VERSION ""

NS_ :

BS_:

BU_: ACU ALC BCM ESCL HFM HPCU HVAC_CU LCU_ADB LCU_MBL MainLiB12V USM eRDC_L eRDC_R

BO_ 32 ACU_A102: 8 ACU
  SG_ AirbagCrashOrder_v3 : 5|6@0+ (1,0) [0|0] "" BCM,HFM,HVAC_CU,eRDC_L,eRDC_R
  SG_ Clock_ACU_A102 : 7|2@0+ (1,0) [0|3] "" BCM,eRDC_L,eRDC_R
  SG_ DirectionRear2ndCollision : 8|1@0+ (1,0) [0|0] "" BCM
  SG_ DirectionRollover2ndCollision : 9|1@0+ (1,0) [0|0] "" BCM
  SG_ DataSetCollisionValidity : 10|1@0+ (1,0) [0|0] "" BCM
  SG_ SeatBeltStatusDriver1stCollision : 12|2@0+ (1,0) [0|0] "" BCM
  SG_ SeatBeltStatusPass1stCollision : 14|2@0+ (1,0) [0|0] "" BCM
  SG_ DirectionLeft1stCollision : 15|1@0+ (1,0) [0|0] "" BCM
  SG_ PreRolloverDetection : 16|1@0+ (1,0) [0|0] "" BCM
  SG_ SeatBeltStatusDriver2ndCollision : 18|2@0+ (1,0) [0|0] "" BCM
  SG_ SeatBeltStatusPass2ndcollision : 20|2@0+ (1,0) [0|0] "" BCM
  SG_ DirectionLeft2ndCollision : 21|1@0+ (1,0) [0|0] "" BCM
  SG_ DirectionRight2ndCollision : 22|1@0+ (1,0) [0|0] "" BCM
  SG_ DirectionFront2ndCollision : 23|1@0+ (1,0) [0|0] "" BCM
  SG_ MaxDeltaVLongi1stCollision : 31|8@0+ (1,-100) [-100|100] "Kph" BCM
  SG_ MaxDeltaVLat1stCollision : 39|8@0+ (1,-100) [-100|100] "Kph" BCM
  SG_ MaxDeltaVLongi2ndCollision : 47|8@0+ (1,-100) [-100|100] "Kph" BCM
  SG_ MaxDeltaVLat2ndCollision : 55|8@0+ (1,-100) [-100|100] "Kph" BCM
  SG_ DirectionRollover1stCollision : 56|1@0+ (1,0) [0|0] "" BCM
  SG_ RolloverDetection : 57|1@0+ (1,0) [0|0] "" BCM
  SG_ CrashLevelType : 60|3@0+ (1,0) [0|0] "" BCM
  SG_ DirectionRight1stCollision : 61|1@0+ (1,0) [0|0] "" BCM
  SG_ DirectionFront1stCollision : 62|1@0+ (1,0) [0|0] "" BCM
  SG_ DirectionRear1stCollision : 63|1@0+ (1,0) [0|0] "" BCM

BO_ 114 EBA_A101: 7 BCM
  SG_ BrakePedalPosition : 23|12@0+ (0.03125,0) [0|100] "%" ACU

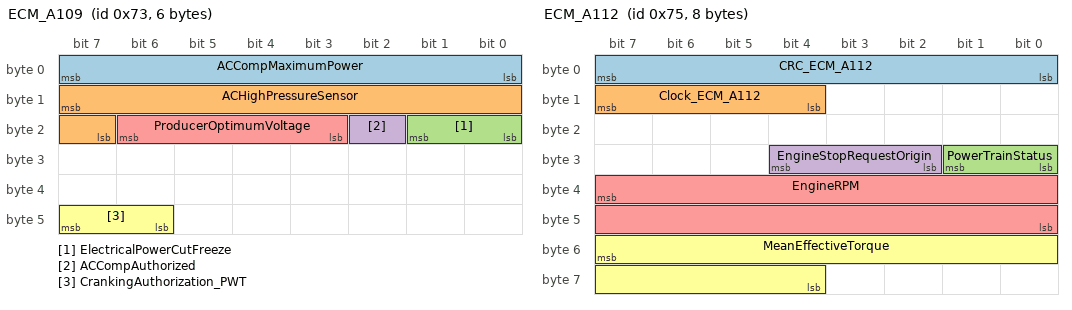
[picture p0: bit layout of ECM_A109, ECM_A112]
BO_ 115 ECM_A109: 6 BCM
  SG_ ACCompMaximumPower : 7|8@0+ (25,0) [0|6350] "W" HVAC_CU
  SG_ ACHighPressureSensor : 15|9@0+ (0.1,0) [0|51] "bar" HPCU,HVAC_CU
  SG_ ElectricalPowerCutFreeze : 17|2@0+ (1,0) [0|0] "" HVAC_CU
  SG_ ACCompAuthorized : 18|1@0+ (1,0) [0|0] "" HVAC_CU,USM
  SG_ ProducerOptimumVoltage : 22|4@0+ (0.5,12) [12|16] "V" USM
  SG_ CrankingAuthorization_PWT : 47|2@0+ (1,0) [0|0] "" USM

BO_ 116 ECM_A110: 8 BCM
  SG_ RawSensor : 17|10@0+ (0.125,0) [0|125] "%" ACU
  SG_ StopAutoPhase : 47|3@0+ (1,0) [0|0] "" HVAC_CU

BO_ 117 ECM_A112: 8 BCM
  SG_ CRC_ECM_A112 : 7|8@0+ (1,0) [0|255] "" USM
  SG_ Clock_ECM_A112 : 15|4@0+ (1,0) [0|15] "" USM
  SG_ PowerTrainStatus : 25|2@0+ (1,0) [0|0] "" HFM,HVAC_CU,USM
  SG_ EngineStopRequestOrigin : 28|3@0+ (1,0) [0|0] "" HFM,HVAC_CU
  SG_ EngineRPM : 39|16@0+ (0.125,0) [0|8191.75] "rpm" ACU,HVAC_CU,LCU_MBL
  SG_ MeanEffectiveTorque : 55|12@0+ (0.5,-400) [-400|1647] "Nm" HVAC_CU

BO_ 168 STRG_A1: 7 BCM
  SG_ CRC_STRG_A1 : 7|8@0+ (1,0) [0|255] "" USM
  SG_ Clock_STRG_A1 : 15|4@0+ (1,0) [0|15] "" USM
  SG_ SteeringWheelAngleRaw : 22|15@0+ (0.1,-1080) [-1080|1080] "°" ACU,LCU_ADB,LCU_MBL,USM
  SG_ SwaSensorInternalStatus : 39|3@0+ (1,0) [0|0] "" LCU_ADB,LCU_MBL,USM

BO_ 171 VDC_A6: 8 BCM
  SG_ CRC_VDC_A6 : 7|8@0+ (1,0) [0|255] "" USM
  SG_ YawRateCorrected : 10|11@0+ (0.1,-100) [-100|100] "°/s" ACU
  SG_ Clock_VDC_A6 : 15|4@0+ (1,0) [0|15] "" USM
  SG_ SteerRackPinionAngleCorrect : 39|15@0+ (0.1,-1080) [-1080|1080] "°" LCU_ADB,LCU_MBL,USM
  SG_ YawRateRaw : 55|11@0+ (0.1,-100) [-100|100] "°/s" LCU_ADB

BO_ 255 VDC_A10: 6 BCM
  SG_ AEB_BrakingPerformanceStatus : 9|2@0+ (1,0) [0|0] "" ACU
  SG_ BrakePedalPressedByDriver : 42|2@0+ (1,0) [0|0] "" ACU

BO_ 303 ATCU_A108: 7 BCM
  SG_ CRC_ATCU_A108 : 7|8@0+ (1,0) [0|255] "" USM
  SG_ Clock_ATCU_A108 : 15|4@0+ (1,0) [0|15] "" USM
  SG_ InputShaftRevolution : 16|16@0+ (1,0) [0|65534] "rpm" ACU
  SG_ GearLeverPosition_v2 : 20|4@0+ (1,0) [0|0] "" ACU,HVAC_CU,USM,eRDC_L,eRDC_R
  SG_ AT_StartingAuthorization : 23|3@0+ (1,0) [0|0] "" USM

BO_ 380 STRG_A2: 7 BCM
  SG_ CRC_STRG_A2 : 7|8@0+ (1,0) [0|255] "" USM
  SG_ Clock_STRG_A2 : 15|4@0+ (1,0) [0|15] "" USM
  SG_ SteeringWheelAngleRaw_EPS : 22|15@0+ (0.1,-1080) [-1080|1080] "°" ACU,LCU_ADB,USM
  SG_ SwaSensorInternalStatus_EPS : 39|3@0+ (1,0) [0|0] "" LCU_ADB,USM

BO_ 504 EPKB_R1: 3 BCM
  SG_ EPB_ActivationCounterMemorized : 7|20@0+ (1,0) [0|1000000] "-" USM

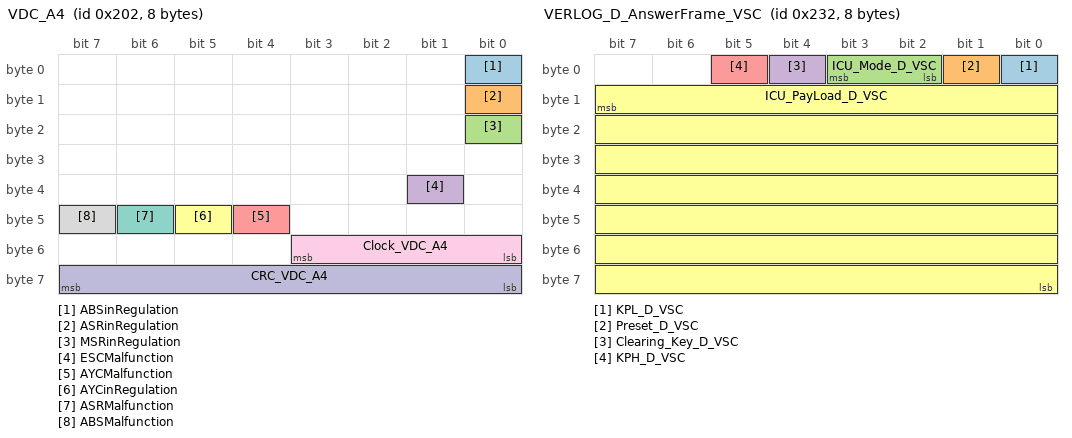
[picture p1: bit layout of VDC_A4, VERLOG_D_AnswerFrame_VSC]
BO_ 514 VDC_A4: 8 BCM
  SG_ ABSinRegulation : 0|1@0+ (1,0) [0|0] "" ACU
  SG_ ASRinRegulation : 8|1@0+ (1,0) [0|0] "" ACU
  SG_ MSRinRegulation : 16|1@0+ (1,0) [0|0] "" ACU
  SG_ ESCMalfunction : 33|1@0+ (1,0) [0|0] "" ACU
  SG_ AYCMalfunction : 44|1@0+ (1,0) [0|0] "" ACU
  SG_ AYCinRegulation : 45|1@0+ (1,0) [0|0] "" ACU
  SG_ ASRMalfunction : 46|1@0+ (1,0) [0|0] "" ACU
  SG_ ABSMalfunction : 47|1@0+ (1,0) [0|0] "" ACU
  SG_ Clock_VDC_A4 : 51|4@0+ (1,0) [0|15] "" ACU
  SG_ CRC_VDC_A4 : 63|8@0+ (1,0) [0|255] "" ACU

BO_ 538 HEVC_A125: 4 BCM
  SG_ ePedalStatus : 17|1@0+ (1,0) [0|0] "" ACU

BO_ 546 USM_A102: 4 USM
  SG_ ProducerVoltageRequest : 7|8@0+ (0.025,11.7) [11.7|16] "V" BCM
  SG_ BatteryCurrentSensorValue : 15|10@0+ (1,-320) [-320|320] "A" BCM
  SG_ ElecPowerConsumedByAux_v2 : 21|6@0+ (80,0) [0|4960] "W" BCM
  SG_ ACCompValveDefault : 29|1@0+ (1,0) [0|0] "" BCM,HVAC_CU
  SG_ ACCompClutchStatus : 31|1@0+ (1,0) [0|0] "" BCM,HVAC_CU

BO_ 562 VERLOG_D_AnswerFrame_VSC: 8 HFM
  SG_ KPL_D_VSC : 0|1@0+ (1,0) [0|0] "" BCM
  SG_ Preset_D_VSC : 1|1@0+ (1,0) [0|0] "" BCM
  SG_ ICU_Mode_D_VSC : 3|2@0+ (1,0) [0|0] "" BCM
  SG_ Clearing_Key_D_VSC : 4|1@0+ (1,0) [0|0] "" BCM
  SG_ KPH_D_VSC : 5|1@0+ (1,0) [0|0] "" BCM
  SG_ ICU_PayLoad_D_VSC : 15|56@0+ (1,0) [0|0] "" BCM

BO_ 566 VERLOG_D_ChallengeFrame: 8 BCM
  SG_ TPU_Mode_D : 1|2@0+ (1,0) [0|0] "" HFM
  SG_ VerlogStatus_D : 2|1@0+ (1,0) [0|0] "" HFM
  SG_ SREM_D : 3|1@0+ (1,0) [0|0] "" HFM
  SG_ Version_D : 5|2@0+ (1,0) [0|0] "" HFM
  SG_ TPU_Payload_D : 15|56@0+ (1,0) [0|0] "" HFM

BO_ 604 EPKB_A1: 4 BCM
  SG_ ParkingBrakeMalfunctionStatus : 23|1@0+ (1,0) [0|0] "" ACU

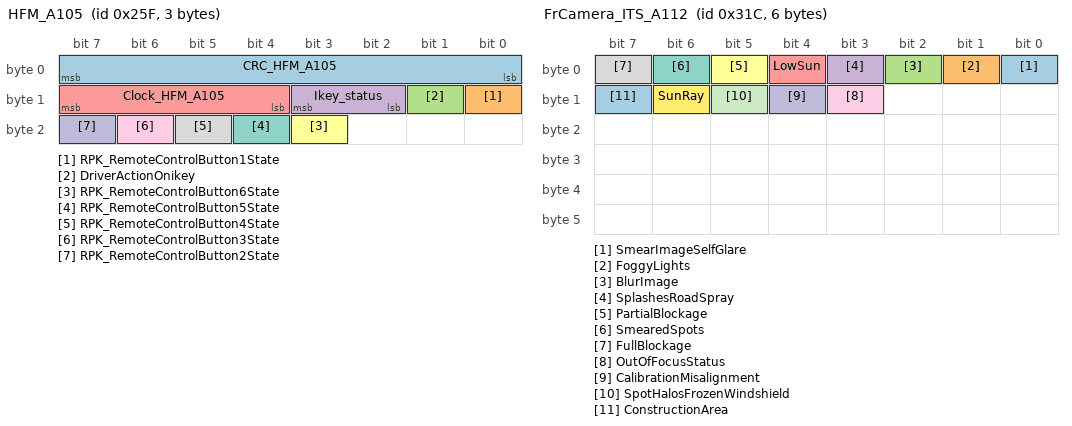
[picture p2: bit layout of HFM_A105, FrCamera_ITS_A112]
BO_ 607 HFM_A105: 3 HFM
  SG_ CRC_HFM_A105 : 7|8@0+ (1,0) [0|255] "" BCM
  SG_ RPK_RemoteControlButton1State : 8|1@0+ (1,0) [0|0] "" BCM
  SG_ DriverActionOnikey : 9|1@0+ (1,0) [0|0] "" BCM
  SG_ Ikey_status : 11|2@0+ (1,0) [0|0] "" BCM
  SG_ Clock_HFM_A105 : 15|4@0+ (1,0) [0|15] "" BCM
  SG_ RPK_RemoteControlButton6State : 19|1@0+ (1,0) [0|0] "" BCM
  SG_ RPK_RemoteControlButton5State : 20|1@0+ (1,0) [0|0] "" BCM
  SG_ RPK_RemoteControlButton4State : 21|1@0+ (1,0) [0|0] "" BCM
  SG_ RPK_RemoteControlButton3State : 22|1@0+ (1,0) [0|0] "" BCM
  SG_ RPK_RemoteControlButton2State : 23|1@0+ (1,0) [0|0] "" BCM

BO_ 650 VDC_A9: 8 BCM
  SG_ VehicleSpeed : 39|16@0+ (0.01,0) [0|655.34] "km/h" ACU,ESCL,HFM,HPCU,HVAC_CU,LCU_ADB,LCU_MBL,USM,eRDC_L,eRDC_R
  SG_ VehicleSpeedClock : 51|4@0+ (1,0) [0|15] "" ACU,ESCL,HFM,USM,eRDC_L,eRDC_R
  SG_ VehicleSpeedCRC : 63|8@0+ (1,0) [0|255] "" ACU,ESCL,HFM,USM,eRDC_L,eRDC_R

BO_ 791 HVAC_A1: 8 HVAC_CU
  SG_ BlowerFanMotorStatus_AC : 0|1@0+ (1,0) [0|0] "" BCM
  SG_ ACCompValveRequest : 7|7@0+ (0.01,0) [0|1] "A" BCM,USM
  SG_ FrontDefrostRequest : 8|1@0+ (1,0) [0|0] "" BCM
  SG_ EngineFanSpeedRequestPWM_AC : 15|7@0+ (1,0) [0|100] "%" BCM
  SG_ ACCompRequest : 16|1@0+ (1,0) [0|0] "" BCM
  SG_ MinimumVoltagebyAC : 19|3@0+ (0.5,12) [12|15] "V" USM
  SG_ PTCNumberThermalRequest : 23|4@0+ (1,0) [0|0] "" BCM
  SG_ PumpActivationRequest : 25|2@0+ (1,0) [0|0] "" USM
  SG_ AC_StopAutoForbidden : 29|2@0+ (1,0) [0|0] "" BCM
  SG_ AC_ClutchOpenForbidden : 31|2@0+ (1,0) [0|0] "" BCM
  SG_ ClimAT_EcoCustomAllowed : 32|1@0+ (1,0) [0|0] "" BCM
  SG_ RearDefrostRequest : 36|1@0+ (1,0) [0|0] "" BCM
  SG_ CoolerHilimitRequestForCVT : 37|1@0+ (1,0) [0|0] "" BCM
  SG_ VoltageRatebyAC : 39|2@0+ (1,0) [0|0] "" USM
  SG_ AC_eCompInterlockHVconnector : 41|2@0+ (1,0) [0|0] "" BCM
  SG_ ISS_EcoActivationState : 43|2@0+ (1,0) [0|0] "" BCM
  SG_ AirCondEcoActivationState : 45|2@0+ (1,0) [0|0] "" BCM
  SG_ AC_ePTCInterlockHVconnector : 47|2@0+ (1,0) [0|0] "" BCM
  SG_ ClimECOModeStatusDisplay : 52|2@0+ (1,0) [0|0] "" BCM
  SG_ HVAC_ZEVmodeICEngineStartRequest : 53|1@0+ (1,0) [0|0] "" BCM
  SG_ ACCompPowerUsed_HVAC_v2 : 63|8@0+ (25,0) [0|6350] "W" BCM

BO_ 796 FrCamera_ITS_A112: 6 BCM
  SG_ SmearImageSelfGlare : 0|1@0+ (1,0) [0|0] "" LCU_ADB
  SG_ FoggyLights : 1|1@0+ (1,0) [0|0] "" LCU_ADB
  SG_ BlurImage : 2|1@0+ (1,0) [0|0] "" LCU_ADB
  SG_ SplashesRoadSpray : 3|1@0+ (1,0) [0|0] "" LCU_ADB
  SG_ LowSun : 4|1@0+ (1,0) [0|0] "" LCU_ADB
  SG_ PartialBlockage : 5|1@0+ (1,0) [0|0] "" LCU_ADB
  SG_ SmearedSpots : 6|1@0+ (1,0) [0|0] "" LCU_ADB
  SG_ FullBlockage : 7|1@0+ (1,0) [0|0] "" LCU_ADB
  SG_ OutOfFocusStatus : 11|1@0+ (1,0) [0|0] "" LCU_ADB
  SG_ CalibrationMisalignment : 12|1@0+ (1,0) [0|0] "" LCU_ADB
  SG_ SpotHalosFrozenWindshield : 13|1@0+ (1,0) [0|0] "" LCU_ADB
  SG_ SunRay : 14|1@0+ (1,0) [0|0] "" LCU_ADB
  SG_ ConstructionArea : 15|1@0+ (1,0) [0|0] "" LCU_ADB

BO_ 806 USM_R3: 2 USM
  SG_ FrontHeightBody : 7|8@0+ (1.5,-190.5) [-190.5|190.5] "mm" BCM
  SG_ RearHeightBody : 15|8@0+ (1.5,-190.5) [-190.5|190.5] "mm" BCM

BO_ 811 BCM_R18: 6 BCM
  SG_ MinimumVoltageByBCM : 26|3@0+ (0.5,12) [12|15] "V" USM
  SG_ BCM_ACCompRequest : 29|1@0+ (1,0) [0|0] "" HVAC_CU
  SG_ VoltageRateByBCM : 31|2@0+ (1,0) [0|0] "" USM
  SG_ BCM_PumpActivationRequest : 35|2@0+ (1,0) [0|0] "" USM

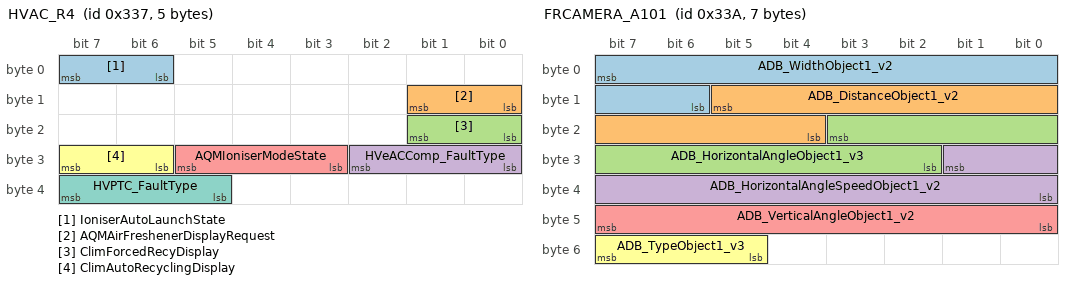
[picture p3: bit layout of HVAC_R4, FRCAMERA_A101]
BO_ 823 HVAC_R4: 5 HVAC_CU
  SG_ IoniserAutoLaunchState : 7|2@0+ (1,0) [0|0] "" BCM
  SG_ AQMAirFreshenerDisplayRequest : 9|2@0+ (1,0) [0|0] "" BCM
  SG_ ClimForcedRecyDisplay : 17|2@0+ (1,0) [0|0] "" BCM
  SG_ HVeACComp_FaultType : 26|3@0+ (1,0) [0|0] "" BCM
  SG_ AQMIoniserModeState : 29|3@0+ (1,0) [0|0] "" BCM
  SG_ ClimAutoRecyclingDisplay : 31|2@0+ (1,0) [0|0] "" BCM
  SG_ HVPTC_FaultType : 39|3@0+ (1,0) [0|0] "" BCM

BO_ 826 FRCAMERA_A101: 7 BCM
  SG_ ADB_WidthObject1_v2 : 7|10@0+ (0.1,0) [0|52] "°" LCU_ADB
  SG_ ADB_DistanceObject1_v2 : 13|10@0+ (1,0) [0|1022] "m" LCU_ADB
  SG_ ADB_HorizontalAngleObject1_v3 : 19|10@0+ (0.1,-50) [-50|50] "°" LCU_ADB
  SG_ ADB_HorizontalAngleSpeedObject1_v2 : 25|10@0+ (0.1,-30) [-30|30] "°/s" LCU_ADB
  SG_ ADB_VerticalAngleObject1_v2 : 47|8@0+ (0.1,-10) [-10|10] "°" LCU_ADB
  SG_ ADB_TypeObject1_v3 : 55|3@0+ (1,0) [0|0] "" LCU_ADB

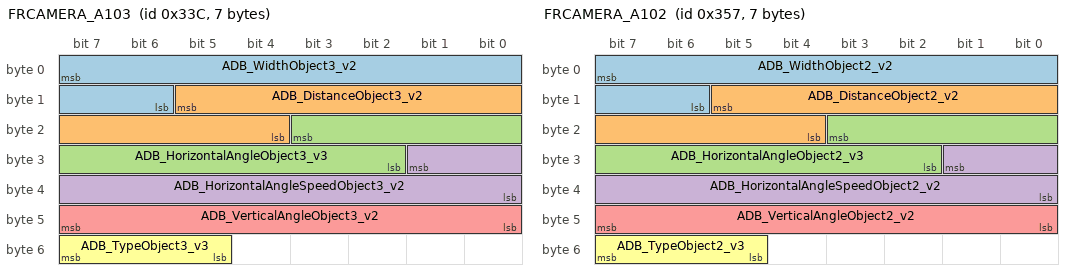
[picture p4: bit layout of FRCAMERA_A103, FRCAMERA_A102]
BO_ 828 FRCAMERA_A103: 7 BCM
  SG_ ADB_WidthObject3_v2 : 7|10@0+ (0.1,0) [0|52] "°" LCU_ADB
  SG_ ADB_DistanceObject3_v2 : 13|10@0+ (1,0) [0|1022] "m" LCU_ADB
  SG_ ADB_HorizontalAngleObject3_v3 : 19|10@0+ (0.1,-50) [-50|50] "°" LCU_ADB
  SG_ ADB_HorizontalAngleSpeedObject3_v2 : 25|10@0+ (0.1,-30) [-30|30] "°/s" LCU_ADB
  SG_ ADB_VerticalAngleObject3_v2 : 47|8@0+ (0.1,-10) [-10|10] "°" LCU_ADB
  SG_ ADB_TypeObject3_v3 : 55|3@0+ (1,0) [0|0] "" LCU_ADB

BO_ 855 FRCAMERA_A102: 7 BCM
  SG_ ADB_WidthObject2_v2 : 7|10@0+ (0.1,0) [0|52] "°" LCU_ADB
  SG_ ADB_DistanceObject2_v2 : 13|10@0+ (1,0) [0|1022] "m" LCU_ADB
  SG_ ADB_HorizontalAngleObject2_v3 : 19|10@0+ (0.1,-50) [-50|50] "°" LCU_ADB
  SG_ ADB_HorizontalAngleSpeedObject2_v2 : 25|10@0+ (0.1,-30) [-30|30] "°/s" LCU_ADB
  SG_ ADB_VerticalAngleObject2_v2 : 47|8@0+ (0.1,-10) [-10|10] "°" LCU_ADB
  SG_ ADB_TypeObject2_v3 : 55|3@0+ (1,0) [0|0] "" LCU_ADB

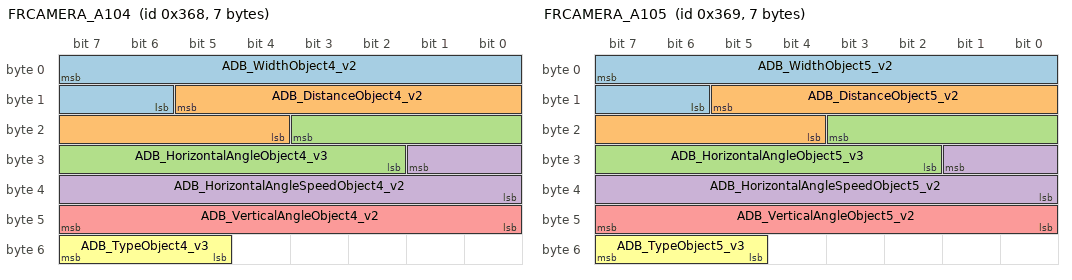
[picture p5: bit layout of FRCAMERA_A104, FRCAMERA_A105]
BO_ 872 FRCAMERA_A104: 7 BCM
  SG_ ADB_WidthObject4_v2 : 7|10@0+ (0.1,0) [0|52] "°" LCU_ADB
  SG_ ADB_DistanceObject4_v2 : 13|10@0+ (1,0) [0|1022] "m" LCU_ADB
  SG_ ADB_HorizontalAngleObject4_v3 : 19|10@0+ (0.1,-50) [-50|50] "°" LCU_ADB
  SG_ ADB_HorizontalAngleSpeedObject4_v2 : 25|10@0+ (0.1,-30) [-30|30] "°/s" LCU_ADB
  SG_ ADB_VerticalAngleObject4_v2 : 47|8@0+ (0.1,-10) [-10|10] "°" LCU_ADB
  SG_ ADB_TypeObject4_v3 : 55|3@0+ (1,0) [0|0] "" LCU_ADB

BO_ 873 FRCAMERA_A105: 7 BCM
  SG_ ADB_WidthObject5_v2 : 7|10@0+ (0.1,0) [0|52] "°" LCU_ADB
  SG_ ADB_DistanceObject5_v2 : 13|10@0+ (1,0) [0|1022] "m" LCU_ADB
  SG_ ADB_HorizontalAngleObject5_v3 : 19|10@0+ (0.1,-50) [-50|50] "°" LCU_ADB
  SG_ ADB_HorizontalAngleSpeedObject5_v2 : 25|10@0+ (0.1,-30) [-30|30] "°/s" LCU_ADB
  SG_ ADB_VerticalAngleObject5_v2 : 47|8@0+ (0.1,-10) [-10|10] "°" LCU_ADB
  SG_ ADB_TypeObject5_v3 : 55|3@0+ (1,0) [0|0] "" LCU_ADB

BO_ 878 ECM_INIT_INFO_RN1: 7 BCM
  SG_ StarterActivationCounter : 7|16@0+ (10,0) [0|600000] "" USM
  SG_ HPPumpActivationCounter : 23|16@0+ (10,0) [0|600000] "" USM
  SG_ BSGActivationCounter : 39|21@0+ (1,0) [0|1500000] "nb of restart" USM

BO_ 893 EPS_A103: 3 BCM
  SG_ MinimumVoltagebySteer : 5|3@0+ (0.5,12) [12|15] "V" USM

BO_ 908 HFM_N101: 4 HFM
  SG_ VirutalKeyRKE_Request : 7|28@0+ (1,0) [0|0] "" BCM

BO_ 911 HVAC_A111: 1 HVAC_CU
  SG_ FrontRightDefrostRequest : 6|1@0+ (1,0) [0|0] "" BCM
  SG_ FrontLeftDefrostRequest : 7|1@0+ (1,0) [0|0] "" BCM

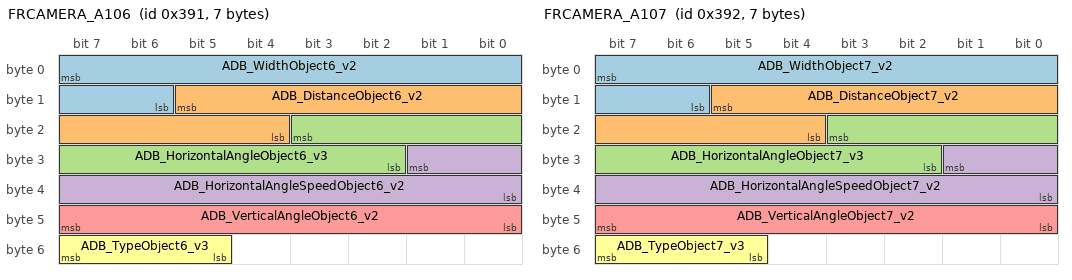
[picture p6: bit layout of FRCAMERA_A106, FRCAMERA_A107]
BO_ 913 FRCAMERA_A106: 7 BCM
  SG_ ADB_WidthObject6_v2 : 7|10@0+ (0.1,0) [0|52] "°" LCU_ADB
  SG_ ADB_DistanceObject6_v2 : 13|10@0+ (1,0) [0|1022] "m" LCU_ADB
  SG_ ADB_HorizontalAngleObject6_v3 : 19|10@0+ (0.1,-50) [-50|50] "°" LCU_ADB
  SG_ ADB_HorizontalAngleSpeedObject6_v2 : 25|10@0+ (0.1,-30) [-30|30] "°/s" LCU_ADB
  SG_ ADB_VerticalAngleObject6_v2 : 47|8@0+ (0.1,-10) [-10|10] "°" LCU_ADB
  SG_ ADB_TypeObject6_v3 : 55|3@0+ (1,0) [0|0] "" LCU_ADB

BO_ 914 FRCAMERA_A107: 7 BCM
  SG_ ADB_WidthObject7_v2 : 7|10@0+ (0.1,0) [0|52] "°" LCU_ADB
  SG_ ADB_DistanceObject7_v2 : 13|10@0+ (1,0) [0|1022] "m" LCU_ADB
  SG_ ADB_HorizontalAngleObject7_v3 : 19|10@0+ (0.1,-50) [-50|50] "°" LCU_ADB
  SG_ ADB_HorizontalAngleSpeedObject7_v2 : 25|10@0+ (0.1,-30) [-30|30] "°/s" LCU_ADB
  SG_ ADB_VerticalAngleObject7_v2 : 47|8@0+ (0.1,-10) [-10|10] "°" LCU_ADB
  SG_ ADB_TypeObject7_v3 : 55|3@0+ (1,0) [0|0] "" LCU_ADB

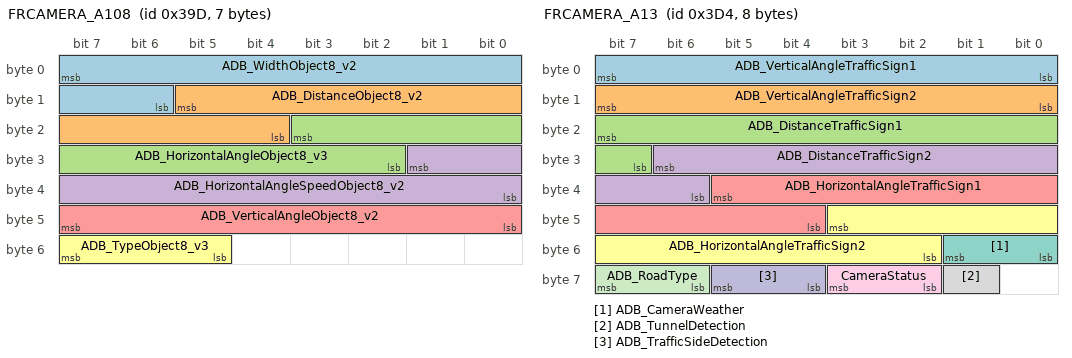
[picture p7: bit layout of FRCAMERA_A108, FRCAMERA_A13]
BO_ 925 FRCAMERA_A108: 7 BCM
  SG_ ADB_WidthObject8_v2 : 7|10@0+ (0.1,0) [0|52] "°" LCU_ADB
  SG_ ADB_DistanceObject8_v2 : 13|10@0+ (1,0) [0|1022] "m" LCU_ADB
  SG_ ADB_HorizontalAngleObject8_v3 : 19|10@0+ (0.1,-50) [-50|50] "°" LCU_ADB
  SG_ ADB_HorizontalAngleSpeedObject8_v2 : 25|10@0+ (0.1,-30) [-30|30] "°/s" LCU_ADB
  SG_ ADB_VerticalAngleObject8_v2 : 47|8@0+ (0.1,-10) [-10|10] "°" LCU_ADB
  SG_ ADB_TypeObject8_v3 : 55|3@0+ (1,0) [0|0] "" LCU_ADB

BO_ 930 ADAS_A123: 6 BCM
  SG_ ADAS_DefoggingModeRequest : 15|1@0+ (1,0) [0|0] "" HVAC_CU
  SG_ DetectedLatMovingObject : 16|1@0+ (1,0) [0|0] "" LCU_ADB
  SG_ OSE_R_RetentionReq2 : 43|3@0+ (1,0) [0|0] "" eRDC_R
  SG_ OSE_L_RetentionReq2 : 46|3@0+ (1,0) [0|0] "" eRDC_L

BO_ 934 AVM_A120: 3 BCM
  SG_ APA_StatusDisplay2 : 11|2@0+ (1,0) [0|0] "" ACU
  SG_ RPK_status : 21|2@0+ (1,0) [0|0] "" HFM
  SG_ iKeyPositionRequest : 23|1@0+ (1,0) [0|0] "" HFM

BO_ 939 EBA_A2: 4 BCM
  SG_ MinimumVoltageByCRBS : 7|3@0+ (0.5,12) [12|15] "V" USM
  SG_ EBA_MajorFailure : 18|1@0+ (1,0) [0|0] "" ACU

BO_ 941 BMS12V_A102: 2 BCM
  SG_ CRC_BMS12V_A102 : 7|8@0+ (1,0) [0|255] "" USM
  SG_ BMS12V_SafetyAlert : 11|2@0+ (1,0) [0|0] "" USM
  SG_ Clock_BMS12V_A102 : 15|4@0+ (1,0) [0|15] "" USM

BO_ 944 BCM_A117: 3 BCM
  SG_ RPES_Status : 23|3@0+ (1,0) [0|0] "" HFM

BO_ 962 SONAR_A118: 4 BCM
  SG_ APA_StatusDisplay : 11|2@0+ (1,0) [0|0] "" ACU

BO_ 970 BLM_A101: 1 BCM
  SG_ VirtualKeyActivationStatus : 5|1@0+ (1,0) [0|0] "" HFM

BO_ 977 CDM_A127: 3 BCM
  SG_ LiB_RLY_OFF_Inhibition : 23|1@0+ (1,0) [0|0] "" USM

BO_ 980 FRCAMERA_A13: 8 BCM
  SG_ ADB_VerticalAngleTrafficSign1 : 7|8@0+ (0.1,-10) [-10|10] "°" LCU_ADB
  SG_ ADB_VerticalAngleTrafficSign2 : 15|8@0+ (0.1,-10) [-10|10] "°" LCU_ADB
  SG_ ADB_DistanceTrafficSign1 : 23|9@0+ (0.5,0) [0|255] "m" LCU_ADB
  SG_ ADB_DistanceTrafficSign2 : 30|9@0+ (0.5,0) [0|255] "m" LCU_ADB
  SG_ ADB_HorizontalAngleTrafficSign1 : 37|10@0+ (0.1,-30) [-30|30] "°" LCU_ADB
  SG_ ADB_HorizontalAngleTrafficSign2 : 43|10@0+ (0.1,-30) [-30|30] "°" LCU_ADB
  SG_ ADB_CameraWeather : 49|2@0+ (1,0) [0|0] "" LCU_ADB
  SG_ ADB_TunnelDetection : 57|1@0+ (1,0) [0|0] "" LCU_ADB
  SG_ CameraStatus : 59|2@0+ (1,0) [0|0] "" LCU_ADB,USM
  SG_ ADB_TrafficSideDetection : 61|2@0+ (1,0) [0|0] "" LCU_ADB,USM
  SG_ ADB_RoadType : 63|2@0+ (1,0) [0|0] "" LCU_ADB,USM

BO_ 999 BCM_A105: 4 BCM
  SG_ Right_KeyAuthentResult : 12|1@0+ (1,0) [0|0] "" eRDC_R
  SG_ Left_KeyAuthentResult : 13|1@0+ (1,0) [0|0] "" eRDC_L

BO_ 1000 HFM_A101: 7 HFM
  SG_ RemoteHorn_HFM : 1|2@0+ (1,0) [0|0] "" BCM
  SG_ RemoteLight_HFM : 2|1@0+ (1,0) [0|0] "" BCM
  SG_ RKE_ID_DetectStatus : 7|3@0+ (1,0) [0|0] "" BCM
  SG_ IkeyfobInsideVehicleFound : 10|3@0+ (1,0) [0|0] "" BCM
  SG_ HFMBatTempoRequest : 11|1@0+ (1,0) [0|0] "" BCM
  SG_ APPRUN_ActivationState : 12|1@0+ (1,0) [0|0] "" BCM
  SG_ WAL_ActivationState : 13|1@0+ (1,0) [0|0] "" BCM
  SG_ IKeyRemoteUnProtectStatus : 16|1@0+ (1,0) [0|0] "" BCM
  SG_ TrunkCancelSwitchState : 17|1@0+ (1,0) [0|0] "" BCM
  SG_ IKeyAccessActivationState : 18|1@0+ (1,0) [0|0] "" BCM
  SG_ iKeyFobAuthentStatus : 21|3@0+ (1,0) [0|0] "" BCM
  SG_ HFM_Refuse_to_Sleep : 23|2@0+ (1,0) [0|0] "" BCM
  SG_ VPA_R_PSD_Request : 25|2@0+ (1,0) [0|0] "" BCM
  SG_ BackDoorHandleSwitchState : 26|1@0+ (1,0) [0|0] "" BCM
  SG_ RearRightHandleSwitchState : 27|1@0+ (1,0) [0|0] "" BCM
  SG_ RearLeftHandleSwitchState : 28|1@0+ (1,0) [0|0] "" BCM
  SG_ FrontRightHandleSwitchState : 29|1@0+ (1,0) [0|0] "" BCM
  SG_ FrontLeftHandleSwitchState : 30|1@0+ (1,0) [0|0] "" BCM
  SG_ RESpresSoak_ProgCancel : 31|1@0+ (1,0) [0|0] "" BCM
  SG_ RearZonePollingResult : 33|2@0+ (1,0) [0|0] "" BCM
  SG_ VPA_L_PSD_Request : 35|2@0+ (1,0) [0|0] "" BCM
  SG_ UserIdent_Ikey : 39|4@0+ (1,0) [0|0] "" BCM
  SG_ IkeyfobInsideVehicleFound_VK : 42|3@0+ (1,0) [0|0] "" BCM
  SG_ VKAuthRequest : 45|1@0+ (1,0) [0|0] "" BCM
  SG_ VehicleInsideKeyIdentResult : 47|2@0+ (1,0) [0|0] "" BCM
  SG_ OutsideZoneKeyIdentResult : 53|2@0+ (1,0) [0|0] "" BCM
  SG_ OutsideZonePollingResult : 55|2@0+ (1,0) [0|0] "" BCM

BO_ 1010 ParkOut_ATCU_Frame: 1 BCM
  SG_ ATCU_ParkOutPairingStatus : 5|1@0+ (1,0) [0|0] "" HFM
  SG_ ATCU_ParkOutAntiScanningStatus : 6|1@0+ (1,0) [0|0] "" HFM
  SG_ ATCU_ParkOutAuthorizationStatus : 7|1@0+ (1,0) [0|0] "" HFM

BO_ 1011 VKM_N107: 6 BCM
  SG_ InsideIkeyfobSearchRequest : 47|1@0+ (1,0) [0|0] "" HFM

BO_ 1012 TCU_A101: 7 BCM
  SG_ ECALL_State_EDR : 9|2@0+ (1,0) [0|0] "" ACU

BO_ 1020 BMS48V_A103: 3 BCM
  SG_ CRC_BMS48V_A103 : 7|8@0+ (1,0) [0|255] "" USM
  SG_ Clock_BMS48V_A103 : 15|4@0+ (1,0) [0|15] "" USM
  SG_ MinimumSafetyEnergyLevel_48V : 23|2@0+ (1,0) [0|0] "" USM

BO_ 1021 HNS_A101: 3 BCM
  SG_ HNS_Failure_status : 11|2@0+ (1,0) [0|0] "" USM
  SG_ HNS_StopAutoForbidden : 21|1@0+ (1,0) [0|0] "" USM
  SG_ HNS_Switching_Status : 23|2@0+ (1,0) [0|0] "" USM

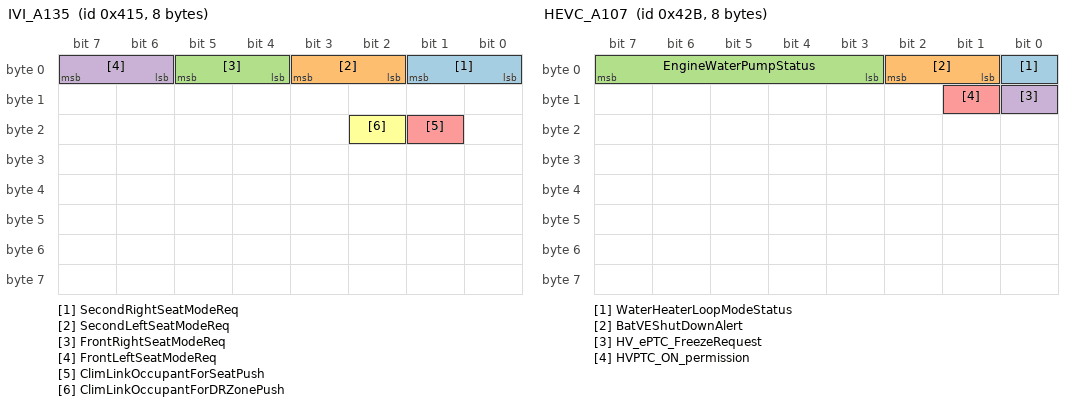
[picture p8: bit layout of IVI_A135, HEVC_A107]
BO_ 1045 IVI_A135: 8 BCM
  SG_ SecondRightSeatModeReq : 1|2@0+ (1,0) [0|0] "" HVAC_CU
  SG_ SecondLeftSeatModeReq : 3|2@0+ (1,0) [0|0] "" HVAC_CU
  SG_ FrontRightSeatModeReq : 5|2@0+ (1,0) [0|0] "" HVAC_CU
  SG_ FrontLeftSeatModeReq : 7|2@0+ (1,0) [0|0] "" HVAC_CU
  SG_ ClimLinkOccupantForSeatPush : 17|1@0+ (1,0) [0|1] "-" HVAC_CU
  SG_ ClimLinkOccupantForDRZonePush : 18|1@0+ (1,0) [0|1] "-" HVAC_CU

BO_ 1049 AAM_R101: 2 BCM
  SG_ VoltageRateByAAM : 4|2@0+ (1,0) [0|0] "" USM
  SG_ MinimumVoltageByAAM : 7|3@0+ (0.5,12) [12|15] "V" USM

BO_ 1054 USM_A105: 2 USM
  SG_ EEM_Dynamic_PowerLimitation : 5|3@0+ (1,0) [0|0] "" BCM,HVAC_CU
  SG_ HVlightChargeAuthorization : 6|1@0+ (1,0) [0|0] "" BCM
  SG_ FirstStartBSGSelection : 7|1@0+ (1,0) [0|0] "" BCM
  SG_ Battery_StorageTerminalTemp : 15|8@0+ (1,-40) [-40|100] "?" BCM

BO_ 1055 HEVC_R129: 8 BCM
  SG_ TIAlertStatusForHVAC : 7|1@0+ (1,0) [0|0] "" HVAC_CU
  SG_ VehicleSoakTime : 18|10@0+ (1,0) [0|1022] "min" HVAC_CU

BO_ 1058 FRCAMERA_A111: 5 BCM
  SG_ ADB_AmbientLight : 17|2@0+ (1,0) [0|0] "" LCU_ADB

BO_ 1064 HEVC_A104: 7 BCM
  SG_ HVbatteryTemperature : 7|7@0+ (1,-40) [-40|80] "°C" HVAC_CU
  SG_ RE_ElecMachineSpeed_EDR : 47|12@0+ (10,-20000) [-20000|20000] "rpm" ACU
  SG_ EEM_LoB_PowerLimitationRequest : 48|1@0+ (1,0) [0|0] "" USM
  SG_ HVcoolingLoopValveStatus : 51|2@0+ (1,0) [0|0] "" HVAC_CU

BO_ 1065 HEVC_A105: 8 BCM
  SG_ HVBatteryCoolingLoopTemperature : 7|8@0+ (1,-50) [-50|130] "°C" HVAC_CU
  SG_ BatteryCoolingForbidden : 56|1@0+ (1,0) [0|0] "" HVAC_CU

BO_ 1066 HEVC_A106: 8 BCM
  SG_ InputPower_License : 15|8@0+ (50,0) [0|10000] "W" HVAC_CU
  SG_ ElecMachineSpeed_EDR : 35|12@0+ (10,-20000) [-20000|20000] "rpm" ACU
  SG_ StatusOfHighVoltagePowerSupply : 37|1@0+ (1,0) [0|0] "" HVAC_CU

BO_ 1067 HEVC_A107: 8 BCM
  SG_ WaterHeaterLoopModeStatus : 0|1@0+ (1,0) [0|0] "" HVAC_CU
  SG_ BatVEShutDownAlert : 2|2@0+ (1,0) [0|0] "" HVAC_CU
  SG_ EngineWaterPumpStatus : 7|5@0+ (5,0) [0|100] "%" HVAC_CU
  SG_ HV_ePTC_FreezeRequest : 8|1@0+ (1,0) [0|0] "" HVAC_CU
  SG_ HVPTC_ON_permission : 9|1@0+ (1,0) [0|0] "" HVAC_CU

BO_ 1068 HEVC_A108: 8 BCM
  SG_ HVchargerStatus : 12|2@0+ (1,0) [0|0] "" HVAC_CU,USM
  SG_ VehicleTractionMode : 15|3@0+ (1,0) [0|0] "" HVAC_CU

BO_ 1070 HEVC_R101: 7 BCM
  SG_ UserSOC : 7|8@0+ (0.392157,0) [0|100] "%" HVAC_CU

BO_ 1076 HFM_A104: 8 HFM
  SG_ CRC_HFM_A104 : 7|8@0+ (1,0) [0|255] "" BCM
  SG_ BadgeBatteryLow : 8|1@0+ (1,0) [0|0] "" BCM
  SG_ UserIdent_RKE : 11|3@0+ (1,0) [0|0] "" BCM
  SG_ Clock_HFM_A104 : 15|4@0+ (1,0) [0|15] "" BCM
  SG_ HandFreeCode : 23|16@0+ (1,0) [0|65535] "" BCM
  SG_ UserIdent_HandFree : 34|3@0+ (1,0) [0|0] "" BCM
  SG_ HFM_RKE_Request : 39|5@0+ (1,0) [0|0] "" BCM
  SG_ ESCL_Status : 45|6@0+ (1,0) [0|0] "" BCM
  SG_ SteeringLockFailure : 47|2@0+ (1,0) [0|0] "" BCM
  SG_ PushtoStartButtonStatus : 48|1@0+ (1,0) [0|0] "" BCM
  SG_ SwitchOffSESDisturbers : 50|1@0+ (1,0) [0|0] "" BCM
  SG_ PushtoStartButton : 51|1@0+ (1,0) [0|0] "" BCM
  SG_ StopInductiveChargingRequest : 52|1@0+ (1,0) [0|0] "" BCM
  SG_ HFM_HandFree_Request_v2 : 59|4@0+ (1,0) [0|0] "" BCM
  SG_ CustomerDepartureDetected : 60|1@0+ (1,0) [0|0] "" BCM
  SG_ CustomerApproachDetected : 61|1@0+ (1,0) [0|0] "" BCM
  SG_ RESPreSoak_ImmediateReq_HFM : 63|2@0+ (1,0) [0|0] "" BCM

BO_ 1081 VDC_A114: 7 BCM
  SG_ DistanceTotalizer : 15|28@0+ (0.01,0) [0|2600000] "km" ACU,HFM,HPCU,HVAC_CU,LCU_ADB,LCU_MBL,USM,eRDC_L,eRDC_R

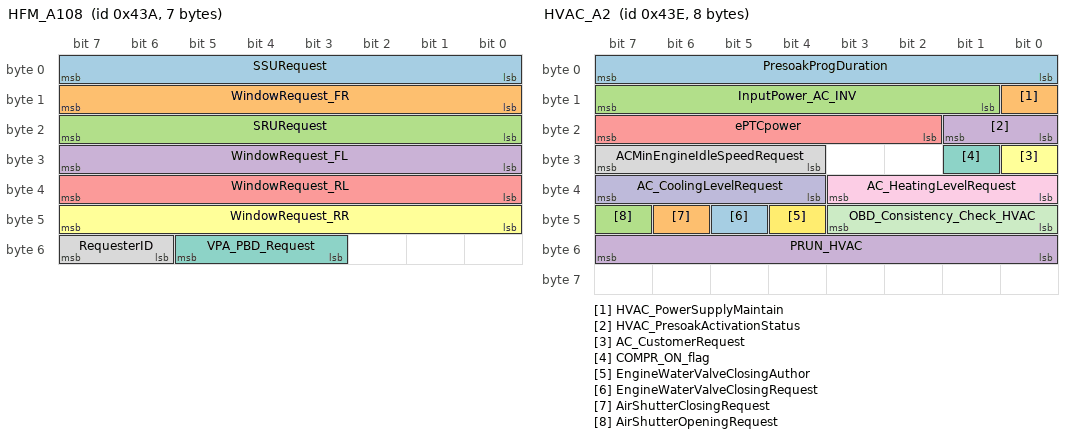
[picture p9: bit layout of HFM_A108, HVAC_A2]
BO_ 1082 HFM_A108: 7 HFM
  SG_ SSURequest : 7|8@0+ (1,0) [0|255] "Coding" BCM
  SG_ WindowRequest_FR : 15|8@0+ (1,0) [0|255] "Coding" BCM
  SG_ SRURequest : 23|8@0+ (1,0) [0|255] "Coding" BCM
  SG_ WindowRequest_FL : 31|8@0+ (1,0) [0|255] "Coding" BCM
  SG_ WindowRequest_RL : 39|8@0+ (1,0) [0|255] "Coding" BCM
  SG_ WindowRequest_RR : 47|8@0+ (1,0) [0|255] "Coding" BCM
  SG_ VPA_PBD_Request : 53|3@0+ (1,0) [0|0] "" BCM
  SG_ RequesterID : 55|2@0+ (1,0) [0|0] "" BCM

BO_ 1086 HVAC_A2: 8 HVAC_CU
  SG_ PresoakProgDuration : 7|8@0+ (1,0) [0|254] "min" BCM
  SG_ HVAC_PowerSupplyMaintain : 8|1@0+ (1,0) [0|0] "" BCM
  SG_ InputPower_AC_INV : 15|7@0+ (50,0) [0|5100] "W" BCM
  SG_ HVAC_PresoakActivationStatus : 17|2@0+ (1,0) [0|0] "" BCM
  SG_ ePTCpower : 23|6@0+ (250,0) [0|10000] "W" BCM
  SG_ AC_CustomerRequest : 24|1@0+ (1,0) [0|0] "" BCM
  SG_ COMPR_ON_flag : 25|1@0+ (1,0) [0|0] "" BCM
  SG_ ACMinEngineIdleSpeedRequest : 31|4@0+ (50,500) [500|1200] "rpm" BCM
  SG_ AC_HeatingLevelRequest : 35|4@0+ (1,0) [0|10] "wu" BCM
  SG_ AC_CoolingLevelRequest : 39|4@0+ (1,0) [0|10] "wu" BCM
  SG_ OBD_Consistency_Check_HVAC : 43|4@0+ (1,0) [0|15] "" BCM
  SG_ EngineWaterValveClosingAuthor : 44|1@0+ (1,0) [0|0] "" BCM
  SG_ EngineWaterValveClosingRequest : 45|1@0+ (1,0) [0|0] "" BCM
  SG_ AirShutterClosingRequest : 46|1@0+ (1,0) [0|0] "" BCM
  SG_ AirShutterOpeningRequest : 47|1@0+ (1,0) [0|0] "" BCM
  SG_ PRUN_HVAC : 55|8@0+ (1,0) [0|255] "" BCM

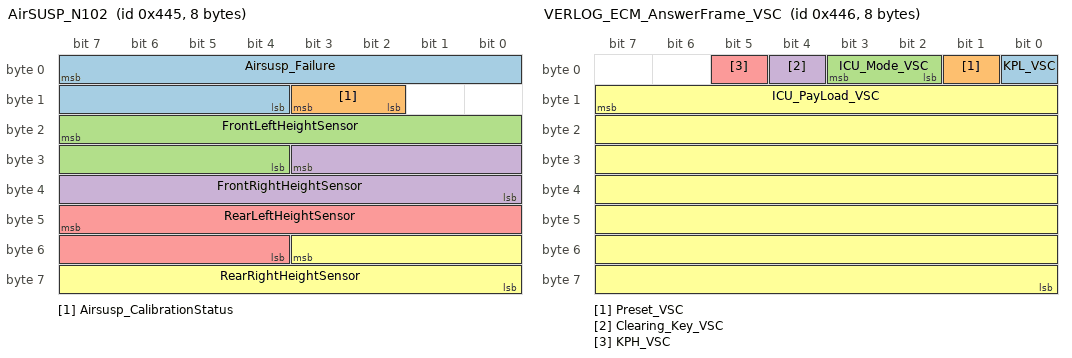
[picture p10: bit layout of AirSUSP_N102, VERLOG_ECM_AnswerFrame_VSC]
BO_ 1093 AirSUSP_N102: 8 BCM
  SG_ Airsusp_Failure : 7|12@0+ (1,0) [0|0] "" USM
  SG_ Airsusp_CalibrationStatus : 11|2@0+ (1,0) [0|0] "" USM
  SG_ FrontLeftHeightSensor : 23|12@0+ (0.025,0) [0|100] "%" USM
  SG_ FrontRightHeightSensor : 27|12@0+ (0.025,0) [0|100] "%" USM
  SG_ RearLeftHeightSensor : 47|12@0+ (0.025,0) [0|100] "%" USM
  SG_ RearRightHeightSensor : 51|12@0+ (0.025,0) [0|100] "%" USM

BO_ 1094 VERLOG_ECM_AnswerFrame_VSC: 8 HFM
  SG_ KPL_VSC : 0|1@0+ (1,0) [0|0] "" BCM
  SG_ Preset_VSC : 1|1@0+ (1,0) [0|0] "" BCM
  SG_ ICU_Mode_VSC : 3|2@0+ (1,0) [0|0] "" BCM
  SG_ Clearing_Key_VSC : 4|1@0+ (1,0) [0|0] "" BCM
  SG_ KPH_VSC : 5|1@0+ (1,0) [0|0] "" BCM
  SG_ ICU_PayLoad_VSC : 15|56@0+ (1,0) [0|0] "" BCM

BO_ 1096 VERLOG_ECM_ChallengeFrame: 8 BCM
  SG_ TPU_Mode : 1|2@0+ (1,0) [0|0] "" HFM
  SG_ VerlogStatus : 2|1@0+ (1,0) [0|0] "" HFM
  SG_ SREM : 3|1@0+ (1,0) [0|0] "" HFM
  SG_ Version : 5|2@0+ (1,0) [0|0] "" HFM
  SG_ TPU_Payload : 15|56@0+ (1,0) [0|0] "" HFM

BO_ 1099 ATCU_A109: 8 BCM
  SG_ ATCVTFail : 48|1@0+ (1,0) [0|0] "" LCU_ADB,LCU_MBL

BO_ 1101 BCM_A107: 5 BCM
  SG_ WheelStateRL_twin : 36|3@0+ (1,0) [0|0] "" ACU
  SG_ WheelStateRR_twin : 39|3@0+ (1,0) [0|0] "" ACU

BO_ 1103 BCM_A109: 8 BCM
  SG_ CockpitLocked_State : 40|1@0+ (1,0) [0|0] "" HFM
  SG_ Right_iKeyFobAuthent_Request : 51|1@0+ (1,0) [0|0] "" HFM
  SG_ Left_iKeyFobAuthent_Request : 52|1@0+ (1,0) [0|0] "" HFM
  SG_ LoadingAreaLocked_State : 55|1@0+ (1,0) [0|0] "" HFM

BO_ 1104 METER_A103: 8 BCM
  SG_ ExternalTempDisplayUnit : 8|1@0+ (1,0) [0|0] "" HVAC_CU
  SG_ FuelLevelDisplayed : 47|7@0+ (1,0) [0|80] "L" HFM,USM

BO_ 1105 METER_A104: 8 BCM
  SG_ DayNightForBacklights : 23|2@0+ (1,0) [0|0] "" HFM,HVAC_CU
  SG_ NightRheostatedLightMaxPercent : 31|8@0+ (0.4,0) [0|100] "%" HFM,HVAC_CU,eRDC_L,eRDC_R
  SG_ ExternalTemperature : 37|9@0+ (0.25,-50) [-50|70] "°C" ACU,HPCU,HVAC_CU,USM
  SG_ ParkingBrakeStatus : 39|2@0+ (1,0) [0|0] "" ACU,eRDC_L,eRDC_R
  SG_ LowBrakeFluidLevelStatus : 44|2@0+ (1,0) [0|0] "" ACU

BO_ 1106 METER_A108: 5 BCM
  SG_ DayNightStatusForB_Switches : 17|1@0+ (1,0) [0|0] "" HVAC_CU,eRDC_L,eRDC_R

BO_ 1107 USM_A101: 8 USM
  SG_ CRC_USM_A101 : 7|8@0+ (1,0) [0|255] "" BCM,HFM
  SG_ NeutralContact : 9|2@0+ (1,0) [0|0] "" BCM
  SG_ RearGearEngaged : 11|2@0+ (1,0) [0|0] "" BCM,LCU_ADB,LCU_MBL
  SG_ Clock_USM_A101 : 15|4@0+ (1,0) [0|15] "" BCM,HFM
  SG_ EngineHoodState : 17|2@0+ (1,0) [0|0] "" BCM,HVAC_CU
  SG_ BattWarnReq_Level_Hi_USM_v2 : 19|2@0+ (1,0) [0|0] "" BCM
  SG_ IgnitionSupplyConfirmation : 20|1@0+ (1,0) [0|0] "" ACU,BCM,HFM,LCU_ADB,eRDC_L,eRDC_R
  SG_ BattSetPointGeneratorStatus_V2 : 23|3@0+ (1,0) [0|0] "" BCM
  SG_ BatteryVoltage : 31|8@0+ (0.06,6) [6|18] "V" ACU,BCM,HFM,HPCU,HVAC_CU,LCU_ADB,LCU_MBL,eRDC_L,eRDC_R
  SG_ StarterStatus : 33|2@0+ (1,0) [0|0] "" BCM
  SG_ EEM_StaticPowerLimitationRequest : 36|3@0+ (1,0) [0|0] "" BCM,HVAC_CU
  SG_ UnderStarterRelayCondition : 38|2@0+ (1,0) [0|0] "" BCM
  SG_ FrontWiperStopPosition : 39|1@0+ (1,0) [0|0] "" BCM
  SG_ USM_ReferenceVoltage_raw : 40|9@0+ (0.025,6) [6|16] "V" BCM
  SG_ LowBeamActivationStatus : 42|2@0+ (1,0) [0|0] "" BCM
  SG_ USM_RefuseToSleep : 44|2@0+ (1,0) [0|0] "" BCM
  SG_ EEM_HighSpeedStopForbidden : 46|2@0+ (1,0) [0|0] "" BCM
  SG_ EEM_ConditionsForAD_byUSM : 63|2@0+ (1,0) [0|0] "" BCM

BO_ 1108 USM_A103: 8 USM
  SG_ HandDrivingActivationState : 0|1@0+ (1,0) [0|0] "" BCM
  SG_ ACCompValveCurrent : 7|7@0+ (0.01,0) [0|1] "A" BCM
  SG_ SOCBattery14V : 13|6@0+ (0.5,69) [69|100] "%" BCM
  SG_ LowBatteryVoltageDisplay : 15|2@0+ (1,0) [0|0] "" BCM
  SG_ AFS_ActivationState : 16|1@0+ (1,0) [0|0] "" BCM
  SG_ EngineFanSpeedStatus_PWM : 23|7@0+ (1,0) [0|100] "%" BCM,HVAC_CU
  SG_ EEM_SailingIdleForbidden : 25|2@0+ (1,0) [0|0] "" BCM
  SG_ LowBeamFailureDisplay_v3 : 27|2@0+ (1,0) [0|0] "" BCM
  SG_ IdleSpeedInhibitionRequest : 29|2@0+ (1,0) [0|0] "" BCM
  SG_ FrontWiperStatus : 31|2@0+ (1,0) [0|0] "" BCM,HVAC_CU
  SG_ BattWarnReq_Level_Lo_USM : 32|1@0+ (1,0) [0|0] "" BCM
  SG_ EEM_RegulationLoopActivationReq : 34|2@0+ (1,0) [0|0] "" BCM
  SG_ STCUT_STRLY_Condition : 36|2@0+ (1,0) [0|0] "" BCM
  SG_ STRLY_FailureAlert : 37|1@0+ (1,0) [0|0] "" BCM
  SG_ STCUT_RLY_Status : 39|2@0+ (1,0) [0|0] "" BCM
  SG_ SecStorage12V_ConnectionDiag : 41|2@0+ (1,0) [0|0] "" BCM
  SG_ GenMode_v2 : 44|3@0+ (1,0) [0|0] "" BCM
  SG_ Powernet_MinimumVoltageReq : 45|1@0+ (1,0) [0|0] "" BCM
  SG_ EEM_StopAutoForbidden : 47|2@0+ (1,0) [0|0] "" BCM
  SG_ ManualLevellingPositionDisplay : 48|1@0+ (1,0) [0|0] "" BCM
  SG_ EEM_RegulationLoopActivReq_v2 : 51|3@0+ (1,0) [0|0] "" BCM
  SG_ FrontWiperDiagStatus : 52|1@0+ (1,0) [0|0] "" BCM
  SG_ Storage12V_SwitchRequest : 53|1@0+ (1,0) [0|0] "" BCM
  SG_ Storages12V_TAforbidden : 55|2@0+ (1,0) [0|0] "" BCM
  SG_ AD_ExtSignalizationFailure : 63|1@0+ (1,0) [0|0] "" BCM

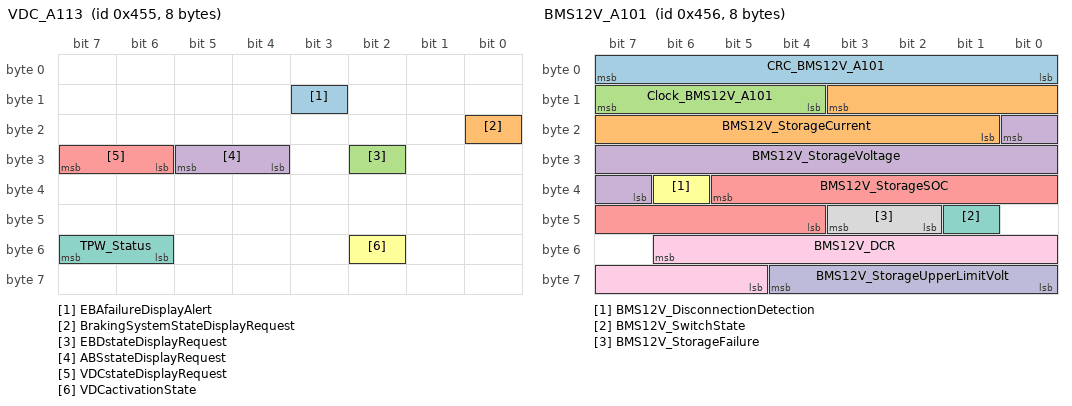
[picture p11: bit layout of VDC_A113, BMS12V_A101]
BO_ 1109 VDC_A113: 8 BCM
  SG_ EBAfailureDisplayAlert : 11|1@0+ (1,0) [0|0] "" ACU
  SG_ BrakingSystemStateDisplayRequest : 16|1@0+ (1,0) [0|0] "" ACU
  SG_ EBDstateDisplayRequest : 26|1@0+ (1,0) [0|0] "" ACU
  SG_ ABSstateDisplayRequest : 29|2@0+ (1,0) [0|0] "" ACU
  SG_ VDCstateDisplayRequest : 31|2@0+ (1,0) [0|0] "" ACU
  SG_ VDCactivationState : 50|1@0+ (1,0) [0|0] "" ACU
  SG_ TPW_Status : 55|2@0+ (1,0) [0|0] "" ACU

BO_ 1110 BMS12V_A101: 8 BCM
  SG_ CRC_BMS12V_A101 : 7|8@0+ (1,0) [0|255] "" USM
  SG_ BMS12V_StorageCurrent : 11|11@0+ (0.25,-150) [-150|300] "A" USM
  SG_ Clock_BMS12V_A101 : 15|4@0+ (1,0) [0|15] "" USM
  SG_ BMS12V_StorageVoltage : 16|10@0+ (0.01,9) [9|16] "V" USM
  SG_ BMS12V_StorageSOC : 37|10@0+ (0.1,0) [0|100] "%" USM
  SG_ BMS12V_DisconnectionDetection : 38|1@0+ (1,0) [0|0] "" USM
  SG_ BMS12V_SwitchState : 41|1@0+ (1,0) [0|0] "" USM
  SG_ BMS12V_StorageFailure : 43|2@0+ (1,0) [0|0] "" USM
  SG_ BMS12V_DCR : 54|10@0+ (0.04,0) [0|40] "mOhm" USM
  SG_ BMS12V_StorageUpperLimitVolt : 60|5@0+ (0.1,13.5) [13.5|16] "V" USM

BO_ 1116 CDM_A116: 8 BCM
  SG_ SecondaryStorage_SOCmin_forAD : 39|7@0+ (1,0) [0|100] "%" USM

BO_ 1119 ECM_A108: 4 BCM
  SG_ EngineCoolantTemp : 23|8@0+ (1,-40) [-40|214] "°C" HVAC_CU,USM

BO_ 1121 AirSUSP_N101: 8 BCM
  SG_ AirSUSP_SystemStatus : 55|3@0+ (1,0) [0|0] "" USM

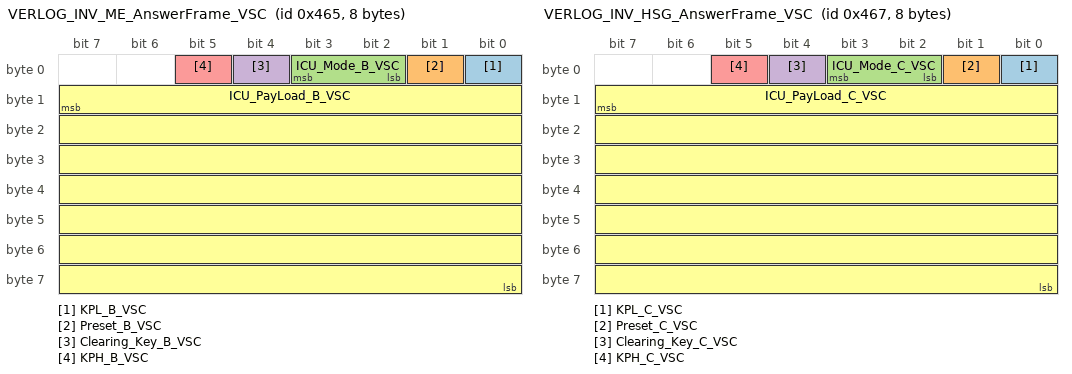
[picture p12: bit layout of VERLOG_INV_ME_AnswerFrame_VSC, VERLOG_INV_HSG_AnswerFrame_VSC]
BO_ 1125 VERLOG_INV_ME_AnswerFrame_VSC: 8 HFM
  SG_ KPL_B_VSC : 0|1@0+ (1,0) [0|0] "" BCM
  SG_ Preset_B_VSC : 1|1@0+ (1,0) [0|0] "" BCM
  SG_ ICU_Mode_B_VSC : 3|2@0+ (1,0) [0|0] "" BCM
  SG_ Clearing_Key_B_VSC : 4|1@0+ (1,0) [0|0] "" BCM
  SG_ KPH_B_VSC : 5|1@0+ (1,0) [0|0] "" BCM
  SG_ ICU_PayLoad_B_VSC : 15|56@0+ (1,0) [0|0] "" BCM

BO_ 1126 VERLOG_INV_ME_ChallengeFrame: 8 BCM
  SG_ TPU_Mode_B : 1|2@0+ (1,0) [0|0] "" HFM
  SG_ VerlogStatus_B : 2|1@0+ (1,0) [0|0] "" HFM
  SG_ SREM_B : 3|1@0+ (1,0) [0|0] "" HFM
  SG_ Version_B : 5|2@0+ (1,0) [0|0] "" HFM
  SG_ TPU_Payload_B : 15|56@0+ (1,0) [0|0] "" HFM

BO_ 1127 VERLOG_INV_HSG_AnswerFrame_VSC: 8 HFM
  SG_ KPL_C_VSC : 0|1@0+ (1,0) [0|0] "" BCM
  SG_ Preset_C_VSC : 1|1@0+ (1,0) [0|0] "" BCM
  SG_ ICU_Mode_C_VSC : 3|2@0+ (1,0) [0|0] "" BCM
  SG_ Clearing_Key_C_VSC : 4|1@0+ (1,0) [0|0] "" BCM
  SG_ KPH_C_VSC : 5|1@0+ (1,0) [0|0] "" BCM
  SG_ ICU_PayLoad_C_VSC : 15|56@0+ (1,0) [0|0] "" BCM

BO_ 1128 VERLOG_INV_HSG_ChallengeFrame: 8 BCM
  SG_ TPU_Mode_C : 1|2@0+ (1,0) [0|0] "" HFM
  SG_ VerlogStatus_C : 2|1@0+ (1,0) [0|0] "" HFM
  SG_ SREM_C : 3|1@0+ (1,0) [0|0] "" HFM
  SG_ Version_C : 5|2@0+ (1,0) [0|0] "" HFM
  SG_ TPU_Payload_C : 15|56@0+ (1,0) [0|0] "" HFM

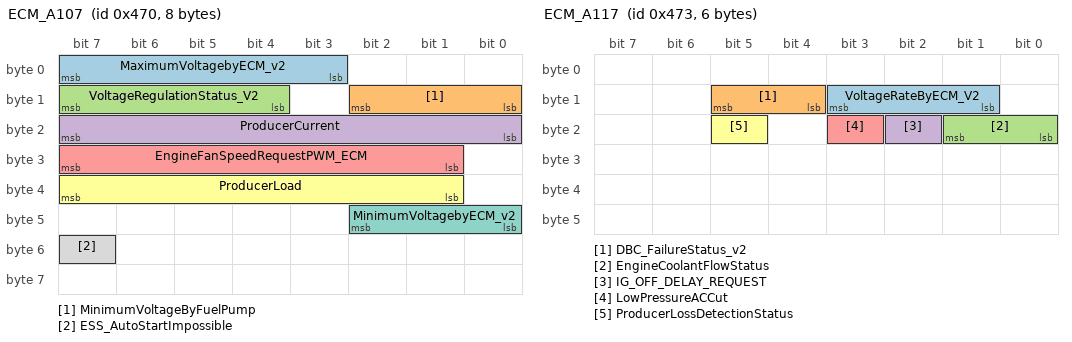
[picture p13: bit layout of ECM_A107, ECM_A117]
BO_ 1136 ECM_A107: 8 BCM
  SG_ MaximumVoltagebyECM_v2 : 7|5@0+ (0.1,13) [13|16] "V" USM
  SG_ MinimumVoltageByFuelPump : 10|3@0+ (0.5,12) [12|15] "V" USM
  SG_ VoltageRegulationStatus_V2 : 15|4@0+ (1,0) [0|0] "" USM
  SG_ ProducerCurrent : 23|8@0+ (1,0) [0|255] "A" HVAC_CU,USM
  SG_ EngineFanSpeedRequestPWM_ECM : 31|7@0+ (1,0) [0|100] "%" USM
  SG_ ProducerLoad : 39|7@0+ (1,0) [0|100] "%" HVAC_CU,USM
  SG_ MinimumVoltagebyECM_v2 : 42|3@0+ (0.5,12) [12|15] "V" USM
  SG_ ESS_AutoStartImpossible : 55|1@0+ (1,0) [0|0] "" USM

BO_ 1137 ECM_A114: 8 BCM
  SG_ Maintenance_Mode_Status : 25|2@0+ (1,0) [0|0] "" USM
  SG_ CruiseControlStatus : 31|3@0+ (1,0) [0|0] "" ACU
  SG_ EngineAirTemp : 47|7@0+ (1,-40) [-40|86] "°C" HVAC_CU

BO_ 1138 ECM_A116: 8 BCM
  SG_ VehicleSpeedDisplayedinkmh : 7|12@0+ (0.1,0) [0|409.4] "km/h" ACU
  SG_ SCR_UreaTankRemainingVol : 44|10@0+ (0.05,0) [0|51.1] "L" USM

BO_ 1139 ECM_A117: 6 BCM
  SG_ VoltageRateByECM_V2 : 11|3@0+ (1,0) [0|0] "" USM
  SG_ DBC_FailureStatus_v2 : 13|2@0+ (1,0) [0|0] "" USM
  SG_ EngineCoolantFlowStatus : 17|2@0+ (1,0) [0|0] "" HVAC_CU,USM
  SG_ IG_OFF_DELAY_REQUEST : 18|1@0+ (1,0) [0|0] "" USM
  SG_ LowPressureACCut : 19|1@0+ (1,0) [0|0] "" HVAC_CU
  SG_ ProducerLossDetectionStatus : 21|1@0+ (1,0) [0|0] "" USM

BO_ 1140 ADAS_A116: 8 BCM
  SG_ LKA_AlertStatus : 9|2@0+ (1,0) [0|0] "" ACU

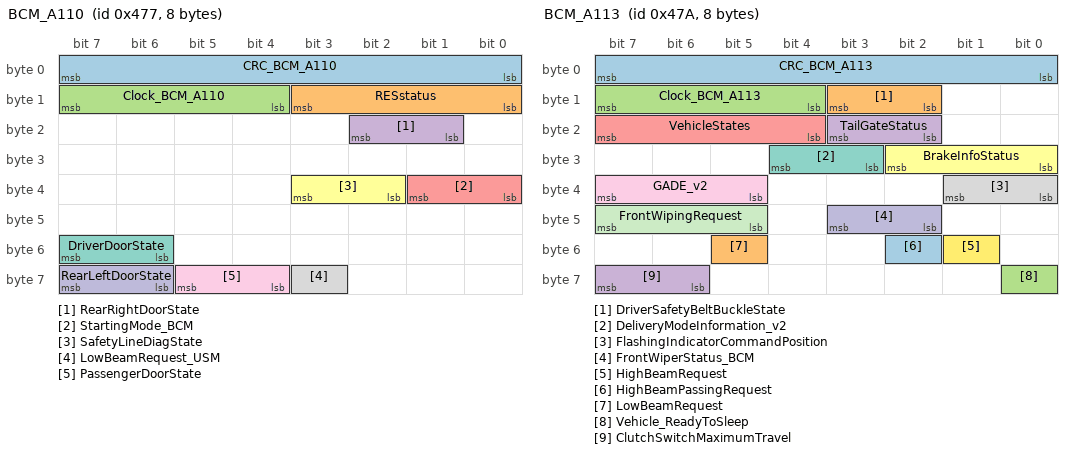
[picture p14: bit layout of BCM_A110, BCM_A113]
BO_ 1143 BCM_A110: 8 BCM
  SG_ CRC_BCM_A110 : 7|8@0+ (1,0) [0|255] "" HFM,USM
  SG_ RESstatus : 11|4@0+ (1,0) [0|0] "" HFM,HVAC_CU,USM
  SG_ Clock_BCM_A110 : 15|4@0+ (1,0) [0|15] "" HFM,USM
  SG_ RearRightDoorState : 18|2@0+ (1,0) [0|0] "" HFM,eRDC_R
  SG_ StartingMode_BCM : 33|2@0+ (1,0) [0|0] "" USM
  SG_ SafetyLineDiagState : 35|2@0+ (1,0) [0|0] "" HFM
  SG_ DriverDoorState : 55|2@0+ (1,0) [0|0] "" HFM,HVAC_CU,eRDC_L,eRDC_R
  SG_ LowBeamRequest_USM : 59|1@0+ (1,0) [0|0] "" USM
  SG_ PassengerDoorState : 61|2@0+ (1,0) [0|0] "" ACU,HFM,eRDC_L,eRDC_R
  SG_ RearLeftDoorState : 63|2@0+ (1,0) [0|0] "" HFM,eRDC_L

BO_ 1144 BCM_A111: 8 BCM
  SG_ ETAKickDetected : 8|1@0+ (1,0) [0|0] "" HFM
  SG_ TailGateButtonPushed : 10|2@0+ (1,0) [0|0] "" HFM
  SG_ WakeUpType : 13|3@0+ (1,0) [0|0] "" HFM,USM
  SG_ BCM_WakeUpSleepCommand : 15|2@0+ (1,0) [0|0] "" HFM,USM,eRDC_L,eRDC_R
  SG_ RearDefrostEngaged : 16|1@0+ (1,0) [0|0] "" HVAC_CU
  SG_ PositionLightsRequest : 17|1@0+ (1,0) [0|0] "" LCU_ADB,USM
  SG_ FrontFogLightsRequest : 18|1@0+ (1,0) [0|0] "" USM
  SG_ OriginOfVehOutsideLockedChangev2 : 27|4@0+ (1,0) [0|0] "" HFM
  SG_ PTCNumberThermalStatus : 31|4@0+ (1,0) [0|0] "" HVAC_CU
  SG_ DriverDoorLockedStatus : 32|1@0+ (1,0) [0|0] "" HFM
  SG_ DayTimeRunningLightRequest : 33|1@0+ (1,0) [0|0] "" LCU_ADB,USM
  SG_ HornRequest : 36|3@0+ (1,0) [0|0] "" USM
  SG_ HandFreeLockInhibition : 40|1@0+ (1,0) [0|0] "" HFM
  SG_ WarningLightsStatus : 41|1@0+ (1,0) [0|0] "" USM
  SG_ VehicleOutsideLockedState : 42|1@0+ (1,0) [0|0] "" HFM
  SG_ DriverSidePosition : 43|1@0+ (1,0) [0|0] "" eRDC_L,eRDC_R
  SG_ DriverOutsideBuzzerRequest : 47|4@0+ (1,0) [0|0] "" HFM
  SG_ FrontDefrostEngaged : 49|1@0+ (1,0) [0|0] "" HVAC_CU
  SG_ RearFogLightsRequest : 56|1@0+ (1,0) [0|0] "" USM
  SG_ BrakeLampStatus : 57|1@0+ (1,0) [0|0] "" USM
  SG_ HeadLampsWasherRequest : 60|1@0+ (1,0) [0|0] "" USM
  SG_ ESCLunlock_iKeyFobAuthent : 63|3@0+ (1,0) [0|0] "" HFM

BO_ 1145 BCM_A112: 8 BCM
  SG_ SingleDoorOpeningActivationState : 0|1@0+ (1,0) [0|0] "" HFM
  SG_ BCM_PresoakRequest : 2|2@0+ (1,0) [0|0] "" HVAC_CU
  SG_ LeftSolarLevelInfo : 7|5@0+ (50,0) [0|1500] "W" HVAC_CU
  SG_ PTCThermalRegulatorFreeze : 8|1@0+ (1,0) [0|0] "" HVAC_CU
  SG_ RightSolarLevelInfo : 15|5@0+ (50,0) [0|1500] "W" HVAC_CU
  SG_ InsideIkeyfobCountRequest : 16|1@0+ (1,0) [0|0] "" HFM
  SG_ ExternalWGS_Request : 19|2@0+ (1,0) [0|0] "" LCU_ADB,USM
  SG_ RearLightSignatureRequest : 29|2@0+ (1,0) [0|0] "" USM
  SG_ ADB_AuthorizationRequest : 32|1@0+ (1,0) [0|0] "" LCU_ADB
  SG_ TPMS_HornRequest : 40|1@0+ (1,0) [0|0] "" USM
  SG_ ProbableCustomerFeedBackNeed : 41|1@0+ (1,0) [0|0] "" HFM,HVAC_CU
  SG_ DayNightSynthesis : 49|2@0+ (1,0) [0|0] "" LCU_ADB
  SG_ BackDoorLockedStatus : 50|1@0+ (1,0) [0|0] "" HFM
  SG_ AutoLightingFunctionStatus : 51|1@0+ (1,0) [0|0] "" LCU_ADB,USM
  SG_ IGN_SaverWarningAfterIGNOFF : 56|1@0+ (1,0) [0|0] "" USM
  SG_ RearRightDoorLockedStatus : 57|1@0+ (1,0) [0|0] "" HFM
  SG_ RearLeftDoorLockedStatus : 58|1@0+ (1,0) [0|0] "" HFM
  SG_ PassengerDoorLockedStatus : 59|1@0+ (1,0) [0|0] "" HFM

BO_ 1146 BCM_A113: 8 BCM
  SG_ CRC_BCM_A113 : 7|8@0+ (1,0) [0|255] "" HFM,USM
  SG_ DriverSafetyBeltBuckleState : 11|2@0+ (1,0) [0|0] "" ACU,HVAC_CU,USM
  SG_ Clock_BCM_A113 : 15|4@0+ (1,0) [0|15] "" HFM,USM
  SG_ TailGateStatus : 19|2@0+ (1,0) [0|0] "" HFM,USM
  SG_ VehicleStates : 23|4@0+ (1,0) [0|0] "" HFM,HPCU,HVAC_CU,LCU_ADB,USM,eRDC_L,eRDC_R
  SG_ BrakeInfoStatus : 26|3@0+ (1,0) [0|0] "" ACU,eRDC_L,eRDC_R
  SG_ DeliveryModeInformation_v2 : 28|2@0+ (1,0) [0|0] "" ACU,HFM,HVAC_CU,LCU_ADB,USM
  SG_ FlashingIndicatorCommandPosition : 33|2@0+ (1,0) [0|0] "" USM
  SG_ GADE_v2 : 39|3@0+ (1,0) [0|0] "" ACU,HFM,HPCU,HVAC_CU,LCU_ADB,LCU_MBL,USM,eRDC_L,eRDC_R
  SG_ FrontWiperStatus_BCM : 43|2@0+ (1,0) [0|0] "" HVAC_CU
  SG_ FrontWipingRequest : 47|3@0+ (1,0) [0|0] "" USM
  SG_ HighBeamRequest : 49|1@0+ (1,0) [0|0] "" LCU_ADB,LCU_MBL,USM
  SG_ HighBeamPassingRequest : 50|1@0+ (1,0) [0|0] "" LCU_ADB,USM
  SG_ LowBeamRequest : 53|1@0+ (1,0) [0|0] "" LCU_ADB,LCU_MBL
  SG_ Vehicle_ReadyToSleep : 56|1@0+ (1,0) [0|0] "" USM
  SG_ ClutchSwitchMaximumTravel : 63|2@0+ (1,0) [0|0] "" USM

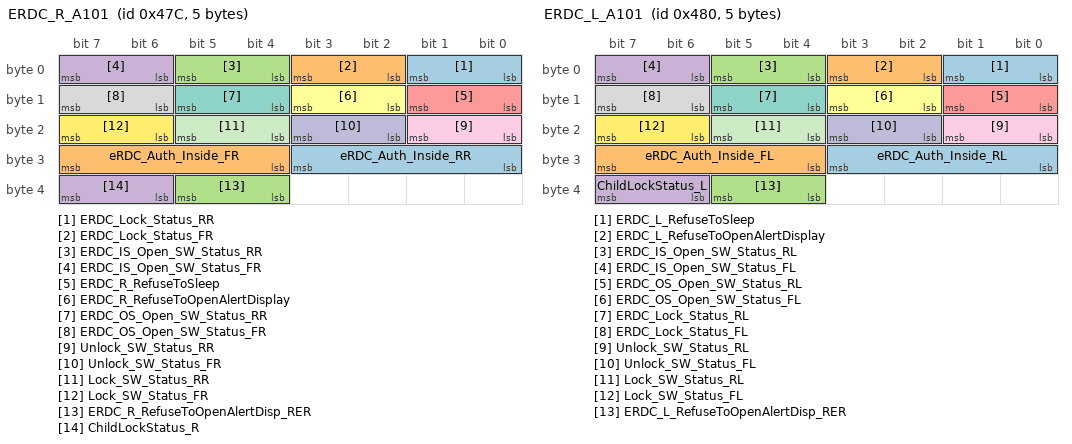
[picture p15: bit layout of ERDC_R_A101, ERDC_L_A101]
BO_ 1148 ERDC_R_A101: 5 eRDC_R
  SG_ ERDC_Lock_Status_RR : 1|2@0+ (1,0) [0|0] "" BCM
  SG_ ERDC_Lock_Status_FR : 3|2@0+ (1,0) [0|0] "" BCM
  SG_ ERDC_IS_Open_SW_Status_RR : 5|2@0+ (1,0) [0|0] "" BCM
  SG_ ERDC_IS_Open_SW_Status_FR : 7|2@0+ (1,0) [0|0] "" BCM
  SG_ ERDC_R_RefuseToSleep : 9|2@0+ (1,0) [0|0] "" BCM
  SG_ ERDC_R_RefuseToOpenAlertDisplay : 11|2@0+ (1,0) [0|0] "" BCM
  SG_ ERDC_OS_Open_SW_Status_RR : 13|2@0+ (1,0) [0|0] "" BCM
  SG_ ERDC_OS_Open_SW_Status_FR : 15|2@0+ (1,0) [0|0] "" BCM
  SG_ Unlock_SW_Status_RR : 17|2@0+ (1,0) [0|0] "" BCM
  SG_ Unlock_SW_Status_FR : 19|2@0+ (1,0) [0|0] "" BCM
  SG_ Lock_SW_Status_RR : 21|2@0+ (1,0) [0|0] "" BCM
  SG_ Lock_SW_Status_FR : 23|2@0+ (1,0) [0|0] "" BCM
  SG_ eRDC_Auth_Inside_RR : 27|4@0+ (1,0) [0|0] "" BCM
  SG_ eRDC_Auth_Inside_FR : 31|4@0+ (1,0) [0|0] "" BCM
  SG_ ERDC_R_RefuseToOpenAlertDisp_RER : 37|2@0+ (1,0) [0|0] "" BCM
  SG_ ChildLockStatus_R : 39|2@0+ (1,0) [0|0] "" BCM

BO_ 1152 ERDC_L_A101: 5 eRDC_L
  SG_ ERDC_L_RefuseToSleep : 1|2@0+ (1,0) [0|0] "" BCM
  SG_ ERDC_L_RefuseToOpenAlertDisplay : 3|2@0+ (1,0) [0|0] "" BCM
  SG_ ERDC_IS_Open_SW_Status_RL : 5|2@0+ (1,0) [0|0] "" BCM
  SG_ ERDC_IS_Open_SW_Status_FL : 7|2@0+ (1,0) [0|0] "" BCM
  SG_ ERDC_OS_Open_SW_Status_RL : 9|2@0+ (1,0) [0|0] "" BCM
  SG_ ERDC_OS_Open_SW_Status_FL : 11|2@0+ (1,0) [0|0] "" BCM
  SG_ ERDC_Lock_Status_RL : 13|2@0+ (1,0) [0|0] "" BCM
  SG_ ERDC_Lock_Status_FL : 15|2@0+ (1,0) [0|0] "" BCM
  SG_ Unlock_SW_Status_RL : 17|2@0+ (1,0) [0|0] "" BCM
  SG_ Unlock_SW_Status_FL : 19|2@0+ (1,0) [0|0] "" BCM
  SG_ Lock_SW_Status_RL : 21|2@0+ (1,0) [0|0] "" BCM
  SG_ Lock_SW_Status_FL : 23|2@0+ (1,0) [0|0] "" BCM
  SG_ eRDC_Auth_Inside_RL : 27|4@0+ (1,0) [0|0] "" BCM
  SG_ eRDC_Auth_Inside_FL : 31|4@0+ (1,0) [0|0] "" BCM
  SG_ ERDC_L_RefuseToOpenAlertDisp_RER : 37|2@0+ (1,0) [0|0] "" BCM
  SG_ ChildLockStatus_L : 39|2@0+ (1,0) [0|0] "" BCM

BO_ 1161 MBL_A1: 1 LCU_MBL
  SG_ MBL_FailureDetection : 6|1@0+ (1,0) [0|0] "" USM
  SG_ MBLfailureDisplay : 7|1@0+ (1,0) [0|0] "" BCM

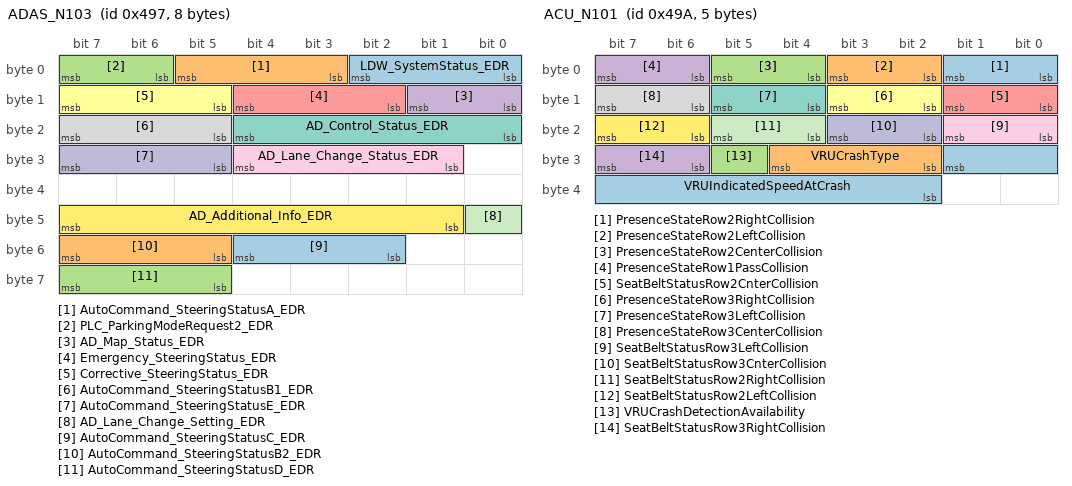
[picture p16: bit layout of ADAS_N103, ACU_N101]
BO_ 1175 ADAS_N103: 8 BCM
  SG_ LDW_SystemStatus_EDR : 2|3@0+ (1,0) [0|0] "" ACU
  SG_ AutoCommand_SteeringStatusA_EDR : 5|3@0+ (1,0) [0|0] "" ACU
  SG_ PLC_ParkingModeRequest2_EDR : 7|2@0+ (1,0) [0|0] "" ACU
  SG_ AD_Map_Status_EDR : 9|2@0+ (1,0) [0|0] "" ACU
  SG_ Emergency_SteeringStatus_EDR : 12|3@0+ (1,0) [0|0] "" ACU
  SG_ Corrective_SteeringStatus_EDR : 15|3@0+ (1,0) [0|0] "" ACU
  SG_ AD_Control_Status_EDR : 20|5@0+ (1,0) [0|0] "" ACU
  SG_ AutoCommand_SteeringStatusB1_EDR : 23|3@0+ (1,0) [0|0] "" ACU
  SG_ AD_Lane_Change_Status_EDR : 28|4@0+ (1,0) [0|0] "" ACU
  SG_ AutoCommand_SteeringStatusE_EDR : 31|3@0+ (1,0) [0|0] "" ACU
  SG_ AD_Lane_Change_Setting_EDR : 40|1@0+ (1,0) [0|0] "" ACU
  SG_ AD_Additional_Info_EDR : 47|7@0+ (1,0) [0|0] "" ACU
  SG_ AutoCommand_SteeringStatusC_EDR : 52|3@0+ (1,0) [0|0] "" ACU
  SG_ AutoCommand_SteeringStatusB2_EDR : 55|3@0+ (1,0) [0|0] "" ACU
  SG_ AutoCommand_SteeringStatusD_EDR : 63|3@0+ (1,0) [0|0] "" ACU

BO_ 1176 ADAS_N104: 8 BCM
  SG_ AEB_SystemStatus_EDR : 7|3@0+ (1,0) [0|0] "" ACU

BO_ 1178 ACU_N101: 5 ACU
  SG_ PresenceStateRow2RightCollision : 1|2@0+ (1,0) [0|0] "" BCM
  SG_ PresenceStateRow2LeftCollision : 3|2@0+ (1,0) [0|0] "" BCM
  SG_ PresenceStateRow2CenterCollision : 5|2@0+ (1,0) [0|0] "" BCM
  SG_ PresenceStateRow1PassCollision : 7|2@0+ (1,0) [0|0] "" BCM
  SG_ SeatBeltStatusRow2CnterCollision : 9|2@0+ (1,0) [0|0] "" BCM
  SG_ PresenceStateRow3RightCollision : 11|2@0+ (1,0) [0|0] "" BCM
  SG_ PresenceStateRow3LeftCollision : 13|2@0+ (1,0) [0|0] "" BCM
  SG_ PresenceStateRow3CenterCollision : 15|2@0+ (1,0) [0|0] "" BCM
  SG_ SeatBeltStatusRow3LeftCollision : 17|2@0+ (1,0) [0|0] "" BCM
  SG_ SeatBeltStatusRow3CnterCollision : 19|2@0+ (1,0) [0|0] "" BCM
  SG_ SeatBeltStatusRow2RightCollision : 21|2@0+ (1,0) [0|0] "" BCM
  SG_ SeatBeltStatusRow2LeftCollision : 23|2@0+ (1,0) [0|0] "" BCM
  SG_ VRUIndicatedSpeedAtCrash : 25|8@0+ (1,0) [0|200] "km/h" BCM
  SG_ VRUCrashType : 28|3@0+ (1,0) [0|0] "" BCM
  SG_ VRUCrashDetectionAvailability : 29|1@0+ (1,0) [0|0] "" BCM
  SG_ SeatBeltStatusRow3RightCollision : 31|2@0+ (1,0) [0|0] "" BCM

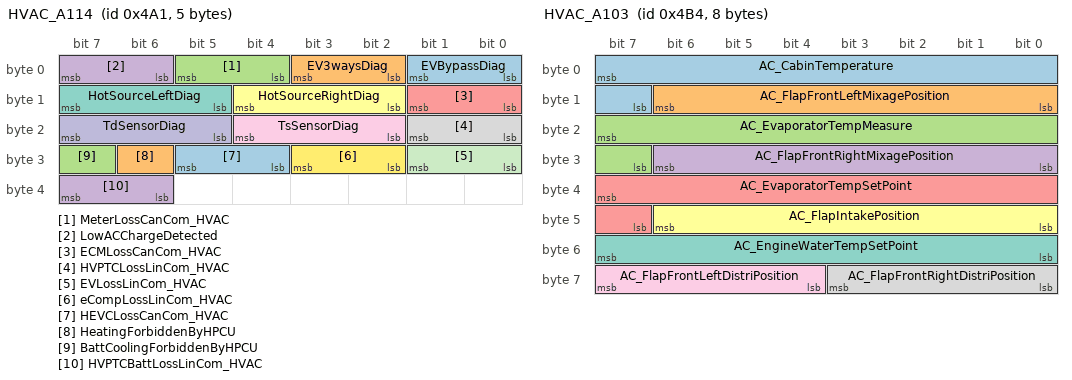
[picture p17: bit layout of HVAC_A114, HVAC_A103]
BO_ 1185 HVAC_A114: 5 HVAC_CU
  SG_ EVBypassDiag : 1|2@0+ (1,0) [0|0] "" BCM
  SG_ EV3waysDiag : 3|2@0+ (1,0) [0|0] "" BCM
  SG_ MeterLossCanCom_HVAC : 5|2@0+ (1,0) [0|0] "" BCM
  SG_ LowACChargeDetected : 7|2@0+ (1,0) [0|0] "" BCM
  SG_ ECMLossCanCom_HVAC : 9|2@0+ (1,0) [0|0] "" BCM
  SG_ HotSourceRightDiag : 12|3@0+ (1,0) [0|0] "" BCM
  SG_ HotSourceLeftDiag : 15|3@0+ (1,0) [0|0] "" BCM
  SG_ HVPTCLossLinCom_HVAC : 17|2@0+ (1,0) [0|0] "" BCM
  SG_ TsSensorDiag : 20|3@0+ (1,0) [0|0] "" BCM
  SG_ TdSensorDiag : 23|3@0+ (1,0) [0|0] "" BCM
  SG_ EVLossLinCom_HVAC : 25|2@0+ (1,0) [0|0] "" BCM
  SG_ eCompLossLinCom_HVAC : 27|2@0+ (1,0) [0|0] "" BCM
  SG_ HEVCLossCanCom_HVAC : 29|2@0+ (1,0) [0|0] "" BCM
  SG_ HeatingForbiddenByHPCU : 30|1@0+ (1,0) [0|0] "" BCM
  SG_ BattCoolingForbiddenByHPCU : 31|1@0+ (1,0) [0|0] "" BCM
  SG_ HVPTCBattLossLinCom_HVAC : 39|2@0+ (1,0) [0|0] "" BCM

BO_ 1189 BCM_N101: 8 BCM
  SG_ UserIdentification_IKeyLink_v2 : 39|4@0+ (1,0) [0|0] "" HVAC_CU
  SG_ Left_iKeyFobAuthent_Req_V2 : 62|1@0+ (1,0) [0|0] "" HFM
  SG_ Right_iKeyFobAuthent_Req_V2 : 63|1@0+ (1,0) [0|0] "" HFM

BO_ 1191 VADA_R1: 1 BCM
  SG_ VADA_SystemMode : 7|2@0+ (1,0) [0|0] "" USM

BO_ 1202 AVM_A102: 6 BCM
  SG_ APA_CancelReason : 28|2@0+ (1,0) [0|0] "" ACU
  SG_ RPK_LedStatusRequest : 45|3@0+ (1,0) [0|0] "" HFM

BO_ 1204 HVAC_A103: 8 HVAC_CU
  SG_ AC_CabinTemperature : 7|9@0+ (0.25,-50) [-50|70] "°C" BCM,HPCU
  SG_ AC_FlapFrontLeftMixagePosition : 14|7@0+ (1,0) [0|100] "%" BCM,HPCU
  SG_ AC_EvaporatorTempMeasure : 23|9@0+ (0.25,-50) [-50|70] "°C" BCM,HPCU
  SG_ AC_FlapFrontRightMixagePosition : 30|7@0+ (1,0) [0|100] "%" BCM,HPCU
  SG_ AC_EvaporatorTempSetPoint : 39|9@0+ (0.25,-50) [-50|70] "°C" BCM,HPCU
  SG_ AC_FlapIntakePosition : 46|7@0+ (1,0) [0|100] "%" BCM,HPCU
  SG_ AC_EngineWaterTempSetPoint : 55|8@0+ (1,-40) [-40|214] "°C" BCM
  SG_ AC_FlapFrontRightDistriPosition : 59|4@0+ (1,0) [0|0] "" BCM,HPCU
  SG_ AC_FlapFrontLeftDistriPosition : 63|4@0+ (1,0) [0|0] "" BCM,HPCU

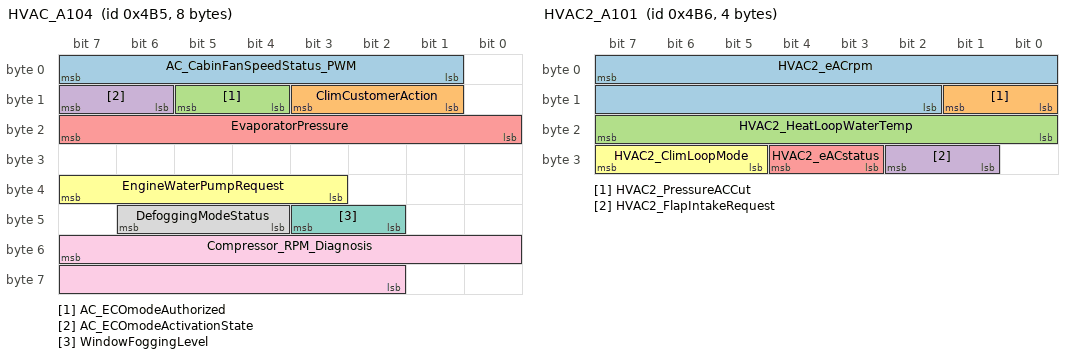
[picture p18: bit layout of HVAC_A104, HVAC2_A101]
BO_ 1205 HVAC_A104: 8 HVAC_CU
  SG_ AC_CabinFanSpeedStatus_PWM : 7|7@0+ (1,0) [0|100] "%" BCM,HPCU
  SG_ ClimCustomerAction : 11|3@0+ (1,0) [0|6] "" BCM
  SG_ AC_ECOmodeAuthorized : 13|2@0+ (1,0) [0|0] "" BCM
  SG_ AC_ECOmodeActivationState : 15|2@0+ (1,0) [0|0] "" BCM
  SG_ EvaporatorPressure : 23|8@0+ (0.05,0) [0|10] "bar" BCM
  SG_ EngineWaterPumpRequest : 39|5@0+ (1.25,0) [0|25] "l/min" BCM
  SG_ WindowFoggingLevel : 43|2@0+ (1,0) [0|0] "" BCM
  SG_ DefoggingModeStatus : 46|3@0+ (1,0) [0|0] "" BCM
  SG_ Compressor_RPM_Diagnosis : 55|14@0+ (1,0) [0|12000] "rpm" BCM

BO_ 1206 HVAC2_A101: 4 BCM
  SG_ HVAC2_eACrpm : 7|14@0+ (1,0) [0|9000] "rpm" HVAC_CU
  SG_ HVAC2_PressureACCut : 9|2@0+ (1,0) [0|0] "" HVAC_CU
  SG_ HVAC2_HeatLoopWaterTemp : 23|8@0+ (1,-40) [-40|214] "°C" HVAC_CU
  SG_ HVAC2_FlapIntakeRequest : 26|2@0+ (1,0) [0|0] "" HVAC_CU
  SG_ HVAC2_eACstatus : 28|2@0+ (1,0) [0|0] "" HVAC_CU
  SG_ HVAC2_ClimLoopMode : 31|3@0+ (1,0) [0|0] "" HVAC_CU

BO_ 1225 PBD_A101: 4 BCM
  SG_ VehicleInsideKeyIdentRequest : 13|4@0+ (1,0) [0|0] "" HFM
  SG_ RearZonePollingRequest : 15|2@0+ (1,0) [0|0] "" HFM
  SG_ OutsideZoneKeyIdentRequest : 26|1@0+ (1,0) [0|0] "" HFM
  SG_ OutsideZonePollingRequest : 28|2@0+ (1,0) [0|0] "" HFM

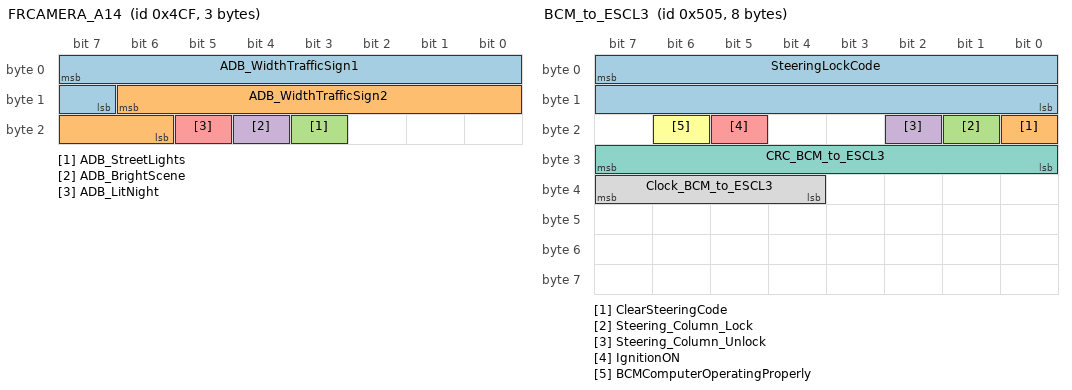
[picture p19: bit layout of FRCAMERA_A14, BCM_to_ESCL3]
BO_ 1231 FRCAMERA_A14: 3 BCM
  SG_ ADB_WidthTrafficSign1 : 7|9@0+ (0.1,0) [0|50] "°" LCU_ADB
  SG_ ADB_WidthTrafficSign2 : 14|9@0+ (0.1,0) [0|50] "°" LCU_ADB
  SG_ ADB_StreetLights : 19|1@0+ (1,0) [0|0] "" LCU_ADB
  SG_ ADB_BrightScene : 20|1@0+ (1,0) [0|0] "" LCU_ADB
  SG_ ADB_LitNight : 21|1@0+ (1,0) [0|0] "" LCU_ADB

BO_ 1232 HEVC_N103: 7 BCM
  SG_ HVbatWaterCircuitStatus : 7|4@0+ (1,0) [0|0] "" HPCU,HVAC_CU

BO_ 1233 BCM_A103: 8 BCM
  SG_ MotorShow_Request : 6|1@0+ (1,0) [0|0] "" LCU_ADB,USM
  SG_ RearLightingSignatureRequest : 11|4@0+ (1,0) [0|0] "" USM
  SG_ FrontLightingSignatureRequest : 15|4@0+ (1,0) [0|0] "" USM
  SG_ Open_Authent_result_RR : 18|2@0+ (1,0) [0|0] "" eRDC_R
  SG_ Showroom_Request : 19|1@0+ (1,0) [0|0] "" LCU_ADB,USM
  SG_ RearWasherPumpActivationReq : 24|1@0+ (1,0) [0|0] "" USM
  SG_ FrontWasherPumpActivationReq : 25|1@0+ (1,0) [0|0] "" HVAC_CU,USM
  SG_ WindshieldTemperature : 31|6@0+ (1,-30) [-30|33] "°C" HVAC_CU
  SG_ LIDARWasherPumpRequest : 32|1@0+ (1,0) [0|0] "" USM
  SG_ CabinRelativeHumidity : 39|7@0+ (1,0) [0|100] "%" HVAC_CU
  SG_ HazardLampStatus : 45|1@0+ (1,0) [0|0] "" ACU,USM
  SG_ AllWeather_Request : 47|2@0+ (1,0) [0|0] "" USM
  SG_ FirstStartDeviceSelection : 53|2@0+ (1,0) [0|0] "" USM
  SG_ FlashingIndicatorActivationState : 55|2@0+ (1,0) [0|0] "" ACU,USM
  SG_ Open_Authent_result_RL : 57|2@0+ (1,0) [0|0] "" eRDC_L
  SG_ Open_Authent_result_FR : 59|2@0+ (1,0) [0|0] "" eRDC_R
  SG_ Open_Authent_result_FL : 61|2@0+ (1,0) [0|0] "" eRDC_L

BO_ 1241 HFM_A9: 1 HFM
  SG_ CustomerIdentType : 7|1@0+ (1,0) [0|0] "" BCM

BO_ 1246 HPCU_A102: 8 HPCU
  SG_ HPCU_CVN : 7|64@0+ (1,0) [0|1.84467440737095E19] "-" BCM

BO_ 1250 HVAC_A113: 8 HVAC_CU
  SG_ e_EXP_Valve_Stuck_Diagnosis : 1|2@0+ (1,0) [0|0] "" BCM
  SG_ e_EXP_Valve_Diagnosis_Status : 3|2@0+ (1,0) [0|0] "" BCM
  SG_ ON_OFF_Valve_Stuck_Diagnosis : 5|2@0+ (1,0) [0|0] "" BCM
  SG_ Compressor_Diagnosis_Status : 7|2@0+ (1,0) [0|0] "" BCM
  SG_ Compr_Interface_Error_Status : 9|2@0+ (1,0) [0|0] "" BCM
  SG_ Compr_Sensor_Error_status : 11|2@0+ (1,0) [0|0] "" BCM
  SG_ Compr_Internal_Error_Status : 13|2@0+ (1,0) [0|0] "" BCM
  SG_ ClimBox_Diagnosis_Status : 15|2@0+ (1,0) [0|0] "" BCM
  SG_ WaterTempHVCHDiag : 16|3@0+ (1,0) [0|0] "" BCM
  SG_ Teva_Air_Sens_Diag : 19|3@0+ (1,0) [0|0] "" BCM
  SG_ Teva_Air_Sens_Diag_Status : 21|2@0+ (1,0) [0|0] "" BCM
  SG_ Compr_Inverter_Over_Heat_status : 23|2@0+ (1,0) [0|0] "" BCM
  SG_ Compr_Sensor_Error_diagnosis : 25|2@0+ (1,0) [0|0] "" BCM
  SG_ Compr_Internal_Error_diagnosis : 28|3@0+ (1,0) [0|0] "" BCM
  SG_ Loss_of_BMS_Information : 29|1@0+ (1,0) [0|0] "" BCM
  SG_ Climbox_CAN_failure_with_HEVC : 32|1@0+ (1,0) [0|0] "" BCM
  SG_ Compr_Inverter_over_Heating_diag : 33|1@0+ (1,0) [0|0] "" BCM
  SG_ Compr_Inverter_High_Temp_diag : 34|1@0+ (1,0) [0|0] "" BCM
  SG_ Compr_Over_Load_Warning_diag : 36|2@0+ (1,0) [0|0] "" BCM
  SG_ Compr_Motor_Control_Fault_diag : 38|2@0+ (1,0) [0|0] "" BCM
  SG_ Compr_Interface_Error_diagnosis : 39|1@0+ (1,0) [0|0] "" BCM
  SG_ Compr_LIN_Communication_Status : 41|2@0+ (1,0) [0|0] "" BCM
  SG_ Compr_Inverter_High_Temp_Status : 43|2@0+ (1,0) [0|0] "" BCM
  SG_ Compr_Over_Load_Warning_Status : 45|2@0+ (1,0) [0|0] "" BCM
  SG_ Compr_Motor_Control_Fault_status : 47|2@0+ (1,0) [0|0] "" BCM
  SG_ Incar_Sens_Diag_Status : 50|2@0+ (1,0) [0|0] "" BCM
  SG_ Incar_Sens_Diag : 53|3@0+ (1,0) [0|0] "" BCM
  SG_ Compr_LIN_Error_diagnosis : 54|1@0+ (1,0) [0|0] "" BCM
  SG_ Climbox_LIN_Failure_with_Compr : 55|1@0+ (1,0) [0|0] "" BCM
  SG_ IncarTemperatureValue : 63|8@0+ (1,-60) [-60|105] "degC" BCM

BO_ 1255 IVI_N110: 8 BCM
  SG_ BatteryCool_eACLimitStatus_IVI : 60|2@0+ (1,0) [0|0] "" HVAC_CU

BO_ 1257 USM_R101: 1 USM
  SG_ ACCompValveDiag : 5|2@0+ (1,0) [0|0] "" BCM
  SG_ ACCompClutchDiag : 7|2@0+ (1,0) [0|0] "" BCM

BO_ 1258 HPCU_A101: 8 HPCU
  SG_ Bat_Outlet_Temp_Sens_Diag : 2|3@0+ (1,0) [0|0] "" BCM
  SG_ Bat_Inlet_Temp_Sens_Diag : 5|3@0+ (1,0) [0|0] "" BCM
  SG_ HPCU_Diagnosis_Status : 7|2@0+ (1,0) [0|0] "" BCM
  SG_ PRUN_HPCU : 15|8@0+ (1,0) [0|255] "" BCM
  SG_ Bat_Outlet_Temp_Sens_Diag_Status : 17|2@0+ (1,0) [0|0] "" BCM
  SG_ Bat_Inlet_Temp_Sens_Diag_Status : 19|2@0+ (1,0) [0|0] "" BCM
  SG_ OBD_Consistency_Check_HPCU : 23|4@0+ (1,0) [0|15] "" BCM
  SG_ EXVBattStatus : 24|1@0+ (1,0) [0|0] "" BCM
  SG_ BattCoolingValveState : 25|1@0+ (1,0) [0|0] "" BCM
  SG_ ChillerOutletTemperatureState : 28|3@0+ (1,0) [0|0] "" BCM
  SG_ HPCU_CANfailure_With_HVAC : 29|1@0+ (1,0) [0|0] "" BCM
  SG_ ON_OFF_Valve_Stuck_Diag_Status : 31|2@0+ (1,0) [0|0] "" BCM
  SG_ ChillerOutletTemperatureValue : 39|8@0+ (1,-40) [-40|105] "°C" BCM
  SG_ EVAPO_Ref_Temp_Sens_Diag : 42|3@0+ (1,0) [0|0] "" BCM
  SG_ EVAPO_Ref_Temp_Sens_Diag_Status : 44|2@0+ (1,0) [0|0] "" BCM
  SG_ ChillerInletTemperatureState : 47|3@0+ (1,0) [0|0] "" BCM
  SG_ COND_eEXP_Valve_Stuck_Diagnosis : 49|2@0+ (1,0) [0|0] "" BCM
  SG_ COND_eEXP_Valve_Diag_Status : 51|2@0+ (1,0) [0|0] "" BCM
  SG_ EVAPO_eEXP_Valve_Stuck_Diagnosis : 53|2@0+ (1,0) [0|0] "" BCM
  SG_ EVAPO_eEXP_Valve_Diag_Status : 55|2@0+ (1,0) [0|0] "" BCM
  SG_ EvapoRefTemperatureValue : 63|8@0+ (1,-40) [-40|105] "degC" BCM

BO_ 1265 HVAC_R101: 1 HVAC_CU
  SG_ HeatLoopWaterValveRequest_EVA : 0|1@0+ (1,0) [0|0] "" BCM
  SG_ HeatLoopWaterPumpRequest_EVA : 7|7@0+ (1,0) [0|100] "%" BCM

BO_ 1274 VDC_A137: 4 BCM
  SG_ LongitudinalAccelCorrected_EDR : 4|12@0+ (0.001,-2) [-2|2] "G" ACU
  SG_ TransversalAccelCorrected_EDR : 23|12@0+ (0.001,-2) [-2|2] "G" ACU

BO_ 1276 ADAS_A6: 8 BCM
  SG_ ACC_Status_Slow : 45|4@0+ (1,0) [0|0] "" ACU

BO_ 1279 IVI_A132: 8 BCM
  SG_ ThirdRowLeftSeatAutoRequest : 44|2@0+ (1,0) [0|0] "" HVAC_CU
  SG_ ThirdRowRightSeatAutoRequest : 46|2@0+ (1,0) [0|0] "" HVAC_CU
  SG_ ClimIRSensorOn_Push : 47|1@0+ (1,0) [0|1] "-" HVAC_CU

BO_ 1285 BCM_to_ESCL3: 8 HFM
  SG_ SteeringLockCode : 7|16@0+ (1,0) [0|0] "" ESCL
  SG_ ClearSteeringCode : 16|1@0+ (1,0) [0|0] "" ESCL
  SG_ Steering_Column_Lock : 17|1@0+ (1,0) [0|0] "" ESCL
  SG_ Steering_Column_Unlock : 18|1@0+ (1,0) [0|0] "" ESCL
  SG_ IgnitionON : 21|1@0+ (1,0) [0|0] "" ESCL
  SG_ BCMComputerOperatingProperly : 22|1@0+ (1,0) [0|0] "" ESCL
  SG_ CRC_BCM_to_ESCL3 : 31|8@0+ (1,0) [0|255] "" ESCL
  SG_ Clock_BCM_to_ESCL3 : 39|4@0+ (1,0) [0|15] "" ESCL

BO_ 1296 TCU_A103: 8 BCM
  SG_ TCU_DVR_Photo_Request : 1|1@0+ (1,0) [0|0] "" USM
  SG_ ImmediatePreSoakTemp : 38|7@0+ (0.5,16) [16|32] "°C" HVAC_CU

BO_ 1301 RemoteFunctionService_HFM_to_BLM_Frame: 8 HFM
  SG_ RemoteFunctionService_HFM_to_BLM : 7|64@0+ (1,0) [0|0] "" BCM

BO_ 1302 RemoteFunctionService_BLM_to_HFM_Frame: 8 BCM
  SG_ RemoteFunctionService_BLM_to_HFM : 7|64@0+ (1,0) [0|0] "" HFM

BO_ 1303 FRCAMERA_A2: 8 BCM
  SG_ CamFrontDefrostRequest : 40|1@0+ (1,0) [0|0] "" HVAC_CU

VAL_ 32 AirbagCrashOrder_v3 0 "Crash not detected" 15 "Medium crash" 31 "Violent crash" 47 "Rear crash";
VAL_ 32 DirectionRear2ndCollision 0 "No detect" 1 "Detect";
VAL_ 32 DirectionRollover2ndCollision 0 "No detect" 1 "Detect";
VAL_ 32 DataSetCollisionValidity 0 "First collision" 1 "Second collision";
VAL_ 32 SeatBeltStatusDriver1stCollision 0 "SB Not monitored" 1 "SB unfastened" 2 "SB fastened" 3 "Unavailable";
VAL_ 32 SeatBeltStatusPass1stCollision 0 "SB Not monitored" 1 "SB unfastened" 2 "SB fastened" 3 "Unavailable";
VAL_ 32 DirectionLeft1stCollision 0 "No detect" 1 "Detect";
VAL_ 32 PreRolloverDetection 0 "PreRollover not detected" 1 "PreRollover detected";
VAL_ 32 SeatBeltStatusDriver2ndCollision 0 "SB Not monitored" 1 "SB unfastened" 2 "SB fastened" 3 "Unavailable";
VAL_ 32 SeatBeltStatusPass2ndcollision 0 "SB Not monitored" 1 "SB unfastened" 2 "SB fastened" 3 "Unavailable";
VAL_ 32 DirectionLeft2ndCollision 0 "No detect" 1 "Detect";
VAL_ 32 DirectionRight2ndCollision 0 "No detect" 1 "Detect";
VAL_ 32 DirectionFront2ndCollision 0 "No detect" 1 "Detect";
VAL_ 32 DirectionRollover1stCollision 0 "No detect" 1 "Detect";
VAL_ 32 RolloverDetection 0 "Rollover not detected" 1 "Rollover detected";
VAL_ 32 CrashLevelType 0 "No crash or confirmed light crash" 1 "Reserved for safety" 2 "Reserved for safety" 3 "Reserved for safety" 4 "Reserved for safety" 5 "Reserved for safety" 6 "Reserved for safety" 7 "Possible heavy crash or confirmed heavy crash";
VAL_ 32 DirectionRight1stCollision 0 "No detect" 1 "Detect";
VAL_ 32 DirectionFront1stCollision 0 "No detect" 1 "Detect";
VAL_ 32 DirectionRear1stCollision 0 "No detect" 1 "Detect";
VAL_ 115 ElectricalPowerCutFreeze 0 "no request" 1 "PTC freeze request" 2 "PTC cut request" 3 "Reserved";
VAL_ 115 ACCompAuthorized 0 "ac compressor not authorized" 1 "ac compressor authorized";
VAL_ 115 CrankingAuthorization_PWT 0 "cranking not allowed" 1 "cranking allowed" 2 "cranking stopped required" 3 "no request";
VAL_ 116 StopAutoPhase 0 "NotInAutoPhase" 1 "StartAuto" 2 "StopAuto" 3 "Not Used" 4 "StopAutoOngoing" 5 "StartByInjectionOnly" 6 "ReflexStart" 7 "Unavailable";
VAL_ 117 PowerTrainStatus 0 "Powertrain Stopped" 1 "Reserved" 2 "Powertrain Running" 3 "Powertrain Starting";
VAL_ 117 EngineStopRequestOrigin 0 "No engine stop request (initial stop or independant engine running)" 1 "Engine stopped by other causes" 2 "Engine stopped by normal system request" 3 "Engine stopped by normal driver request" 4 "Engine stopped by emergency request" 5 "Not used" 6 "Not used" 7 "Not used";
VAL_ 168 SwaSensorInternalStatus 0 "not calibrated, not indexed" 1 "not calibrated, indexed" 2 "fault" 3 "reserved" 4 "calibrated, not initialised" 5 "calibrated, initialised" 6 "reserved" 7 "reserved";
VAL_ 255 AEB_BrakingPerformanceStatus 0 "Braking fully operational" 1 "Impossible to execute request" 2 "Not used" 3 "Unavailable";
VAL_ 255 BrakePedalPressedByDriver 0 "Not used" 1 "Brake Pedal Not Pressed" 2 "Brake Pedal Pressed" 3 "Unavailable";
VAL_ 303 GearLeverPosition_v2 0 "Parking - P" 1 "Reverse - R" 2 "Neutral - N" 3 "Drive - D" 4 "Manual mode - M" 5 "L" 6 "Ds" 7 "Confirmed lever position (no switch signal)" 8 "B (Brake)" 9 "Not used" 10 "Not used" 11 "Not used" 12 "Not used" 13 "Not used" 14 "Not used" 15 "Not available (init or lever switched failure)";
VAL_ 303 AT_StartingAuthorization 0 "Unavailable Value" 1 "Cranking not allowed" 2 "Reserved for Safety" 3 "Reserved for Safety" 4 "Cranking allowed" 5 "Reserved for Safety" 6 "Reserved for Safety" 7 "Cranking stop required";
VAL_ 380 SwaSensorInternalStatus_EPS 0 "not calibrated, not indexed" 1 "not calibrated, indexed" 2 "fault" 3 "reserved" 4 "calibrated, not initialised" 5 "calibrated, initialised" 6 "reserved" 7 "reserved";
VAL_ 514 ABSinRegulation 0 "no ABS regulation" 1 "ABS in regulation";
VAL_ 514 ASRinRegulation 0 "no ASR regulation" 1 "ASR in regulation";
VAL_ 514 MSRinRegulation 0 "no MSR regulation" 1 "MSR in regulation";
VAL_ 514 ESCMalfunction 0 "No VDC (ESC) malfunction" 1 "VDC (ESC) malfunction";
VAL_ 514 AYCMalfunction 0 "no AYC malfunction" 1 "AYC malfunction";
VAL_ 514 AYCinRegulation 0 "no AYC regulation" 1 "AYC in regulation";
VAL_ 514 ASRMalfunction 0 "No ASR malfunction" 1 "ASR malfunction";
VAL_ 514 ABSMalfunction 0 "no ABS malfunction" 1 "ABS malfunction";
VAL_ 538 ePedalStatus 0 "e-Pedal OFF" 1 "e-Pedal ON";
VAL_ 546 ACCompValveDefault 0 "No AC Compressor valve default" 1 "AC Compressor valve default";
VAL_ 546 ACCompClutchStatus 0 "Compressor clutch off" 1 "Compressor clutch on";
VAL_ 562 KPL_D_VSC 0 "KPL false" 1 "KPL true";
VAL_ 562 Preset_D_VSC 0 "Upstream conditions not authenticated" 1 "Upstream conditions authenticated";
VAL_ 562 ICU_Mode_D_VSC 0 "Idle" 1 "Response 2" 2 "Challenge" 3 "SKey";
VAL_ 562 Clearing_Key_D_VSC 0 "CSK false" 1 "CSK request";
VAL_ 562 KPH_D_VSC 0 "KPH false" 1 "KPH true";
VAL_ 562 ICU_PayLoad_D_VSC 0 "Table Value430655";
VAL_ 566 TPU_Mode_D 0 "Idle" 1 "Response 1" 2 "SKey Request" 3 "Start Message";
VAL_ 566 VerlogStatus_D 0 "VerlogStatus UnProtected" 1 "VerlogStatus Protected";
VAL_ 566 SREM_D 0 "Normal request" 1 "Dev Request";
VAL_ 566 Version_D 0 "Version 5" 1 "Version 6" 2 "Version 7" 3 "Not Used";
VAL_ 566 TPU_Payload_D 0 "Table Value430666";
VAL_ 604 ParkingBrakeMalfunctionStatus 0 "No parking brake malfunction" 1 "Parking brake malfunction";
VAL_ 607 RPK_RemoteControlButton1State 0 "Released" 1 "Pressed";
VAL_ 607 DriverActionOnikey 0 "NoButtonPressed" 1 "ButtonPressed";
VAL_ 607 Ikey_status 0 "Not available" 1 "Inside the car" 2 "Outside the car" 3 "Out Of Range";
VAL_ 607 RPK_RemoteControlButton6State 0 "Released" 1 "Pressed";
VAL_ 607 RPK_RemoteControlButton5State 0 "Released" 1 "Pressed";
VAL_ 607 RPK_RemoteControlButton4State 0 "Released" 1 "Pressed";
VAL_ 607 RPK_RemoteControlButton3State 0 "Released" 1 "Pressed";
VAL_ 607 RPK_RemoteControlButton2State 0 "Released" 1 "Pressed";
VAL_ 650 VehicleSpeedClock 0 "This counter is incremented when CAN buffers are updated";
VAL_ 791 BlowerFanMotorStatus_AC 0 "Blower fan motor off" 1 "Blower fan motor on";
VAL_ 791 ACCompValveRequest 127 "No AC_Comp valve Request";
VAL_ 791 FrontDefrostRequest 0 "Front defrost not requested" 1 "Front defrost requested";
VAL_ 791 ACCompRequest 0 "No air conditionning requested" 1 "Air Conditioning Requested";
VAL_ 791 PTCNumberThermalRequest 0 "0 PTC requested" 1 "1 PTC requested" 2 "2 PTC requested" 3 "3 PTC requested" 4 "4 PTC requested" 5 "5 PTC requested" 6 "6 PTC requested" 7 "7 PTC requested" 8 "8 PTC requested" 9 "9 PTC requested" 10 "10 PTC requested" 11 "Not used" 12 "Not used" 13 "Not used" 14 "Not used" 15 "No request for PTC number thermal request";
VAL_ 791 PumpActivationRequest 0 "Unvailable Value" 1 "NO Pump Activation Requested" 2 "Pump Activation Requested" 3 "Not Used";
VAL_ 791 AC_StopAutoForbidden 0 "Not used" 1 "Auto Stop forbidden" 2 "Auto stop authorized" 3 "Not used";
VAL_ 791 AC_ClutchOpenForbidden 0 "Unavailable" 1 "Clutch openning forbidden" 2 "Clutch openning authorized" 3 "Not used";
VAL_ 791 ClimAT_EcoCustomAllowed 0 "Clim AT EcoCustomize Inhibit" 1 "Clim AT EcoCustomize Allowed";
VAL_ 791 RearDefrostRequest 0 "No rear defrost Requested" 1 "Rear defrost requested";
VAL_ 791 CoolerHilimitRequestForCVT 0 "Cooler Hilimit not requested" 1 "Cooler Hilimit requested";
VAL_ 791 VoltageRatebyAC 0 "No request" 1 "Rate 1" 2 "Rate 2" 3 "Rate 3";
VAL_ 791 AC_eCompInterlockHVconnector 0 "Disconnected" 1 "Connected " 2 "Not used " 3 "Unavailable ";
VAL_ 791 ISS_EcoActivationState 0 "Unavailable" 1 "ECO activated" 2 "ECO deactivated" 3 "Not used";
VAL_ 791 AirCondEcoActivationState 0 "Unavailable" 1 "ECO activated" 2 "ECO deactivated" 3 "Not used";
VAL_ 791 AC_ePTCInterlockHVconnector 0 "Disconnected" 1 "Connected " 2 "Not used" 3 "Unavailable ";
VAL_ 791 ClimECOModeStatusDisplay 0 "No display" 1 "Activated" 2 "Not Activated" 3 "Unavailable";
VAL_ 791 HVAC_ZEVmodeICEngineStartRequest 0 "No ICE engine starting request for ZEV mode" 1 "ICE engine starting request for ZEV mode";
VAL_ 796 SmearImageSelfGlare 0 "No Smear Image (Self Glare)" 1 "Smear Image (Self Glare)";
VAL_ 796 FoggyLights 0 "No Foggy Light (Foggy Spot)" 1 "Foggy Lights (Foggy Spot)";
VAL_ 796 BlurImage 0 "No Blur Image" 1 "Blur Image";
VAL_ 796 SplashesRoadSpray 0 "No Splash (Road Spray)" 1 "Splashes (Road Spray)";
VAL_ 796 LowSun 0 "No Low Sun" 1 "Low Sun";
VAL_ 796 PartialBlockage 0 "No Partial Blockage" 1 "Partial Blockage";
VAL_ 796 SmearedSpots 0 "No Smeared Spots" 1 "Smeared Spots";
VAL_ 796 FullBlockage 0 "No Full blockage" 1 "Full blockage";
VAL_ 796 OutOfFocusStatus 0 "In Focus" 1 "Out Of Focus";
VAL_ 796 CalibrationMisalignment 0 "Calibration OK" 1 "Calibration Misalignment";
VAL_ 796 SpotHalosFrozenWindshield 0 "No Spot Halo (Frozen Windshield)" 1 "Spot Halos (Frozen Windshield)";
VAL_ 796 SunRay 0 "No Sun Ray" 1 "Sun Ray";
VAL_ 796 ConstructionArea 0 "No Construction Area" 1 "Construction Area";
VAL_ 811 BCM_ACCompRequest 0 "No air conditionning requested" 1 "Air Conditioning Requested";
VAL_ 811 VoltageRateByBCM 0 "No request" 1 "Rate 1" 2 "Rate 2" 3 "Rate 3";
VAL_ 811 BCM_PumpActivationRequest 0 "No Pump Activation Requested" 1 "Pump Activation Requested" 2 "Not Used" 3 "Unavailable Value";
VAL_ 823 IoniserAutoLaunchState 0 "Unavailable" 1 "Auto launch activated" 2 "Auto launch not activated" 3 "Not used";
VAL_ 823 AQMAirFreshenerDisplayRequest 0 "No display (Air Freshener OFF)" 1 "Air Freshener ON display" 2 "Air Freshener refused display" 3 "Air Freshener delayed display";
VAL_ 823 ClimForcedRecyDisplay 0 "No display" 1 "Recycling On" 2 "Recycling OFF" 3 "Not Used";
VAL_ 823 HVeACComp_FaultType 0 "No failure and eAC ON" 1 "No failure and eAC OFF" 2 "Downgraded mode for eAC" 3 "Failure mode for eAC" 4 "eAC to be Change" 5 "Not Used" 6 "Not Used" 7 "Unavailable";
VAL_ 823 AQMIoniserModeState 0 "Unavailable" 1 "Off" 2 "Clean" 3 "Relax" 4 "Refused" 5 "Not used" 6 "Not used" 7 "Not used";
VAL_ 823 ClimAutoRecyclingDisplay 0 "Unavailable value" 1 "Automatic Recycling not in progress" 2 "Automatic Recycling in progress" 3 "Not Used";
VAL_ 823 HVPTC_FaultType 0 "No failure and HV PTC ON" 1 "No failure and HV PTC OFF" 2 "Downgraded mode for HV PTC" 3 "Failure mode for HV PTC" 4 "To Change HV PTC" 5 "Not used" 6 "Not used" 7 "Unavailable";
VAL_ 826 ADB_TypeObject1_v3 0 "Oncoming Vehicle / Headlamp" 1 "Preceding Vehicle / TailLamp" 2 "Oncoming Vehicle / Pair of Headlamp" 3 "Preceding Vehicle / Pair of TailLamp" 4 "Cluster" 5 "Strong reflector" 6 "Couple of OC upper truck lights" 7 "Unavailable";
VAL_ 828 ADB_TypeObject3_v3 0 "Oncoming Vehicle / Headlamp" 1 "Preceding Vehicle / TailLamp" 2 "Oncoming Vehicle / Pair of Headlamp" 3 "Preceding Vehicle / Pair of TailLamp" 4 "Cluster" 5 "Strong reflector" 6 "Couple of OC upper truck lights" 7 "Unavailable";
VAL_ 855 ADB_TypeObject2_v3 0 "Oncoming Vehicle / Headlamp" 1 "Preceding Vehicle / TailLamp" 2 "Oncoming Vehicle / Pair of Headlamp" 3 "Preceding Vehicle / Pair of TailLamp" 4 "Cluster" 5 "Strong reflector" 6 "Couple of OC upper truck lights" 7 "Unavailable";
VAL_ 872 ADB_TypeObject4_v3 0 "Oncoming Vehicle / Headlamp" 1 "Preceding Vehicle / TailLamp" 2 "Oncoming Vehicle / Pair of Headlamp" 3 "Preceding Vehicle / Pair of TailLamp" 4 "Cluster" 5 "Strong reflector" 6 "Couple of OC upper truck lights" 7 "Unavailable";
VAL_ 873 ADB_TypeObject5_v3 0 "Oncoming Vehicle / Headlamp" 1 "Preceding Vehicle / TailLamp" 2 "Oncoming Vehicle / Pair of Headlamp" 3 "Preceding Vehicle / Pair of TailLamp" 4 "Cluster" 5 "Strong reflector" 6 "Couple of OC upper truck lights" 7 "Unavailable";
VAL_ 908 VirutalKeyRKE_Request 0 "Table Value609471";
VAL_ 911 FrontRightDefrostRequest 0 "Front right defrost not requested" 1 "Front right defrost requested";
VAL_ 911 FrontLeftDefrostRequest 0 "Front left defrost not requested" 1 "Front left defrost requested";
VAL_ 913 ADB_TypeObject6_v3 0 "Oncoming Vehicle / Headlamp" 1 "Preceding Vehicle / TailLamp" 2 "Oncoming Vehicle / Pair of Headlamp" 3 "Preceding Vehicle / Pair of TailLamp" 4 "Cluster" 5 "Strong reflector" 6 "Couple of OC upper truck lights" 7 "Unavailable";
VAL_ 914 ADB_TypeObject7_v3 0 "Oncoming Vehicle / Headlamp" 1 "Preceding Vehicle / TailLamp" 2 "Oncoming Vehicle / Pair of Headlamp" 3 "Preceding Vehicle / Pair of TailLamp" 4 "Cluster" 5 "Strong reflector" 6 "Couple of OC upper truck lights" 7 "Unavailable";
VAL_ 925 ADB_TypeObject8_v3 0 "Oncoming Vehicle / Headlamp" 1 "Preceding Vehicle / TailLamp" 2 "Oncoming Vehicle / Pair of Headlamp" 3 "Preceding Vehicle / Pair of TailLamp" 4 "Cluster" 5 "Strong reflector" 6 "Couple of OC upper truck lights" 7 "Unavailable";
VAL_ 930 ADAS_DefoggingModeRequest 0 "no request" 1 "Request";
VAL_ 930 DetectedLatMovingObject 0 "Not Detected" 1 "Detected";
VAL_ 930 OSE_R_RetentionReq2 0 "No Request" 1 "Rear Request" 2 "Front Request" 3 "Both Request" 4 "Not used" 5 "Not used" 6 "Not used" 7 "Unavailable";
VAL_ 930 OSE_L_RetentionReq2 0 "No Request" 1 "Rear Request" 2 "Front Request" 3 "Both Request" 4 "Not used" 5 "Not used" 6 "Not used" 7 "Unavailable";
VAL_ 934 APA_StatusDisplay2 0 "Automatic maneuver OFF" 1 "Automatic maneuver Standby" 2 "Automatic maneuver ON" 3 "Not Used";
VAL_ 934 RPK_status 0 "OFF" 1 "Waiting Move" 2 "Maneuver In Progress" 3 "Not used";
VAL_ 934 iKeyPositionRequest 0 "No Request" 1 "Request";
VAL_ 939 EBA_MajorFailure 0 "No Failure" 1 "Failure";
VAL_ 941 BMS12V_SafetyAlert 0 "No alert" 1 "Low level Alert" 2 "High level Alert" 3 "Not used";
VAL_ 944 RPES_Status 0 "Not available" 1 "RPES_Forbidden" 2 "RPES_Wait_For_Req" 3 "RPES_StartInProgress" 4 "RPES_EngineRunning" 5 "RPES_Interrupt" 6 "Not Used" 7 "Not Used";
VAL_ 962 APA_StatusDisplay 0 "Automatic maneuver OFF" 1 "Automatic maneuver Standby" 2 "Automatic maneuver ON" 3 "Not Used";
VAL_ 970 VirtualKeyActivationStatus 0 "Virtual Key is deactivated" 1 "Virtual Key is activated";
VAL_ 977 LiB_RLY_OFF_Inhibition 0 "LiB RLY OFF permission" 1 "LiB RLY OFF inhibition";
VAL_ 980 ADB_CameraWeather 0 "Clear" 1 "Rain" 2 "Fog" 3 "Snow";
VAL_ 980 ADB_TunnelDetection 0 "Tunnel not detected" 1 "Tunnel detected";
VAL_ 980 CameraStatus 0 "Initialization" 1 "Camera operational" 2 "Camera on default" 3 "Not used";
VAL_ 980 ADB_TrafficSideDetection 0 "No traffic side detected" 1 "Left hand traffic detected" 2 "Right hand traffic detected" 3 "Not used";
VAL_ 980 ADB_RoadType 0 "Unknown" 1 "Highway" 2 "Inner city" 3 "Not used";
VAL_ 999 Right_KeyAuthentResult 0 "No Answer" 1 "Kick Detected_RH";
VAL_ 999 Left_KeyAuthentResult 0 "No Answer" 1 "Kick Detected_LH";
VAL_ 1000 RemoteHorn_HFM 0 "No request" 1 "Horn OFF request" 2 "Horn ON request" 3 "Not used";
VAL_ 1000 RemoteLight_HFM 0 "No request" 1 "Remote lighting request";
VAL_ 1000 RKE_ID_DetectStatus 0 "No existing" 1 "User 1" 2 "User 2" 3 "User 3" 4 "User 4" 5 "Not Used" 6 "Not Used" 7 "Not Used";
VAL_ 1000 IkeyfobInsideVehicleFound 0 "No ikeyfob inside vehicle" 1 "1 ikeyfob found inside vehicle" 2 "2 ikeyfob found inside vehicle" 3 "3 ikeyfob found inside vehicle" 4 "4 ikeyfob found inside vehicle" 5 "Not used" 6 "Not used" 7 "Unavailable";
VAL_ 1000 HFMBatTempoRequest 0 "No delayed battery power supply Request" 1 "Delayed battery power supply Request";
VAL_ 1000 APPRUN_ActivationState 0 "Approach Unlock is deactivated (initial value)" 1 "Approach Unlock is activated";
VAL_ 1000 WAL_ActivationState 0 "Walk Away Locking is deactivated (initial value)" 1 "Walk Away Locking is activated";
VAL_ 1000 IKeyRemoteUnProtectStatus 0 "Protect" 1 "UnProtect";
VAL_ 1000 TrunkCancelSwitchState 0 "Trunk Cancel Switch OFF" 1 "Trunk Cancel Switch ON";
VAL_ 1000 IKeyAccessActivationState 0 "iKey Access is Desactivated" 1 "iKey Access is Activated";
VAL_ 1000 iKeyFobAuthentStatus 0 "Authentication not done" 1 "Authentication OK Hand free" 2 "Authentication failed Hand free" 3 "Authentication OK Kazashi" 4 "Authentication failed Kazashi" 5 "Identification OK" 6 "Identification failed" 7 "Not used";
VAL_ 1000 HFM_Refuse_to_Sleep 0 "reserved" 1 "HFM refuse to sleep " 2 "HFM ready to sleep" 3 "reserved";
VAL_ 1000 VPA_R_PSD_Request 0 "No request" 1 "Full close request" 2 "Full open request" 3 "Stop request";
VAL_ 1000 BackDoorHandleSwitchState 0 "handle switch not pressed" 1 "handle switch pressed";
VAL_ 1000 RearRightHandleSwitchState 0 "handle switch not pressed" 1 "handle switch pressed";
VAL_ 1000 RearLeftHandleSwitchState 0 "handle switch not pressed" 1 "handle switch pressed";
VAL_ 1000 FrontRightHandleSwitchState 0 "handle switch not pressed" 1 "handle switch pressed";
VAL_ 1000 FrontLeftHandleSwitchState 0 "handle switch not pressed" 1 "handle switch pressed";
VAL_ 1000 RESpresSoak_ProgCancel 0 "No request" 1 "Programmation to be cancelled";
VAL_ 1000 RearZonePollingResult 0 "No search" 1 "Searching" 2 "No Key Detect" 3 "Key Detect";
VAL_ 1000 VPA_L_PSD_Request 0 "No request" 1 "Full close request" 2 "Full open request" 3 "Stop request";
VAL_ 1000 UserIdent_Ikey 0 "No Ident" 1 "ID1" 2 "ID2" 3 "ID3" 4 "ID4" 5 "VK_ID1" 6 "VK_ID2" 7 "VK_ID3" 8 "VK_ID4" 9 "VK_ID5" 10 "VK_ID6" 11 "Not used" 12 "Not used" 13 "Not used" 14 "Not used" 15 "Not used";
VAL_ 1000 IkeyfobInsideVehicleFound_VK 0 "No ikeyfob inside vehicle" 1 "1 ikeyfob found inside vehicle" 2 "2 ikeyfob found inside vehicle" 3 "3 ikeyfob found inside vehicle" 4 "4 ikeyfob found inside vehicle" 5 "Not used" 6 "Not used" 7 "Unavailable";
VAL_ 1000 VKAuthRequest 0 "No Request" 1 "VK authentication request";
VAL_ 1000 VehicleInsideKeyIdentResult 0 "No search" 1 "Searching" 2 "No Ident" 3 "Ident";
VAL_ 1000 OutsideZoneKeyIdentResult 0 "No search" 1 "Searching" 2 "No Ident" 3 "Ident";
VAL_ 1000 OutsideZonePollingResult 0 "No search" 1 "Searching" 2 "No Key Detect" 3 "Key Detect";
VAL_ 1010 ATCU_ParkOutPairingStatus 0 "Blank" 1 "Coded";
VAL_ 1010 ATCU_ParkOutAntiScanningStatus 0 "Anti Scanning OFF" 1 "Anti Scanning ON";
VAL_ 1010 ATCU_ParkOutAuthorizationStatus 0 "Park-out forbidden" 1 "Park-out authorized";
VAL_ 1011 InsideIkeyfobSearchRequest 0 "No Request (default value)" 1 "ikeyfob inside vehicle search request";
VAL_ 1012 ECALL_State_EDR 0 "Operational" 1 "Malfunction" 2 "Reserved" 3 "Unavailable";
VAL_ 1020 MinimumSafetyEnergyLevel_48V 0 "Unavailable" 1 "Safety energy level available" 2 "No safety energy level available" 3 "Not Used";
VAL_ 1021 HNS_Failure_status 0 "Initialization" 1 "Diagnosis requested" 2 "No failure" 3 "Failure";
VAL_ 1021 HNS_StopAutoForbidden 0 "Stop Auto forbidden" 1 "Stop Auto authorized";
VAL_ 1021 HNS_Switching_Status 0 "Diagnosis on going" 1 "Open" 2 "Closed" 3 "Invalid";
VAL_ 1045 SecondRightSeatModeReq 0 "No request" 1 "Seat Heater" 2 "Seat Ventilation" 3 "Not used";
VAL_ 1045 SecondLeftSeatModeReq 0 "No request" 1 "Seat Heater" 2 "Seat Ventilation" 3 "Not used";
VAL_ 1045 FrontRightSeatModeReq 0 "No request" 1 "Seat Heater" 2 "Seat Ventilation" 3 "Not used";
VAL_ 1045 FrontLeftSeatModeReq 0 "No request" 1 "Seat Heater" 2 "Seat Ventilation" 3 "Not used";
VAL_ 1049 VoltageRateByAAM 0 "No request" 1 "Rate 1" 2 "Rate 2" 3 "Rate 3";
VAL_ 1054 EEM_Dynamic_PowerLimitation 0 "No Auxiliary load current limitation" 1 "Step1 Auxiliary load current limitation" 2 "Step2 Auxiliary load current limitation" 3 "Step3 Auxiliary load current limitation" 4 "Step4 Auxiliary load current limitation" 5 "Not Used" 6 "Not Used" 7 "Unavailable value";
VAL_ 1054 HVlightChargeAuthorization 0 "Not authorized" 1 "Authorized";
VAL_ 1054 FirstStartBSGSelection 0 "BSG selected for cranking" 1 "BSG not selected for cranking";
VAL_ 1055 TIAlertStatusForHVAC 0 "No Alert" 1 "Alert";
VAL_ 1058 ADB_AmbientLight 0 "Day" 1 "Night" 2 "Twilight" 3 "Not used";
VAL_ 1064 EEM_LoB_PowerLimitationRequest 0 "No request" 1 "Power limitation in LifeOnBoard - Low HV SOC";
VAL_ 1064 HVcoolingLoopValveStatus 0 "Unavailable" 1 "Electrical power unit to the chiller/battery" 2 "Electrical power unit to the radiator" 3 "Not used";
VAL_ 1065 BatteryCoolingForbidden 0 "Not Forbiden" 1 "Forbiden";
VAL_ 1066 StatusOfHighVoltagePowerSupply 0 "High Voltage not supply" 1 "High Voltage supply";
VAL_ 1067 WaterHeaterLoopModeStatus 0 "Large Loop with ICE Engine" 1 "Short loop without ICE Engine";
VAL_ 1067 BatVEShutDownAlert 0 "Unavailable" 1 "No +BAT VE shut down alert" 2 "+BAT VE Shut down alert" 3 "Not used";
VAL_ 1067 HV_ePTC_FreezeRequest 0 "No request" 1 "Freeze ePTC request";
VAL_ 1067 HVPTC_ON_permission 0 "High voltage heater (PTC) forbidden" 1 "High voltage heater (PTC) authorization";
VAL_ 1068 HVchargerStatus 0 "No HV charge" 1 "HV battery charge" 2 "HV consumers charge" 3 "Not used";
VAL_ 1068 VehicleTractionMode 0 "Vehicle not in traction mode" 1 "Vehicle in charge" 2 "Vehicle in full electric mode" 3 "Vehicle in hybrid serial mode" 4 "Vehicle in thermic mode" 5 "Vehicle in hybrid parallel mode" 6 "Not Used" 7 "Unavailable value";
VAL_ 1076 BadgeBatteryLow 0 " No Display request (badge battery OK)" 1 "badge battery low";
VAL_ 1076 UserIdent_RKE 0 "None" 1 "RKE1" 2 "RKE2" 3 "RKE3" 4 "RKE4" 5 "Personal devices" 6 "Voice Personal Assistant" 7 "Not used";
VAL_ 1076 UserIdent_HandFree 0 "None" 1 "Hand Free Font Left" 2 "Hand Free Font Right" 3 "Hand Free Rear Left" 4 "Hand Free Rear Right" 5 "Hand Free BackDoor or Trunk" 6 "Not used" 7 "Not used";
VAL_ 1076 HFM_RKE_Request 0 "No request" 1 "Not used" 2 "Short Press - Lock" 3 "Short Press - Unlock" 4 "Short Press -  Backdoor or Trunk" 5 "Short Press - Panic" 6 "Short Press - PowerSlidingDoorRH" 7 "Short Press - PowerSlidingDoorLH" 8 "Short Press - Remote Lighting" 9 "Short Press - RES" 10 "Short Press - Roof" 11 "Remote Lock" 12 "Remote Unlock" 13 "Short Press - Unlock Cockpit requested" 14 "Short Press - Unlock Loading Area requested" 15 "Short Press - EV unlock and/or Stop charge request" 16 "Released Button-Backdoor or Trunk" 17 "Not used" 18 "Long Press - Lock" 19 "Long Press - Unlock" 20 "Long Press - Backdoor or Trunk" 21 "Long Press - Panic" 22 "Long Press - PowerSlidingDoorRH" 23 "Long Press - PowerSlidingDoorLH" 24 "Long Press - Remote Lighting" 25 "Long Press - RES" 26 "Long Press - Roof" 27 "Very Long - Lock & Unlock" 28 "Not used" 29 "Not used" 30 "Not used" 31 "Unavailable";
VAL_ 1076 ESCL_Status 6 "ESCL unlocked" 9 "ESCL locked" 17 "ESCL Failed" 33 "Status Unknown";
VAL_ 1076 SteeringLockFailure 0 "no steering lock  failure" 1 "steering column locking failure" 2 "steering colum unlocking failure" 3 "reserved";
VAL_ 1076 PushtoStartButtonStatus 0 "Start button OK" 1 "Start button failed";
VAL_ 1076 SwitchOffSESDisturbers 0 "No request" 1 "Disturbers switch off requested";
VAL_ 1076 PushtoStartButton 0 "No Button pressed" 1 "Push to Start button is pressed";
VAL_ 1076 StopInductiveChargingRequest 0 "No request" 1 "Stop Inductive Charging Requested";
VAL_ 1076 HFM_HandFree_Request_v2 0 "No Request" 1 "Handfree Unlock (Push to Unlock)" 2 "UnLock by APRUN" 3 "Handfree Lock (Push to Lock)" 4 "Lock by WAC" 5 "Handfree back door operation authorized" 6 "ETA Kick detected and CID authenticated" 7 "Partial Unlock" 8 "HandFree_Left_Authorized" 9 "HandFree_Right_Authorized" 10 "Not used" 11 "Not used" 12 "Not used" 13 "Not used" 14 "Not used" 15 "Not used";
VAL_ 1076 CustomerDepartureDetected 0 "No card identifier departure detected" 1 "Card identifier departure detected";
VAL_ 1076 CustomerApproachDetected 0 "No card identifier detected" 1 "Card identifier detected";
VAL_ 1076 RESPreSoak_ImmediateReq_HFM 0 "No Request" 1 "Presoaking or Engine Start Request" 2 "Presoaking or Engine Stop Request" 3 "Double Time Request";
VAL_ 1082 VPA_PBD_Request 0 "No request" 1 "Full close request" 2 "Full open request" 3 "Latch release request" 4 "Stop request" 5 "Not Used" 6 "Not Used" 7 "Not Used";
VAL_ 1082 RequesterID 0 "No Request" 1 "Off board" 2 "VPA" 3 "Bluetooth";
VAL_ 1086 HVAC_PowerSupplyMaintain 0 "No need of Power Supply" 1 "HVAC Power supply maintain request";
VAL_ 1086 HVAC_PresoakActivationStatus 0 "Presoak Forbidden" 1 "No Presoak in progress" 2 "Presoak in progress" 3 "Unavailable";
VAL_ 1086 AC_CustomerRequest 0 "No AC customer request" 1 "AC customer request";
VAL_ 1086 COMPR_ON_flag 0 "Compressor OFF" 1 "Compressor ON";
VAL_ 1086 ACMinEngineIdleSpeedRequest 15 "No AC minimum engine idle speed request";
VAL_ 1086 EngineWaterValveClosingAuthor 0 "No water valve closure authorised" 1 "Water valve closure authorised";
VAL_ 1086 EngineWaterValveClosingRequest 0 "No water valve closure requested" 1 "Water valve closure requested";
VAL_ 1086 AirShutterClosingRequest 0 "No Air Shutters Closure Request" 1 "Air Shutters Closure Request";
VAL_ 1086 AirShutterOpeningRequest 0 "No Air Shutters Opening Request" 1 "Air Shutters Opening Request";
VAL_ 1093 Airsusp_Failure 0 "Table Value362330";
VAL_ 1093 Airsusp_CalibrationStatus 0 "No calibration" 1 "Normal" 2 "Abnormal" 3 "Reserved";
VAL_ 1094 KPL_VSC 0 "KPL false" 1 "KPL true";
VAL_ 1094 Preset_VSC 0 "Upstream conditions not authenticated" 1 "Upstream conditions authenticated";
VAL_ 1094 ICU_Mode_VSC 0 "Idle" 1 "Response 2" 2 "Challenge" 3 "SKey";
VAL_ 1094 Clearing_Key_VSC 0 "CSK false" 1 "CSK request";
VAL_ 1094 KPH_VSC 0 "KPH false" 1 "KPH true";
VAL_ 1094 ICU_PayLoad_VSC 0 "Table Value420138";
VAL_ 1096 TPU_Mode 0 "Idle" 1 "Response 1" 2 "SKey Request" 3 "Start Message";
VAL_ 1096 VerlogStatus 0 "VerlogStatus UnProtected" 1 "VerlogStatus Protected";
VAL_ 1096 SREM 0 "Normal request" 1 "Dev Request";
VAL_ 1096 Version 0 "Version 5" 1 "Version 6" 2 "Version 7" 3 "Not Used";
VAL_ 1096 TPU_Payload 0 "Table Value159547";
VAL_ 1099 ATCVTFail 0 "Not fail" 1 "Fail";
VAL_ 1101 WheelStateRL_twin 0 "Pressure ok and no failure" 1 "Failure" 2 "Underinflation" 3 "Underinflation and failure" 4 "Puncture" 5 "Puncture and failure" 6 "Puncture and underinflation" 7 "Puncture and underinflation and failure";
VAL_ 1101 WheelStateRR_twin 0 "Pressure ok and no failure" 1 "Failure" 2 "Underinflation" 3 "Underinflation and failure" 4 "Puncture" 5 "Puncture and failure" 6 "Puncture and underinflation" 7 "Puncture and underinflation and failure";
VAL_ 1103 CockpitLocked_State 0 "Not Locked" 1 "Locked";
VAL_ 1103 Right_iKeyFobAuthent_Request 0 "No request" 1 "Right Authent request";
VAL_ 1103 Left_iKeyFobAuthent_Request 0 "No request" 1 "Left Authent request";
VAL_ 1103 LoadingAreaLocked_State 0 "Loading area Not Locked" 1 "Loading area Locked";
VAL_ 1104 ExternalTempDisplayUnit 0 "display mode in °C" 1 "display mode in °F";
VAL_ 1104 FuelLevelDisplayed 0 "petrol tank reserve";
VAL_ 1105 DayNightForBacklights 0 "Day" 1 "Twilight" 2 "Night" 3 "Unavailable";
VAL_ 1105 ParkingBrakeStatus 0 "Not used" 1 "Automatic or manual Parking brake not applied" 2 "Automatic or manual Parking brake applied" 3 "Unavailable";
VAL_ 1105 LowBrakeFluidLevelStatus 0 "Unavailable" 1 "No brake system malfunction" 2 "Brake system malfunction" 3 "Not used";
VAL_ 1106 DayNightStatusForB_Switches 0 "Conditionned backlight" 1 "Permanent backlight";
VAL_ 1107 NeutralContact 0 "not used" 1 "neutral contact not reached" 2 "neutral contact reached" 3 "unavailable";
VAL_ 1107 RearGearEngaged 0 "Not used" 1 "Rear Gear not Engaged" 2 "Rear Gear Engaged" 3 "unavailable";
VAL_ 1107 EngineHoodState 0 "Unvailable value" 1 "Hood opened" 2 "Hood closed" 3 "Not used";
VAL_ 1107 BattWarnReq_Level_Hi_USM_v2 0 "Not used" 1 "No Alert" 2 "Alert" 3 "Unavailable value";
VAL_ 1107 IgnitionSupplyConfirmation 0 "no primary ignition supply" 1 "primary ignition supply on";
VAL_ 1107 BattSetPointGeneratorStatus_V2 0 "Nominal mode" 1 "Relative undervoltage confirmed" 2 "Absolute undervoltage confirmed" 3 "Overvoltage confirmed" 4 "Voltage measurement fault confirmed" 5 "Battery disconnected confirmed" 6 "Performances undervoltage confirmed" 7 "Not used";
VAL_ 1107 StarterStatus 0 "cranking relay switched off" 1 "short relaxation active" 2 "long relaxation active" 3 "cranking relay switched on";
VAL_ 1107 EEM_StaticPowerLimitationRequest 0 "No Request" 1 "Life on Board Low SOC power limitation" 2 "Delivery Mode power limitation" 3 "Battery Disconnection power limitation" 4 "Producer failure power limitation" 5 "Not used" 6 "Not used" 7 "Not used";
VAL_ 1107 UnderStarterRelayCondition 0 "Unavailable" 1 "Under Starter Rly voltage LOW" 2 "Under Starter Rly voltage HIGH" 3 "Not used";
VAL_ 1107 FrontWiperStopPosition 0 "stop position not reached" 1 "stop position reached";
VAL_ 1107 LowBeamActivationStatus 0 "lowbeam OFF" 1 "lowbeam ON" 2 "Partial Lowbeam Failure" 3 "Total Lowbeam Failure";
VAL_ 1107 USM_RefuseToSleep 0 "reserved" 1 "USM refuse to sleep " 2 "USM ready to sleep" 3 "reserved";
VAL_ 1107 EEM_HighSpeedStopForbidden 0 "High Speed stop forbidden - EEM malfunction detected" 1 "High Speed stop forbidden" 2 "High Speed stop authorized" 3 "High Speed stop forbidden - EEM malfunction - recranking forbidden";
VAL_ 1107 EEM_ConditionsForAD_byUSM 0 "Not operational without Failure" 1 "Operational" 2 "Not operational with Failure" 3 "reserved";
VAL_ 1108 HandDrivingActivationState 0 "Right Hand Driving activated" 1 "Left Hand Driving activated";
VAL_ 1108 LowBatteryVoltageDisplay 0 "No display request" 1 "Battery weak" 2 "Battery weak : start engine" 3 "Battery in charge";
VAL_ 1108 AFS_ActivationState 0 "AFS activated" 1 "AFS deactivated";
VAL_ 1108 EEM_SailingIdleForbidden 0 "Sailing idle forbidden - EEM malfunction detected" 1 "Sailing idle forbidden" 2 "Sailing idle authorized" 3 "Not used";
VAL_ 1108 LowBeamFailureDisplay_v3 0 "No Low Beam Failure" 1 "Low Beam Failure" 2 "Not used" 3 "Low Beam Failure re-emission";
VAL_ 1108 IdleSpeedInhibitionRequest 0 "Unavalaible Value" 1 "IdleSpeed Inhibition Requested" 2 "IdleSpeed Inhibition not Requested" 3 "Not Used";
VAL_ 1108 FrontWiperStatus 0 "front wiper stopped" 1 "low speed active" 2 "high speed active" 3 "not used";
VAL_ 1108 BattWarnReq_Level_Lo_USM 0 "No Request" 1 "Request";
VAL_ 1108 EEM_RegulationLoopActivationReq 0 "No Activation Request" 1 "Activation Request Level1" 2 "Activation Request Level2" 3 "Not used";
VAL_ 1108 STCUT_STRLY_Condition 0 "IS_ST relay opened and ST_CUT relay opened" 1 "IS_ST relay closed and ST_CUT relay opened" 2 "Invalid" 3 "ST_CUT relay closed";
VAL_ 1108 STRLY_FailureAlert 0 "Alert OFF" 1 "Alert ON";
VAL_ 1108 STCUT_RLY_Status 0 "Not used" 1 "ST CUT RLY OFF" 2 "ST CUT RLY ON" 3 "Unavailable";
VAL_ 1108 SecStorage12V_ConnectionDiag 0 "Not connected nominal" 1 "Connected nominal" 2 "Not connected not nominal" 3 "Connected not nominal";
VAL_ 1108 GenMode_v2 0 "GENMODE0 Limitation requested by Engine" 1 "GENMODE1 Nominal strategy Mode" 2 "GENMODE2 ESM intermediate Mode" 3 "GENMODE3 Battery protection" 4 "GENMODE4 ESM Discharge Mode" 5 "GENMODE5 ESM Regeneration Mode" 6 "GENMODE7 ESM inhibited by actuator" 7 "GENMODE9 MinimumVoltageByECM";
VAL_ 1108 Powernet_MinimumVoltageReq 0 "Minimum Voltage Not requested" 1 "Minimum Voltage requested";
VAL_ 1108 EEM_StopAutoForbidden 0 "Stop Auto Forbidden - EEM malfunction detected" 1 "Stop Auto forbidden" 2 "Stop Auto authorized" 3 "Not used";
VAL_ 1108 ManualLevellingPositionDisplay 0 "Not display" 1 "Leveling display request";
VAL_ 1108 EEM_RegulationLoopActivReq_v2 0 "No Activation Request" 1 "Activation Request Level1" 2 "Activation Request Level2" 3 "RESERVED" 4 "Activation Request for CAN activity" 5 "Not Used" 6 "Not Used" 7 "Not Used";
VAL_ 1108 FrontWiperDiagStatus 0 "No Failure" 1 "Failure";
VAL_ 1108 Storage12V_SwitchRequest 0 "Disconnection request" 1 "Connection request";
VAL_ 1108 Storages12V_TAforbidden 0 "Torque Assist forbidden" 1 "Take-off torque assist forbidden" 2 "Acceleration torque assist forbiden" 3 "Torque assist authorized";
VAL_ 1108 AD_ExtSignalizationFailure 0 "No malfunction detected" 1 "Malfunction detected";
VAL_ 1109 EBAfailureDisplayAlert 0 "No Failure" 1 "Failure";
VAL_ 1109 BrakingSystemStateDisplayRequest 0 "No failure" 1 "Failure";
VAL_ 1109 EBDstateDisplayRequest 0 "No failure" 1 "Failure";
VAL_ 1109 ABSstateDisplayRequest 0 "No failure" 1 "Failure" 2 "In ext diag session" 3 "To be calibrated";
VAL_ 1109 VDCstateDisplayRequest 0 "No failure and no control" 1 "Failure" 2 "In active control" 3 "Not used";
VAL_ 1109 VDCactivationState 0 "VDC function activated" 1 "VDC function deactivated";
VAL_ 1109 TPW_Status 0 "System OK" 1 "Tyre under inflated" 2 "Failure" 3 "TPW not operational";
VAL_ 1110 BMS12V_DisconnectionDetection 0 "Connected or switch opened" 1 "Disconnected with switch closed";
VAL_ 1110 BMS12V_SwitchState 0 "Opened" 1 "Closed";
VAL_ 1110 BMS12V_StorageFailure 0 "Limit mode" 1 "Failure mode" 2 "Nominal mode" 3 "Not used";
VAL_ 1121 AirSUSP_SystemStatus 0 "AirSUSP System OFF" 1 "AirSUSP System ON-Standbye" 2 "AirSUSP System ON-Adjusting" 3 "Initialize" 4 "Reserve" 5 "Reserve" 6 "Reserve" 7 "Reserve";
VAL_ 1125 KPL_B_VSC 0 "KPL false" 1 "KPL true";
VAL_ 1125 Preset_B_VSC 0 "Upstream conditions not authenticated" 1 "Upstream conditions authenticated";
VAL_ 1125 ICU_Mode_B_VSC 0 "Idle" 1 "Response 2" 2 "Challenge" 3 "SKey";
VAL_ 1125 Clearing_Key_B_VSC 0 "CSK false" 1 "CSK request";
VAL_ 1125 KPH_B_VSC 0 "KPH false" 1 "KPH true";
VAL_ 1125 ICU_PayLoad_B_VSC 0 "Table Value420136";
VAL_ 1126 TPU_Mode_B 0 "Idle" 1 "Response 1" 2 "SKey Request" 3 "Start Message";
VAL_ 1126 VerlogStatus_B 0 "VerlogStatus UnProtected" 1 "VerlogStatus Protected";
VAL_ 1126 SREM_B 0 "Normal request" 1 "Dev Request";
VAL_ 1126 Version_B 0 "Version 5" 1 "Version 6" 2 "Version 7" 3 "Not Used";
VAL_ 1126 TPU_Payload_B 0 "Table Value159545";
VAL_ 1127 KPL_C_VSC 0 "KPL false" 1 "KPL true";
VAL_ 1127 Preset_C_VSC 0 "Upstream conditions not authenticated" 1 "Upstream conditions authenticated";
VAL_ 1127 ICU_Mode_C_VSC 0 "Idle" 1 "Response 2" 2 "Challenge" 3 "SKey";
VAL_ 1127 Clearing_Key_C_VSC 0 "CSK false" 1 "CSK request";
VAL_ 1127 KPH_C_VSC 0 "KPH false" 1 "KPH true";
VAL_ 1127 ICU_PayLoad_C_VSC 0 "Table Value420137";
VAL_ 1128 TPU_Mode_C 0 "Idle" 1 "Response 1" 2 "SKey Request" 3 "Start Message";
VAL_ 1128 VerlogStatus_C 0 "VerlogStatus UnProtected" 1 "VerlogStatus Protected";
VAL_ 1128 SREM_C 0 "Normal request" 1 "Dev Request";
VAL_ 1128 Version_C 0 "Version 5" 1 "Version 6" 2 "Version 7" 3 "Not Used";
VAL_ 1128 TPU_Payload_C 0 "Table Value159546";
VAL_ 1136 VoltageRegulationStatus_V2 0 "Not initialized" 1 "Starting sequence" 2 "Nominal Mode" 3 "Producer power limitation" 4 "Producer communication fault is detected" 5 "Producer communication fault is confirmed" 6 "Producer fault is detected" 7 "Producer fault is confirmed" 8 "Undervoltage is detected" 9 "Undervoltage is confirmed" 10 "Overvoltage is detected" 11 "Overvoltage is confirmed" 12 "CAN fault is detected" 13 "CAN fault is confirmed" 14 "Not used" 15 "Unavailable";
VAL_ 1136 ESS_AutoStartImpossible 0 "Auto start impossible not confirmed" 1 "Auto start impossible confirmed";
VAL_ 1137 Maintenance_Mode_Status 0 "not used" 1 "no request" 2 "request" 3 "unavailable";
VAL_ 1137 CruiseControlStatus 0 "Cruise Control (CC) and Speed Limit (SL) OFF" 1 "SL active" 2 "SL on and (awaiting or suspended)" 3 "SL requested and in failure" 4 "CC active" 5 "CC ON and ( awaiting  or suspended)" 6 "CC requested and in failure" 7 "Vehicle not equipped with CC/SL / Not available";
VAL_ 1139 VoltageRateByECM_V2 0 "No request" 1 "Rate 1" 2 "Rate 2" 3 "Rate 3" 4 "Rate 4" 5 "Not used" 6 "Not used" 7 "Not used";
VAL_ 1139 DBC_FailureStatus_v2 0 "No DBC failure" 1 "DBC minor failure" 2 "DBC major failure" 3 "Not used";
VAL_ 1139 EngineCoolantFlowStatus 0 "Unavailable" 1 "No EngineCoolantFlow" 2 "EngineCoolantFlow" 3 "Not Used";
VAL_ 1139 IG_OFF_DELAY_REQUEST 0 "Not requested" 1 "Requested";
VAL_ 1139 LowPressureACCut 0 "Low Pressure Gaz cut state" 1 "Not low Pressure Gaz cut state";
VAL_ 1139 ProducerLossDetectionStatus 0 "Producer is not lost" 1 "Producer is confirmed lost";
VAL_ 1140 LKA_AlertStatus 0 "No alert" 1 "Right alert" 2 "Left alert" 3 "Not used";
VAL_ 1143 RESstatus 0 "Unavailable" 1 "Reserved for safety" 2 "Reserved for safety" 3 "Normal engine start only" 4 "Reserved for safety" 5 "Reserved for safety" 6 "wait for RES / Presoak" 7 "Reserved for safety" 8 "Reserved for safety" 9 "Customer Starting" 10 "Reserved for safety" 11 "Reserved for safety" 12 "Remote Engine Start" 13 "Reserved for safety" 14 "Reserved for safety" 15 "Vehicle without RES";
VAL_ 1143 RearRightDoorState 0 "Unavailable Value" 1 "Rear Right door closed" 2 "Rear Right door open" 3 "Not Used";
VAL_ 1143 StartingMode_BCM 0 "Powertrain Stopped Request" 1 "No request" 2 "Ignition Request" 3 "Starting Request";
VAL_ 1143 SafetyLineDiagState 0 "Safety line Unavailable" 1 "Safety line Grounded" 2 "Safety line at 12V" 3 "Safety Line Failure";
VAL_ 1143 DriverDoorState 0 "Unavailable Value" 1 "Driver door closed" 2 "Driver door open" 3 "Not Used";
VAL_ 1143 LowBeamRequest_USM 0 "low beam not requested" 1 "low beam requested";
VAL_ 1143 PassengerDoorState 0 "Unavailable Value" 1 "Passenger door closed" 2 "Passenger door open" 3 "Not used";
VAL_ 1143 RearLeftDoorState 0 "Unavailable Value" 1 "Rear left door closed" 2 "Rear left door open" 3 "Not Used";
VAL_ 1144 ETAKickDetected 0 "No request" 1 "Kick detected";
VAL_ 1144 TailGateButtonPushed 0 "Unvailable Value" 1 "No TailGate Button is Pushed" 2 "TailGate Button is Pushed" 3 "Not Used";
VAL_ 1144 WakeUpType 0 "Full Wake-Up Mode" 1 "Selective Wake-Up Mode 1" 2 "Selective Wake-Up Mode 2" 3 "Selective Wake-Up Mode 3" 4 "Selective Wake-Up Mode 4" 5 "Selective Wake-Up Mode 5" 6 "Selective Wake-Up Mode 6" 7 "Unavailable";
VAL_ 1144 BCM_WakeUpSleepCommand 0 "Go to Sleep" 1 "reserved" 2 "reserved" 3 "WakeUp";
VAL_ 1144 RearDefrostEngaged 0 "Rear Defrost not engaged" 1 "Rear Defrost engaged";
VAL_ 1144 PositionLightsRequest 0 "position lights not requested" 1 "position lights requested";
VAL_ 1144 FrontFogLightsRequest 0 "front fog lights not requested" 1 "front fog lights requested";
VAL_ 1144 OriginOfVehOutsideLockedChangev2 0 "Unknown origin" 1 "By yale locker" 2 "By RKE" 3 "By Handfree (side doors or backdoor)" 4 "By WAC" 5 "By Approach Unlock" 6 "By Auto Relock Timeout" 7 "By Back-up lock (long press on CDL)" 8 "By Car Sharing" 9 "By ETA" 10 "By Authent" 11 "Not used" 12 "Not used" 13 "Not used" 14 "Not used" 15 "Not used";
VAL_ 1144 PTCNumberThermalStatus 0 "0 PTC activated" 1 "1 PTC activated" 2 "2 PTC activated" 3 "3 PTC activated" 4 "4 PTC activated" 5 "5 PTC activated" 6 "6 PTC activated" 7 "7 PTC activated" 8 "8 PTC activated" 9 "9 PTC activated" 10 "10 PTC activated" 11 "Not used" 12 "Not used" 13 "Not used" 14 "Not used" 15 "Unavailable";
VAL_ 1144 DriverDoorLockedStatus 0 "Driver Door Unlocked" 1 "Driver Door Locked";
VAL_ 1144 DayTimeRunningLightRequest 0 "Day time running light not requested" 1 "Day time running light request";
VAL_ 1144 HornRequest 0 "No Request" 1 "Horn OFF Request" 2 "Panic Horn Request" 3 "Lock Horn Request" 4 "Not used" 5 "Perimetric Alarm Horn Request" 6 "Silent Mode Deactivation Horn Request" 7 "Unavailable";
VAL_ 1144 HandFreeLockInhibition 0 "Hand Free Lock not inhibited" 1 "Hand Free Lock inhibited";
VAL_ 1144 WarningLightsStatus 0 "Warning Lights OFF" 1 "Warning Lights ON";
VAL_ 1144 VehicleOutsideLockedState 0 "Vehicle not locked from the outside by the customer" 1 "Vehicle Locked from the outside by the customer";
VAL_ 1144 DriverSidePosition 0 "Left side" 1 "Right side";
VAL_ 1144 DriverOutsideBuzzerRequest 0 "No Request" 1 "1 beep" 2 "2 beeps" 3 "Lock by WAC" 4 "Trunk opening" 5 "Refuse to Lock" 6 "Lock out Prevention Doors" 7 "Lock out Prevention Trunk" 8 "Buzzer Request by CIDMOWER" 9 "Buzzer Request by Keylock" 10 "Car Finder is requested" 11 "Not used" 12 "Not used" 13 "Not used" 14 "Not used" 15 "Not used";
VAL_ 1144 FrontDefrostEngaged 0 "Front Defrost not engaged" 1 "Front Defrost engaged";
VAL_ 1144 RearFogLightsRequest 0 "rear fog lights not requested" 1 "rear fog lights requested";
VAL_ 1144 BrakeLampStatus 0 "Brake Lamp Off" 1 "Brake Lamp On";
VAL_ 1144 HeadLampsWasherRequest 0 "headlamps washer not requested" 1 "headlamps washer requested";
VAL_ 1144 ESCLunlock_iKeyFobAuthent 0 "No request" 1 "Authent requested" 2 "Authent and Unlock requested" 3 "Unlock requested" 4 "Identification requested" 5 "Authentication by Kazashi and Unlock Request" 6 "Not used" 7 "Unavailable";
VAL_ 1145 SingleDoorOpeningActivationState 0 "Single door opening activated" 1 "Single door opening deactivated";
VAL_ 1145 BCM_PresoakRequest 0 "Immediat Presoak Request" 1 "Programmed Presoak Request" 2 "Presoak Stop" 3 "Unavailable";
VAL_ 1145 PTCThermalRegulatorFreeze 0 "No PTC thermal Regulator Freeze requested" 1 "PTC thermal Regulator Freeze requested";
VAL_ 1145 InsideIkeyfobCountRequest 0 "No Request (default value)" 1 "ikeyfob inside vehicle count request";
VAL_ 1145 ExternalWGS_Request 0 "No Request" 1 "Welcome Request" 2 "Good Bye Request" 3 "Function Deactivated";
VAL_ 1145 RearLightSignatureRequest 0 "No rear tail by day" 1 "Rear tail ON by day" 2 "Rear tail ON + police plate ON by day" 3 "Not used";
VAL_ 1145 ADB_AuthorizationRequest 0 "ADB not requested" 1 "ADB requested";
VAL_ 1145 TPMS_HornRequest 0 "No TPMS horn request" 1 "TPMS horn request";
VAL_ 1145 ProbableCustomerFeedBackNeed 0 "Customer feedback probably not needed" 1 "Customer feedback needed";
VAL_ 1145 DayNightSynthesis 0 "Day" 1 "Twilight" 2 "Night" 3 "Not used";
VAL_ 1145 BackDoorLockedStatus 0 "Back Door is Unlocked" 1 "Back Door is Locked";
VAL_ 1145 AutoLightingFunctionStatus 0 "Auto position off" 1 "Auto position on";
VAL_ 1145 IGN_SaverWarningAfterIGNOFF 0 "No Alert" 1 "Alert after IGN OFF";
VAL_ 1145 RearRightDoorLockedStatus 0 "Rear Right Door is Unlocked" 1 "Rear Right Door is Locked";
VAL_ 1145 RearLeftDoorLockedStatus 0 "Rear Left Door is Unlocked" 1 "Rear Left Door is Locked";
VAL_ 1145 PassengerDoorLockedStatus 0 "Passenger Door is Unlocked" 1 "Passenger Door is Locked";
VAL_ 1146 DriverSafetyBeltBuckleState 0 "SB Not monitored" 1 "SB unfastened" 2 "SB fastened" 3 "Unavailable";
VAL_ 1146 TailGateStatus 0 "Unvailable Value" 1 "TailGate is closed" 2 "TailGate is open" 3 "Not Used";
VAL_ 1146 VehicleStates 0 "Sleeping" 1 "Not used" 2 "CutoffPending" 3 "AutoACC  - BatTempoLevel" 4 "Not used" 5 "IgnitionLevel" 6 "StartingInProgress" 7 "PowertrainRunning" 8 "AutoStart" 9 "EngineSystemStop" 10 "Not used" 11 "Not used" 12 "Not used" 13 "Not used" 14 "Not used" 15 "Unavailable";
VAL_ 1146 BrakeInfoStatus 0 "Not used" 1 "Brake pedal not pressed" 2 "Brake pedal pressed" 3 "Not used" 4 "Brake pedal confirmed pressed" 5 "Not used" 6 "Not used" 7 "unavailable";
VAL_ 1146 DeliveryModeInformation_v2 0 "customer mode" 1 "delivery mode level 1" 2 "delivery mode level 2" 3 "Not used";
VAL_ 1146 FlashingIndicatorCommandPosition 0 "No direction indicator request" 1 "Left Flashing Indicators command ON" 2 "Right Flashing Indicators command ON" 3 "Not used";
VAL_ 1146 GADE_v2 0 "Sleep or Crank fault, Disable DiagMuxDTC" 1 "AutoACC fault, Disable DiagMuxDTC" 2 "ALL fault, Disable DiagMuxDTC" 3 "ALL fault, Enable DiagMuxDTC" 4 "FOTA switch fault, Disable DiagMuxDTC" 5 "Not used" 6 "Not used" 7 "Unavailable";
VAL_ 1146 FrontWiperStatus_BCM 0 "front wiper stopped" 1 "low speed active" 2 "high speed active" 3 "Unavailable";
VAL_ 1146 FrontWipingRequest 0 "front wiper in stop position" 1 "front wiper forced to stop" 2 "Not used" 3 "Not used" 4 "unavailable" 5 "Not used" 6 "low speed wiping requested" 7 "high speed wiping requested";
VAL_ 1146 HighBeamRequest 0 "high beam not requested" 1 "high beam requested";
VAL_ 1146 HighBeamPassingRequest 0 "no passing requested" 1 "High Beam passing requested";
VAL_ 1146 LowBeamRequest 0 "low beam not requested" 1 "low beam requested";
VAL_ 1146 Vehicle_ReadyToSleep 0 "Vehicle refuse to sleep" 1 "Vehicle almost ready to sleep";
VAL_ 1146 ClutchSwitchMaximumTravel 0 "Not used" 1 "Clutch pedal not pressed at maximum" 2 "Clutch pedal pressed at maximum" 3 "Unavailable";
VAL_ 1148 ERDC_Lock_Status_RR 0 "Lock" 1 "Unlock" 2 "Not used" 3 "Unavailable";
VAL_ 1148 ERDC_Lock_Status_FR 0 "Lock" 1 "Unlock" 2 "Not used" 3 "Unavailable";
VAL_ 1148 ERDC_IS_Open_SW_Status_RR 0 "No request" 1 "I/S SW open requested" 2 "Not used" 3 "Unavailable";
VAL_ 1148 ERDC_IS_Open_SW_Status_FR 0 "No request" 1 "I/S SW open requested" 2 "Not used" 3 "Unavailable";
VAL_ 1148 ERDC_R_RefuseToSleep 0 "reserved" 1 "eRDC_R refuse to sleep" 2 "eRDC_R ready to sleep" 3 "reserved";
VAL_ 1148 ERDC_R_RefuseToOpenAlertDisplay 0 "No Request" 1 "Request" 2 "Not used" 3 "Unavailable";
VAL_ 1148 ERDC_OS_Open_SW_Status_RR 0 "No request" 1 "O/S SW open requested" 2 "Not used" 3 "Unavailable";
VAL_ 1148 ERDC_OS_Open_SW_Status_FR 0 "No request" 1 "O/S SW open requested" 2 "Not used" 3 "Unavailable";
VAL_ 1148 Unlock_SW_Status_RR 0 "No request" 1 "Requested" 2 "Not used" 3 "Unavailable";
VAL_ 1148 Unlock_SW_Status_FR 0 "No request" 1 "Requested" 2 "Not used" 3 "Unavailable";
VAL_ 1148 Lock_SW_Status_RR 0 "No request" 1 "Requested" 2 "Not used" 3 "Unavailable";
VAL_ 1148 Lock_SW_Status_FR 0 "No request" 1 "Requested" 2 "Not used" 3 "Unavailable";
VAL_ 1148 eRDC_Auth_Inside_RR 0 "Authorize" 1 "Inhibit_VehicleLocked" 2 "Inhibit_Vehicle tempstop" 3 "Inhibit_VehicleRun" 4 "Inhibit_Failure" 5 "Inhibit_ChildLock" 6 "Inhibit_OSE" 7 "Inhibit_crash" 8 "Not used" 9 "Not used" 10 "Not used" 11 "Not used" 12 "Not used" 13 "Not used" 14 "Not used" 15 "Unavailable";
VAL_ 1148 eRDC_Auth_Inside_FR 0 "Authorize" 1 "Inhibit_VehicleLocked" 2 "Inhibit_Vehicle tempstop" 3 "Inhibit_VehicleRun" 4 "Inhibit_Failure" 5 "Inhibit_ChildLock" 6 "Inhibit_OSE" 7 "Inhibit_crash" 8 "Not used" 9 "Not used" 10 "Not used" 11 "Not used" 12 "Not used" 13 "Not used" 14 "Not used" 15 "Unavailable";
VAL_ 1148 ERDC_R_RefuseToOpenAlertDisp_RER 0 "No Request" 1 "Request" 2 "Not used" 3 "Unavailable";
VAL_ 1148 ChildLockStatus_R 0 "Unlocked" 1 "Locked" 2 "Not used" 3 "Unavailable";
VAL_ 1152 ERDC_L_RefuseToSleep 0 "reserved" 1 "eRDC_L refuse to sleep" 2 "eRDC_L ready to sleep" 3 "reserved";
VAL_ 1152 ERDC_L_RefuseToOpenAlertDisplay 0 "No Request" 1 "Request" 2 "Not used" 3 "Unavailable";
VAL_ 1152 ERDC_IS_Open_SW_Status_RL 0 "No request" 1 "I/S SW open requested" 2 "Not used" 3 "Unavailable";
VAL_ 1152 ERDC_IS_Open_SW_Status_FL 0 "No request" 1 "I/S SW open requested" 2 "Not used" 3 "Unavailable";
VAL_ 1152 ERDC_OS_Open_SW_Status_RL 0 "No request" 1 "O/S SW open requested" 2 "Not used" 3 "Unavailable";
VAL_ 1152 ERDC_OS_Open_SW_Status_FL 0 "No request" 1 "O/S SW open requested" 2 "Not used" 3 "Unavailable";
VAL_ 1152 ERDC_Lock_Status_RL 0 "Lock" 1 "Unlock" 2 "Not used" 3 "Unavailable";
VAL_ 1152 ERDC_Lock_Status_FL 0 "Lock" 1 "Unlock" 2 "Not used" 3 "Unavailable";
VAL_ 1152 Unlock_SW_Status_RL 0 "No request" 1 "Requested" 2 "Not used" 3 "Unavailable";
VAL_ 1152 Unlock_SW_Status_FL 0 "No request" 1 "Requested" 2 "Not used" 3 "Unavailable";
VAL_ 1152 Lock_SW_Status_RL 0 "No request" 1 "Requested" 2 "Not used" 3 "Unavailable";
VAL_ 1152 Lock_SW_Status_FL 0 "No request" 1 "Requested" 2 "Not used" 3 "Unavailable";
VAL_ 1152 eRDC_Auth_Inside_RL 0 "Authorize" 1 "Inhibit_VehicleLocked" 2 "Inhibit_Vehicle tempstop" 3 "Inhibit_VehicleRun" 4 "Inhibit_Failure" 5 "Inhibit_ChildLock" 6 "Inhibit_OSE" 7 "Inhibit_crash" 8 "Not used" 9 "Not used" 10 "Not used" 11 "Not used" 12 "Not used" 13 "Not used" 14 "Not used" 15 "Unavailable";
VAL_ 1152 eRDC_Auth_Inside_FL 0 "Authorize" 1 "Inhibit_VehicleLocked" 2 "Inhibit_Vehicle tempstop" 3 "Inhibit_VehicleRun" 4 "Inhibit_Failure" 5 "Inhibit_ChildLock" 6 "Inhibit_OSE" 7 "Inhibit_crash" 8 "Not used" 9 "Not used" 10 "Not used" 11 "Not used" 12 "Not used" 13 "Not used" 14 "Not used" 15 "Unavailable";
VAL_ 1152 ERDC_L_RefuseToOpenAlertDisp_RER 0 "No Request" 1 "Request" 2 "Not used" 3 "Unavailable";
VAL_ 1152 ChildLockStatus_L 0 "Unlocked" 1 "Locked" 2 "Not used" 3 "Unavailable";
VAL_ 1161 MBL_FailureDetection 0 "No MBL failure" 1 "MBL failure";
VAL_ 1161 MBLfailureDisplay 0 "No display" 1 "MBL failure display";
VAL_ 1175 LDW_SystemStatus_EDR 0 "Off" 1 "Faulted" 2 "On but not warning" 3 "On - Warning left" 4 "On - Warning right" 5 "Reserved" 6 "Reserved" 7 "Reserved";
VAL_ 1175 AutoCommand_SteeringStatusA_EDR 0 "Off" 1 "Faulted" 2 "Stand-By" 3 "Active" 4 "Reserved" 5 "Reserved" 6 "Reserved" 7 "Reserved";
VAL_ 1175 PLC_ParkingModeRequest2_EDR 0 "NoParking_Mode" 1 "AutoParking_Mode" 2 "RemoteParking_Mode" 3 "Not Used";
VAL_ 1175 AD_Map_Status_EDR 0 "HD Map Not Available" 1 "HD Map Available" 2 "Reserved" 3 "Reserved";
VAL_ 1175 Emergency_SteeringStatus_EDR 0 "Off" 1 "Faulted" 2 "On but not Engaged" 3 "Engaged" 4 "Reserved" 5 "Reserved" 6 "Reserved" 7 "Reserved";
VAL_ 1175 Corrective_SteeringStatus_EDR 0 "Off" 1 "Faulted" 2 "On but not Engaged" 3 "Engaged" 4 "Reserved" 5 "Reserved" 6 "Reserved" 7 "Reserved";
VAL_ 1175 AD_Control_Status_EDR 0 "Safety Shield Off" 1 "Safety Shield On" 2 "ICC Standby" 3 "ICC On LKA Inhibit" 4 "ICC On LKA Allowed" 5 "Hands Off Prohibited" 6 "Hands Off Alert" 7 "Steering Request Hands On" 8 "Pre Transition Demand  AD1" 9 "Transition Demand AD1" 10 "MRM AD1" 11 "MRM AD1 Stop" 12 "Hands Off Prohibited during Lane Change" 13 "Hands Off Alert during Lane Change" 14 "Hands Off Allowed" 15 "Driver Monitor Alert" 16 "Hands On Request before Lane Change" 17 "Hands On Request" 18 "Steering Request" 19 "PreTD AD2" 20 "TD AD2 by Driver Operation" 21 "TD AD2 except Driver Operation" 22 "MRM_AD2" 23 "MRM_AD2_Stop" 24 "Reserved" 25 "Reserved" 26 "Reserved" 27 "Reserved" 28 "Reserved" 29 "Reserved" 30 "Reserved" 31 "Reserved";
VAL_ 1175 AutoCommand_SteeringStatusB1_EDR 0 "Off" 1 "Faulted" 2 "Stand-By" 3 "Active" 4 "Reserved" 5 "Reserved" 6 "Reserved" 7 "Reserved";
VAL_ 1175 AD_Lane_Change_Status_EDR 0 "No Lane Change" 1 "General Lane Change (Except below LC)" 2 "Lane Change to overtake" 3 "Lane Change to return from overtaking" 4 "Lane change to enter a merging lane" 5 "Lane change to a fork" 6 "Lane change by driver trigger" 7 "Reserved" 8 "Reserved" 9 "Not used" 10 "Not used" 11 "Not used" 12 "Not used" 13 "Not used" 14 "Not used" 15 "Not used";
VAL_ 1175 AutoCommand_SteeringStatusE_EDR 0 "Off" 1 "Faulted" 2 "Stand-By" 3 "Active" 4 "Reserved" 5 "Reserved" 6 "Reserved" 7 "Reserved";
VAL_ 1175 AD_Lane_Change_Setting_EDR 0 "Approval for each lane change" 1 "Batch approval for multiple lane change";
VAL_ 1175 AD_Additional_Info_EDR 0 "Reserved for EDR" 1 "Reserved for EDR" 2 "Reserved for EDR" 3 "Reserved for EDR" 4 "Reserved for EDR" 5 "Reserved for EDR" 6 "Reserved for EDR" 7 "Reserved for EDR" 8 "Reserved for EDR" 9 "Reserved for EDR" 10 "Reserved for EDR" 11 "Reserved for EDR" 12 "Reserved for EDR" 13 "Reserved for EDR" 14 "Reserved for EDR" 15 "Reserved for EDR" 16 "Reserved for EDR" 17 "Reserved for EDR" 18 "Reserved for EDR" 19 "Reserved for EDR" 20 "Reserved for EDR" 21 "Reserved for EDR" 22 "Reserved for EDR" 23 "Reserved for EDR" 24 "Reserved for EDR" 25 "Reserved for EDR" 26 "Reserved for EDR" 27 "Reserved for EDR" 28 "Reserved for EDR" 29 "Reserved for EDR" 30 "Reserved for EDR" 31 "Reserved for EDR" 32 "Reserved for EDR" 33 "Reserved for EDR" 34 "Reserved for EDR" 35 "Reserved for EDR" 36 "Reserved for EDR" 37 "Reserved for EDR" 38 "Reserved for EDR" 39 "Reserved for EDR" 40 "Reserved for EDR" 41 "Reserved for EDR" 42 "Reserved for EDR" 43 "Reserved for EDR" 44 "Reserved for EDR" 45 "Reserved for EDR" 46 "Reserved for EDR" 47 "Reserved for EDR" 48 "Reserved for EDR" 49 "Reserved for EDR" 50 "Reserved for EDR" 51 "Reserved for EDR" 52 "Reserved for EDR" 53 "Reserved for EDR" 54 "Reserved for EDR" 55 "Reserved for EDR" 56 "Reserved for EDR" 57 "Reserved for EDR" 58 "Reserved for EDR" 59 "Reserved for EDR" 60 "Reserved for EDR" 61 "Reserved for EDR" 62 "Reserved for EDR" 63 "Reserved for EDR" 64 "Reserved for EDR" 65 "Reserved for EDR" 66 "Reserved for EDR" 67 "Reserved for EDR" 68 "Reserved for EDR" 69 "Reserved for EDR" 70 "Reserved for EDR" 71 "Reserved for EDR" 72 "Reserved for EDR" 73 "Reserved for EDR" 74 "Reserved for EDR" 75 "Reserved for EDR" 76 "Reserved for EDR" 77 "Reserved for EDR" 78 "Reserved for EDR" 79 "Reserved for EDR" 80 "Reserved for EDR" 81 "Reserved for EDR" 82 "Reserved for EDR" 83 "Reserved for EDR" 84 "Reserved for EDR" 85 "Reserved for EDR" 86 "Reserved for EDR" 87 "Reserved for EDR" 88 "Reserved for EDR" 89 "Reserved for EDR" 90 "Reserved for EDR" 91 "Reserved for EDR" 92 "Reserved for EDR" 93 "Reserved for EDR" 94 "Reserved for EDR" 95 "Reserved for EDR" 96 "Reserved for EDR" 97 "Reserved for EDR" 98 "Reserved for EDR" 99 "Reserved for EDR" 100 "Reserved for EDR" 101 "Reserved for EDR" 102 "Reserved for EDR" 103 "Reserved for EDR" 104 "Reserved for EDR" 105 "Reserved for EDR" 106 "Reserved for EDR" 107 "Reserved for EDR" 108 "Reserved for EDR" 109 "Reserved for EDR" 110 "Reserved for EDR" 111 "Reserved for EDR" 112 "Reserved for EDR" 113 "Reserved for EDR" 114 "Reserved for EDR" 115 "Reserved for EDR" 116 "Reserved for EDR" 117 "Reserved for EDR" 118 "Reserved for EDR" 119 "Reserved for EDR" 120 "Reserved for EDR" 121 "Reserved for EDR" 122 "Reserved for EDR" 123 "Reserved for EDR" 124 "Reserved for EDR" 125 "Reserved for EDR" 126 "Reserved for EDR" 127 "Reserved for EDR";
VAL_ 1175 AutoCommand_SteeringStatusC_EDR 0 "Off" 1 "Faulted" 2 "Stand-By" 3 "Active" 4 "Reserved" 5 "Reserved" 6 "Reserved" 7 "Reserved";
VAL_ 1175 AutoCommand_SteeringStatusB2_EDR 0 "Off" 1 "Faulted" 2 "Stand-By" 3 "Active" 4 "Reserved" 5 "Reserved" 6 "Reserved" 7 "Reserved";
VAL_ 1175 AutoCommand_SteeringStatusD_EDR 0 "Off" 1 "Faulted" 2 "Stand-By" 3 "Active" 4 "Reserved" 5 "Reserved" 6 "Reserved" 7 "Reserved";
VAL_ 1176 AEB_SystemStatus_EDR 0 "Deactivated" 1 "Faulted" 2 "On but Non-engaged" 3 "Warning but Non-engaged" 4 "Engaged" 5 "Reserved" 6 "Reserved" 7 "Reserved";
VAL_ 1178 PresenceStateRow2RightCollision 0 "Crash Not Detected" 1 "Absent" 2 "Present" 3 "Unknown";
VAL_ 1178 PresenceStateRow2LeftCollision 0 "Crash Not Detected" 1 "Absent" 2 "Present" 3 "Unknown";
VAL_ 1178 PresenceStateRow2CenterCollision 0 "Crash Not Detected" 1 "Absent" 2 "Present" 3 "Unknown";
VAL_ 1178 PresenceStateRow1PassCollision 0 "Crash Not Detected" 1 "Absent" 2 "Present" 3 "Unknown";
VAL_ 1178 SeatBeltStatusRow2CnterCollision 0 "SB Not monitored" 1 "SB unfastened" 2 "SB fastened" 3 "Unavailable";
VAL_ 1178 PresenceStateRow3RightCollision 0 "Crash Not Detected" 1 "Absent" 2 "Present" 3 "Unknown";
VAL_ 1178 PresenceStateRow3LeftCollision 0 "Crash Not Detected" 1 "Absent" 2 "Present" 3 "Unknown";
VAL_ 1178 PresenceStateRow3CenterCollision 0 "Crash Not Detected" 1 "Absent" 2 "Present" 3 "Unknown";
VAL_ 1178 SeatBeltStatusRow3LeftCollision 0 "SB Not monitored" 1 "SB unfastened" 2 "SB fastened" 3 "Unavailable";
VAL_ 1178 SeatBeltStatusRow3CnterCollision 0 "SB Not monitored" 1 "SB unfastened" 2 "SB fastened" 3 "Unavailable";
VAL_ 1178 SeatBeltStatusRow2RightCollision 0 "SB Not monitored" 1 "SB unfastened" 2 "SB fastened" 3 "Unavailable";
VAL_ 1178 SeatBeltStatusRow2LeftCollision 0 "SB Not monitored" 1 "SB unfastened" 2 "SB fastened" 3 "Unavailable";
VAL_ 1178 VRUCrashType 0 "VRU Crash Not Detected" 1 "Not Used" 2 "Motorcyclist" 3 "Bicyclist" 4 "Pedestrian" 5 "Unknown" 6 "Not Used" 7 "Not Used";
VAL_ 1178 VRUCrashDetectionAvailability 0 "VRU Crash Detection Unavailable" 1 "VRU Crash Deteciton Operational";
VAL_ 1178 SeatBeltStatusRow3RightCollision 0 "SB Not monitored" 1 "SB unfastened" 2 "SB fastened" 3 "Unavailable";
VAL_ 1185 EVBypassDiag 0 "No error" 1 "Short circuit to ground" 2 "Short circuit to supply" 3 "Open Circuit";
VAL_ 1185 EV3waysDiag 0 "No error" 1 "Short circuit to ground" 2 "Short circuit to supply" 3 "Open Circuit";
VAL_ 1185 MeterLossCanCom_HVAC 0 "Not tested" 1 "Tested OK" 2 "Tested NOK" 3 "Disabled";
VAL_ 1185 LowACChargeDetected 0 "Not tested" 1 "Tested OK" 2 "Tested NOK" 3 "Disabled";
VAL_ 1185 ECMLossCanCom_HVAC 0 "Not tested" 1 "Tested OK" 2 "Tested NOK" 3 "Disabled";
VAL_ 1185 HotSourceRightDiag 0 "No Failure" 1 "Open or short circuit to power" 2 "Short circuit to ground" 3 "Out of range low" 4 "Out of range high" 5 "Reserved" 6 "Reserved" 7 "Reserved";
VAL_ 1185 HotSourceLeftDiag 0 "No Failure" 1 "Open or short circuit to power" 2 "Short circuit to ground" 3 "Out of range low" 4 "Out of range high" 5 "Reserved" 6 "Reserved" 7 "Reserved";
VAL_ 1185 HVPTCLossLinCom_HVAC 0 "Not tested" 1 "Tested OK" 2 "Tested NOK" 3 "Disabled";
VAL_ 1185 TsSensorDiag 0 "No Failure" 1 "Open or short circuit to power" 2 "Short circuit to ground" 3 "Out of range low" 4 "Out of range high" 5 "Reserved" 6 "Reserved" 7 "Reserved";
VAL_ 1185 TdSensorDiag 0 "No Failure" 1 "Open or short circuit to power" 2 "Short circuit to ground" 3 "Out of range low" 4 "Out of range high" 5 "Reserved" 6 "Reserved" 7 "Reserved";
VAL_ 1185 EVLossLinCom_HVAC 0 "Not tested" 1 "Tested OK" 2 "Tested NOK" 3 "Disable";
VAL_ 1185 eCompLossLinCom_HVAC 0 "Not tested" 1 "Tested OK" 2 "Tested NOK" 3 "Disabled";
VAL_ 1185 HEVCLossCanCom_HVAC 0 "Not tested" 1 "Tested OK" 2 "Tested NOK" 3 "Disabled";
VAL_ 1185 HeatingForbiddenByHPCU 0 "Heating with heat pump available" 1 "Heating with heat pump not available (failure)";
VAL_ 1185 BattCoolingForbiddenByHPCU 0 "Battery cooling available" 1 "Battery cooling not available (failure)";
VAL_ 1185 HVPTCBattLossLinCom_HVAC 0 "Not tested" 1 "Tested OK" 2 "Tested NOK" 3 "Disabled";
VAL_ 1189 UserIdentification_IKeyLink_v2 0 "No request" 1 "Key No. 1" 2 "Key No. 2" 3 "Key No. 3" 4 "Key No. 4" 5 "Owner Key" 6 "Friend Key ID 1" 7 "Friend Key ID 2" 8 "Friend Key ID 3" 9 "Friend Key ID 4" 10 "Friend Key ID 5" 11 "Not used" 12 "Not used" 13 "Not used" 14 "Not used" 15 "Unavailable";
VAL_ 1189 Left_iKeyFobAuthent_Req_V2 0 "No request" 1 "Left Authent request";
VAL_ 1189 Right_iKeyFobAuthent_Req_V2 0 "No request" 1 "Right Authent request";
VAL_ 1191 VADA_SystemMode 0 "Soft" 1 "Normal" 2 "Dynamic" 3 "Unavailable";
VAL_ 1202 APA_CancelReason 0 "no display" 1 "APA Permanent Failure" 2 "Parking Sensor Permanent Failure" 3 "Not Used";
VAL_ 1202 RPK_LedStatusRequest 0 "OFF" 1 "Pattern1" 2 "Pattern2" 3 "Pattern3" 4 "Pattern4" 5 "Pattern5" 6 "Not Used" 7 "Not Used";
VAL_ 1204 AC_FlapFrontRightDistriPosition 0 "Unavailable" 1 "Feet" 2 "Aerator" 3 "Feet + Aerator" 4 "Mild flow" 5 "Feet + Mild flow" 6 "Feet + Aerator Mild flow" 7 "Defrost" 8 "Feet + Defrost" 9 "Aerator + Defrost" 10 "Feet + Aerator + Defrost" 11 "Mild flow + Defrost State" 12 "Feet + Mild flow + Defrost" 13 "Aerator + Mild flow + Defrost" 14 "Feet + Aerator + Mild flow + Defrost" 15 "Not used";
VAL_ 1204 AC_FlapFrontLeftDistriPosition 0 "Unavailable" 1 "Feet" 2 "Aerator" 3 "Feet + Aerator" 4 "Mild flow" 5 "Feet + Mild flow" 6 "Feet + Aerator Mild flow" 7 "Defrost" 8 "Feet + Defrost" 9 "Aerator + Defrost" 10 "Feet + Aerator + Defrost" 11 "Mild flow + Defrost State" 12 "Feet + Mild flow + Defrost" 13 "Aerator + Mild flow + Defrost" 14 "Feet + Aerator + Mild flow + Defrost" 15 "Not used";
VAL_ 1205 AC_ECOmodeAuthorized 0 "Unavailable" 1 "ECO mode authorized by AC" 2 "ECO mode forbidden by AC" 3 "Not used";
VAL_ 1205 AC_ECOmodeActivationState 0 "Unavailable" 1 "ECO mode activated" 2 "ECO mode deactivated" 3 "Not used";
VAL_ 1205 WindowFoggingLevel 0 "fogging_level_0" 1 "fogging_level_1" 2 "fogging_level_2" 3 "fogging_level_3";
VAL_ 1205 DefoggingModeStatus 0 "normal mode" 1 "window defogging mode" 2 "fail mode" 3 "Customer controls HVAC SW Auto" 4 "Customer controls HVAC SW manual" 5 "Not Used" 6 "Not Used" 7 "Not Used";
VAL_ 1206 HVAC2_PressureACCut 0 "Normal" 1 "Low cut" 2 "High cut" 3 "Unavailable";
VAL_ 1206 HVAC2_FlapIntakeRequest 0 "No request" 1 "Recycle request" 2 "Fresh request" 3 "Unavailable";
VAL_ 1206 HVAC2_eACstatus 0 "Not over" 1 "Over level 1" 2 "Over level 2" 3 "Unavailable";
VAL_ 1206 HVAC2_ClimLoopMode 0 "Unavailable" 1 "A/C Mode" 2 "A/C de-icing mode" 3 "Heat pump mode" 4 "Demisting mode" 5 "Idle mode" 6 "Not used" 7 "Not used";
VAL_ 1225 VehicleInsideKeyIdentRequest 0 "No Request" 1 "ID1 Ident Request" 2 "ID2 Ident Request" 3 "ID3 Ident Request" 4 "ID4 Ident Request" 5 "VK_ID1 Ident Request" 6 "VK_ID2 Ident Request" 7 "VK_ID3 Ident Request" 8 "VK_ID4 Ident Request" 9 "VK_ID5 Ident Request" 10 "VK_ID6 Ident Request" 11 "Not used" 12 "Not used" 13 "Not used" 14 "Not used" 15 "Not used";
VAL_ 1225 RearZonePollingRequest 0 "No Request" 1 "Start Polling" 2 "Stop Polling" 3 "Not Used";
VAL_ 1225 OutsideZoneKeyIdentRequest 0 "No Request" 1 "Request";
VAL_ 1225 OutsideZonePollingRequest 0 "No Request" 1 "Start Polling" 2 "Stop Polling" 3 "Not Used";
VAL_ 1231 ADB_StreetLights 0 "OFF" 1 "ON";
VAL_ 1231 ADB_BrightScene 0 "OFF" 1 "ON";
VAL_ 1231 ADB_LitNight 0 "OFF" 1 "ON";
VAL_ 1232 HVbatWaterCircuitStatus 0 "Normal (Battery and PWT circuit separated)" 1 "Cooling by Chiller" 2 "Heating Recovery" 3 "Heating by PTC" 4 "Battery Range Boost" 5 "Cooling by Radiator" 6 "Heating Recovery without Battery" 7 "Heating Recovery without e-PT" 8 "Heating by daxis discharge" 9 "Not used" 10 "Not used" 11 "Not used" 12 "Not used" 13 "Not used" 14 "Not used" 15 "Unavailable";
VAL_ 1233 MotorShow_Request 0 "Not activated" 1 "Activated";
VAL_ 1233 RearLightingSignatureRequest 0 "Rearlighting signature1" 1 "Rearlighting signature2" 2 "Rearlighting signature3" 3 "Rearlighting signature4" 4 "Rearlighting signature5" 5 "Rearlighting signature6" 6 "Rearlighting signature7" 7 "Rearlighting signature8" 8 "Rearlighting signature9" 9 "Rearlighting signature10" 10 "Rearlighting signature11" 11 "Rearlighting signature12" 12 "Rearlighting signature13" 13 "Rearlighting signature14" 14 "Rearlighting signature15" 15 "Rearlighting signature16";
VAL_ 1233 FrontLightingSignatureRequest 0 "Frontlighting signature1" 1 "Frontlighting signature2" 2 "Frontlighting signature3" 3 "Frontlighting signature4" 4 "Frontlighting signature5" 5 "Frontlighting signature6" 6 "Frontlighting signature7" 7 "Frontlighting signature8" 8 "Frontlighting signature9" 9 "Frontlighting signature10" 10 "Frontlighting signature11" 11 "Frontlighting signature12" 12 "Frontlighting signature13" 13 "Frontlighting signature14" 14 "Frontlighting signature15" 15 "Frontlighting signature16";
VAL_ 1233 Open_Authent_result_RR 0 "No Answer" 1 "Open Authorized RR(rear right door)" 2 "Not used" 3 "Unavailable";
VAL_ 1233 Showroom_Request 0 "Not activated" 1 "Activated";
VAL_ 1233 RearWasherPumpActivationReq 0 "rear washer pump not requested" 1 "rear washer pump requested";
VAL_ 1233 FrontWasherPumpActivationReq 0 "front washer pump not requested" 1 "front washer pump requested";
VAL_ 1233 LIDARWasherPumpRequest 0 "No request" 1 "Pump activation request";
VAL_ 1233 HazardLampStatus 0 "HazardLamp OFF" 1 "HazardLamp ON";
VAL_ 1233 AllWeather_Request 0 "AllWeather is not requested" 1 "AllWeather is requested" 2 "Not used" 3 "Unavailable";
VAL_ 1233 FirstStartDeviceSelection 0 "No selection" 1 "Starter selected" 2 "BSG selected" 3 "Not used";
VAL_ 1233 FlashingIndicatorActivationState 0 "Left and Right Flashing Not Activated" 1 "Left Flashing Activated" 2 "Right Flashing Activated" 3 "Not used";
VAL_ 1233 Open_Authent_result_RL 0 "No Answer" 1 "Open Authorized RL(rear left door)" 2 "Not used" 3 "Unavailable";
VAL_ 1233 Open_Authent_result_FR 0 "No Answer" 1 "Open Authorized FR(front right door)" 2 "Not used" 3 "Unavailable";
VAL_ 1233 Open_Authent_result_FL 0 "No Answer" 1 "Open Authorized FL(front left door)" 2 "Not used" 3 "Unavailable";
VAL_ 1241 CustomerIdentType 0 "Card" 1 "Personal Device";
VAL_ 1250 e_EXP_Valve_Stuck_Diagnosis 0 "Unavailable" 1 "Open" 2 "Short" 3 "Not Used";
VAL_ 1250 e_EXP_Valve_Diagnosis_Status 0 "diagnosis not started" 1 "diagnosis on going" 2 "diagnosis finished" 3 "diagnosis unavailable";
VAL_ 1250 ON_OFF_Valve_Stuck_Diagnosis 0 "Unavailable" 1 "Open" 2 "Short" 3 "Not Used";
VAL_ 1250 Compressor_Diagnosis_Status 0 "diagnosis not started" 1 "diagnosis on going" 2 "diagnosis finished" 3 "diagnosis unavailable";
VAL_ 1250 Compr_Interface_Error_Status 0 "diagnosis not started" 1 "diagnosis on going" 2 "diagnosis finished" 3 "diagnosis unavailable";
VAL_ 1250 Compr_Sensor_Error_status 0 "diagnosis not started" 1 "diagnosis on going" 2 "diagnosis finished" 3 "diagnosis unavailable";
VAL_ 1250 Compr_Internal_Error_Status 0 "diagnosis not started" 1 "diagnosis on going" 2 "diagnosis finished" 3 "diagnosis unavailable";
VAL_ 1250 ClimBox_Diagnosis_Status 0 "diagnosis not started" 1 "diagnosis on going" 2 "diagnosis finished" 3 "diagnosis unavailable";
VAL_ 1250 WaterTempHVCHDiag 0 "No Failure" 1 "Open circuit" 2 "Short circuit to ground" 3 "Short circuit to supply" 4 "Out of range low" 5 "Out of range high" 6 "Reserved" 7 "Reserved";
VAL_ 1250 Teva_Air_Sens_Diag 0 "unavailable" 1 "open circuit" 2 "short circuit" 3 "out of range low" 4 "out of range high" 5 "Reserved" 6 "Reserved" 7 "Reserved";
VAL_ 1250 Teva_Air_Sens_Diag_Status 0 "diagnosis complete" 1 "diagnosis on going" 2 "failure deteted" 3 "no failure";
VAL_ 1250 Compr_Inverter_Over_Heat_status 0 "diagnosis not started" 1 "diagnosis on going" 2 "diagnosis finished" 3 "diagnosis unavailable";
VAL_ 1250 Compr_Sensor_Error_diagnosis 0 "No error" 1 "Temperature-sensor error" 2 "Current-sensor error" 3 "Reserved";
VAL_ 1250 Compr_Internal_Error_diagnosis 0 "No error" 1 "Output Line Short circuit" 2 "Output Line Open circuit" 3 "Over Load" 4 "Abnormal Run-up" 5 "Reserved" 6 "Reserved" 7 "CPU error";
VAL_ 1250 Loss_of_BMS_Information 0 "No Error" 1 "CAN Error";
VAL_ 1250 Climbox_CAN_failure_with_HEVC 0 "No Error" 1 "CAN Error";
VAL_ 1250 Compr_Inverter_over_Heating_diag 0 "No overheating" 1 "Overheating";
VAL_ 1250 Compr_Inverter_High_Temp_diag 0 "No temperature derating" 1 "temperature derating";
VAL_ 1250 Compr_Over_Load_Warning_diag 0 "No error" 1 "Over Load Warning (Area1)" 2 "Over Load Warning (Area2)" 3 "Low Speed Over Load";
VAL_ 1250 Compr_Motor_Control_Fault_diag 0 "No error" 1 "Start Fail" 2 "Software Over Current" 3 "Reserved";
VAL_ 1250 Compr_Interface_Error_diagnosis 0 "No error" 1 "Internal Interface error";
VAL_ 1250 Compr_LIN_Communication_Status 0 "diagnosis not started" 1 "diagnosis on going" 2 "diagnosis finished" 3 "diagnosis unavailable";
VAL_ 1250 Compr_Inverter_High_Temp_Status 0 "diagnosis not started" 1 "diagnosis on going" 2 "diagnosis finished" 3 "diagnosis unavailable";
VAL_ 1250 Compr_Over_Load_Warning_Status 0 "diagnosis not started" 1 "diagnosis on going" 2 "diagnosis finished" 3 "diagnosis unavailable";
VAL_ 1250 Compr_Motor_Control_Fault_status 0 "diagnosis not started" 1 "diagnosis on going" 2 "diagnosis finished" 3 "diagnosis unavailable";
VAL_ 1250 Incar_Sens_Diag_Status 0 "diagnosis complete" 1 "diagnosis on going" 2 "failure detected" 3 "no failure";
VAL_ 1250 Incar_Sens_Diag 0 "unavailable" 1 "open circuit" 2 "short circuit" 3 "out of range low" 4 "out of range high" 5 "Reserved" 6 "Reserved" 7 "Reserved";
VAL_ 1250 Compr_LIN_Error_diagnosis 0 "No Error" 1 "LIN Error";
VAL_ 1250 Climbox_LIN_Failure_with_Compr 0 "No Error" 1 "LIN Error";
VAL_ 1255 BatteryCool_eACLimitStatus_IVI 0 "No request" 1 "Uncap request" 2 "No uncap request" 3 "Not used";
VAL_ 1257 ACCompValveDiag 0 "No error" 1 "Short circuit to ground" 2 "Short circuit to battery or open circuit" 3 "Not used";
VAL_ 1257 ACCompClutchDiag 0 "No error" 1 "Short circuit to ground" 2 "Short circuit to battery or open circuit" 3 "Not used";
VAL_ 1258 Bat_Outlet_Temp_Sens_Diag 0 "No Failure" 1 "open" 2 "short" 3 "out of range low" 4 "out of range high" 5 "Reserved" 6 "Reserved" 7 "Reserved";
VAL_ 1258 Bat_Inlet_Temp_Sens_Diag 0 "No Failure" 1 "open" 2 "short" 3 "out of range low" 4 "out of range high" 5 "Reserved" 6 "Reserved" 7 "Reserved";
VAL_ 1258 HPCU_Diagnosis_Status 0 "diagnosis not started" 1 "diagnosis on going" 2 "diagnosis finished" 3 "diagnosis unavailable";
VAL_ 1258 Bat_Outlet_Temp_Sens_Diag_Status 0 "diagnosis not started" 1 "diagnosis on going" 2 "diagnosis finished" 3 "diagnosis unavailable";
VAL_ 1258 Bat_Inlet_Temp_Sens_Diag_Status 0 "diagnosis not started" 1 "diagnosis on going" 2 "diagnosis finished" 3 "diagnosis unavailable";
VAL_ 1258 EXVBattStatus 0 "No error" 1 "Stuck";
VAL_ 1258 BattCoolingValveState 0 "No error" 1 "Stuck";
VAL_ 1258 ChillerOutletTemperatureState 0 "No error" 1 "Open circuit" 2 "Short to GND" 3 "Short to 12V" 4 "Out of range Lo" 5 "Out of range Hi" 6 "Rationality1" 7 "Rationality2";
VAL_ 1258 HPCU_CANfailure_With_HVAC 0 "No Error" 1 "CAN Error";
VAL_ 1258 ON_OFF_Valve_Stuck_Diag_Status 0 "diagnosis not started" 1 "diagnosis on going" 2 "diagnosis finished" 3 "diagnosis unavailable";
VAL_ 1258 EVAPO_Ref_Temp_Sens_Diag 0 "unavailable" 1 "open circuit" 2 "short circuit" 3 "out of range low" 4 "out of range high" 5 "Rationality1" 6 "Rationality2" 7 "Reserved";
VAL_ 1258 EVAPO_Ref_Temp_Sens_Diag_Status 0 "diagnosis complete" 1 "diagnosis on going" 2 "failure detected" 3 "no failure";
VAL_ 1258 ChillerInletTemperatureState 0 "No error" 1 "Open circuit" 2 "Short to GND" 3 "Short to 12V" 4 "Out of range Lo" 5 "Out of range Hi" 6 "Rationality1" 7 "Rationality2";
VAL_ 1258 COND_eEXP_Valve_Stuck_Diagnosis 0 "Unavailable" 1 "Stuck Open" 2 "Stuck Close" 3 "Not Used";
VAL_ 1258 COND_eEXP_Valve_Diag_Status 0 "diagnosis complete" 1 "diagnosis on going" 2 "failure detected" 3 "no failure";
VAL_ 1258 EVAPO_eEXP_Valve_Stuck_Diagnosis 0 "unavailable" 1 "Stuck open" 2 "Stuck close" 3 "Not Used";
VAL_ 1258 EVAPO_eEXP_Valve_Diag_Status 0 "diagnosis complete" 1 "diagnosis on going" 2 "failure detected" 3 "no failure";
VAL_ 1265 HeatLoopWaterValveRequest_EVA 0 "Engine loop request" 1 "Short loop request";
VAL_ 1276 ACC_Status_Slow 0 "ACC OFF" 1 "ACC in take off" 2 "ACC in stop" 3 "ACC waiting" 4 "ACC suspended" 5 "ACC in brake only mode" 6 "ACC regulation" 7 "ACC driver override" 8 "ACC in failure State" 9 "Not used" 10 "Not used" 11 "Not used" 12 "Not used" 13 "Not used" 14 "Not used" 15 "Unavailable";
VAL_ 1279 ThirdRowLeftSeatAutoRequest 0 "No request" 1 "Auto mode activation" 2 "Auto mode deactivation" 3 "reset request";
VAL_ 1279 ThirdRowRightSeatAutoRequest 0 "No request" 1 "Auto mode activation" 2 "Auto mode deactivation" 3 "reset request";
VAL_ 1285 SteeringLockCode 0 "Table Value16338";
VAL_ 1285 ClearSteeringCode 0 "ESCL code not cleared" 1 "ESCL code cleared";
VAL_ 1285 Steering_Column_Lock 0 "steering column locking not requested" 1 "steering column locking  requested";
VAL_ 1285 Steering_Column_Unlock 0 "steering column unlocking not requested" 1 "steering column unlocking  requested";
VAL_ 1285 IgnitionON 0 "Primary Ignition Supply OFF" 1 "Primary Ignition Supply ON";
VAL_ 1285 BCMComputerOperatingProperly 0 "Table Value16339";
VAL_ 1296 TCU_DVR_Photo_Request 0 "no request" 1 "request";
VAL_ 1301 RemoteFunctionService_HFM_to_BLM 0 "Table Value29850";
VAL_ 1302 RemoteFunctionService_BLM_to_HFM 0 "Table Value29849";
VAL_ 1303 CamFrontDefrostRequest 0 "No Request" 1 "Defrost request";
